VERSION "ZCU_CANFD1"

NS_ :

BS_ :

BU_ :  ASDM BBM ETC IHU ZCUD ZCUP

BO_ 544 AdcuZCUCANFD1Fr14 : 64 ASDM
 SG_ VehObjforADB1_UB : 58|1@0+ (1,0) [0|1] "" IHU,ZCUD
 SG_ VehObjforADB1AdbAbsDist : 7|10@0+ (1.0,0.0) [0.0|1000.0] "m" IHU,ZCUD
 SG_ VehObjforADB1AdbClassn : 13|3@0+ (1,0) [0|7] "" IHU,ZCUD
 SG_ VehObjforADB1AdbHozlAgLe : 10|11@0+ (0.05,-40.0) [-40.0|40.0] "Deg" IHU,ZCUD
 SG_ VehObjforADB1AdbHozlAgRi : 31|11@0+ (0.05,-40.0) [-40.0|40.0] "Deg" IHU,ZCUD
 SG_ VehObjforADB1AdbObjDir : 36|2@0+ (1,0) [0|3] "" IHU,ZCUD
 SG_ VehObjforADB1AdbObjHozlAgSpdLe : 34|9@0+ (0.2,-50.0) [-50.0|52.2] "DegPerSec" IHU,ZCUD
 SG_ VehObjforADB1AdbObjHozlAgSpdRi : 41|9@0+ (0.2,-50.0) [-50.0|52.2] "DegPerSec" IHU,ZCUD
 SG_ VehObjforADB1AdbTrkInfo : 48|1@0+ (1,0) [0|1] "" IHU,ZCUD
 SG_ VehObjforADB1AdbVertAg : 63|5@0+ (0.5,-3.0) [-3.0|12.5] "Deg" IHU,ZCUD
 SG_ VehObjforADB2_UB : 57|1@0+ (1,0) [0|1] "" IHU,ZCUD
 SG_ VehObjforADB2AdbAbsDist : 71|10@0+ (1.0,0.0) [0.0|1000.0] "m" IHU,ZCUD
 SG_ VehObjforADB2AdbClassn : 77|3@0+ (1,0) [0|7] "" IHU,ZCUD
 SG_ VehObjforADB2AdbHozlAgLe : 74|11@0+ (0.05,-40.0) [-40.0|40.0] "Deg" IHU,ZCUD
 SG_ VehObjforADB2AdbHozlAgRi : 95|11@0+ (0.05,-40.0) [-40.0|40.0] "Deg" IHU,ZCUD
 SG_ VehObjforADB2AdbObjDir : 100|2@0+ (1,0) [0|3] "" IHU,ZCUD
 SG_ VehObjforADB2AdbObjHozlAgSpdLe : 98|9@0+ (0.2,-50.0) [-50.0|52.2] "DegPerSec" IHU,ZCUD
 SG_ VehObjforADB2AdbObjHozlAgSpdRi : 105|9@0+ (0.2,-50.0) [-50.0|52.2] "DegPerSec" IHU,ZCUD
 SG_ VehObjforADB2AdbTrkInfo : 112|1@0+ (1,0) [0|1] "" IHU,ZCUD
 SG_ VehObjforADB2AdbVertAg : 127|5@0+ (0.5,-3.0) [-3.0|12.5] "Deg" IHU,ZCUD
 SG_ VehObjforADB3_UB : 56|1@0+ (1,0) [0|1] "" IHU,ZCUD
 SG_ VehObjforADB3AdbAbsDist : 135|10@0+ (1.0,0.0) [0.0|1000.0] "m" IHU,ZCUD
 SG_ VehObjforADB3AdbClassn : 141|3@0+ (1,0) [0|7] "" IHU,ZCUD
 SG_ VehObjforADB3AdbHozlAgLe : 138|11@0+ (0.05,-40.0) [-40.0|40.0] "Deg" IHU,ZCUD
 SG_ VehObjforADB3AdbHozlAgRi : 159|11@0+ (0.05,-40.0) [-40.0|40.0] "Deg" IHU,ZCUD
 SG_ VehObjforADB3AdbObjDir : 164|2@0+ (1,0) [0|3] "" IHU,ZCUD
 SG_ VehObjforADB3AdbObjHozlAgSpdLe : 162|9@0+ (0.2,-50.0) [-50.0|52.2] "DegPerSec" IHU,ZCUD
 SG_ VehObjforADB3AdbObjHozlAgSpdRi : 169|9@0+ (0.2,-50.0) [-50.0|52.2] "DegPerSec" IHU,ZCUD
 SG_ VehObjforADB3AdbTrkInfo : 176|1@0+ (1,0) [0|1] "" IHU,ZCUD
 SG_ VehObjforADB3AdbVertAg : 191|5@0+ (0.5,-3.0) [-3.0|12.5] "Deg" IHU,ZCUD
 SG_ VehObjforADB4_UB : 122|1@0+ (1,0) [0|1] "" IHU,ZCUD
 SG_ VehObjforADB4AdbAbsDist : 199|10@0+ (1.0,0.0) [0.0|1000.0] "m" IHU,ZCUD
 SG_ VehObjforADB4AdbClassn : 205|3@0+ (1,0) [0|7] "" IHU,ZCUD
 SG_ VehObjforADB4AdbHozlAgLe : 202|11@0+ (0.05,-40.0) [-40.0|40.0] "Deg" IHU,ZCUD
 SG_ VehObjforADB4AdbHozlAgRi : 223|11@0+ (0.05,-40.0) [-40.0|40.0] "Deg" IHU,ZCUD
 SG_ VehObjforADB4AdbObjDir : 228|2@0+ (1,0) [0|3] "" IHU,ZCUD
 SG_ VehObjforADB4AdbObjHozlAgSpdLe : 226|9@0+ (0.2,-50.0) [-50.0|52.2] "DegPerSec" IHU,ZCUD
 SG_ VehObjforADB4AdbObjHozlAgSpdRi : 233|9@0+ (0.2,-50.0) [-50.0|52.2] "DegPerSec" IHU,ZCUD
 SG_ VehObjforADB4AdbTrkInfo : 240|1@0+ (1,0) [0|1] "" IHU,ZCUD
 SG_ VehObjforADB4AdbVertAg : 255|5@0+ (0.5,-3.0) [-3.0|12.5] "Deg" IHU,ZCUD
 SG_ VehObjforADB5_UB : 121|1@0+ (1,0) [0|1] "" IHU,ZCUD
 SG_ VehObjforADB5AdbAbsDist : 263|10@0+ (1.0,0.0) [0.0|1000.0] "m" IHU,ZCUD
 SG_ VehObjforADB5AdbClassn : 269|3@0+ (1,0) [0|7] "" IHU,ZCUD
 SG_ VehObjforADB5AdbHozlAgLe : 266|11@0+ (0.05,-40.0) [-40.0|40.0] "Deg" IHU,ZCUD
 SG_ VehObjforADB5AdbHozlAgRi : 287|11@0+ (0.05,-40.0) [-40.0|40.0] "Deg" IHU,ZCUD
 SG_ VehObjforADB5AdbObjDir : 292|2@0+ (1,0) [0|3] "" IHU,ZCUD
 SG_ VehObjforADB5AdbObjHozlAgSpdLe : 290|9@0+ (0.2,-50.0) [-50.0|52.2] "DegPerSec" IHU,ZCUD
 SG_ VehObjforADB5AdbObjHozlAgSpdRi : 297|9@0+ (0.2,-50.0) [-50.0|52.2] "DegPerSec" IHU,ZCUD
 SG_ VehObjforADB5AdbTrkInfo : 304|1@0+ (1,0) [0|1] "" IHU,ZCUD
 SG_ VehObjforADB5AdbVertAg : 319|5@0+ (0.5,-3.0) [-3.0|12.5] "Deg" IHU,ZCUD
 SG_ VehObjforADB6_UB : 120|1@0+ (1,0) [0|1] "" IHU,ZCUD
 SG_ VehObjforADB6AdbAbsDist : 327|10@0+ (1.0,0.0) [0.0|1000.0] "m" IHU,ZCUD
 SG_ VehObjforADB6AdbClassn : 333|3@0+ (1,0) [0|7] "" IHU,ZCUD
 SG_ VehObjforADB6AdbHozlAgLe : 330|11@0+ (0.05,-40.0) [-40.0|40.0] "Deg" IHU,ZCUD
 SG_ VehObjforADB6AdbHozlAgRi : 351|11@0+ (0.05,-40.0) [-40.0|40.0] "Deg" IHU,ZCUD
 SG_ VehObjforADB6AdbObjDir : 356|2@0+ (1,0) [0|3] "" IHU,ZCUD
 SG_ VehObjforADB6AdbObjHozlAgSpdLe : 354|9@0+ (0.2,-50.0) [-50.0|52.2] "DegPerSec" IHU,ZCUD
 SG_ VehObjforADB6AdbObjHozlAgSpdRi : 361|9@0+ (0.2,-50.0) [-50.0|52.2] "DegPerSec" IHU,ZCUD
 SG_ VehObjforADB6AdbTrkInfo : 368|1@0+ (1,0) [0|1] "" IHU,ZCUD
 SG_ VehObjforADB6AdbVertAg : 383|5@0+ (0.5,-3.0) [-3.0|12.5] "Deg" IHU,ZCUD
 SG_ VehObjforADB7_UB : 186|1@0+ (1,0) [0|1] "" IHU,ZCUD
 SG_ VehObjforADB7AdbAbsDist : 391|10@0+ (1.0,0.0) [0.0|1000.0] "m" IHU,ZCUD
 SG_ VehObjforADB7AdbClassn : 397|3@0+ (1,0) [0|7] "" IHU,ZCUD
 SG_ VehObjforADB7AdbHozlAgLe : 394|11@0+ (0.05,-40.0) [-40.0|40.0] "Deg" IHU,ZCUD
 SG_ VehObjforADB7AdbHozlAgRi : 415|11@0+ (0.05,-40.0) [-40.0|40.0] "Deg" IHU,ZCUD
 SG_ VehObjforADB7AdbObjDir : 420|2@0+ (1,0) [0|3] "" IHU,ZCUD
 SG_ VehObjforADB7AdbObjHozlAgSpdLe : 418|9@0+ (0.2,-50.0) [-50.0|52.2] "DegPerSec" IHU,ZCUD
 SG_ VehObjforADB7AdbObjHozlAgSpdRi : 425|9@0+ (0.2,-50.0) [-50.0|52.2] "DegPerSec" IHU,ZCUD
 SG_ VehObjforADB7AdbTrkInfo : 432|1@0+ (1,0) [0|1] "" IHU,ZCUD
 SG_ VehObjforADB7AdbVertAg : 447|5@0+ (0.5,-3.0) [-3.0|12.5] "Deg" IHU,ZCUD
 SG_ VehObjforADB8_UB : 185|1@0+ (1,0) [0|1] "" IHU,ZCUD
 SG_ VehObjforADB8AdbAbsDist : 455|10@0+ (1.0,0.0) [0.0|1000.0] "m" IHU,ZCUD
 SG_ VehObjforADB8AdbClassn : 461|3@0+ (1,0) [0|7] "" IHU,ZCUD
 SG_ VehObjforADB8AdbHozlAgLe : 458|11@0+ (0.05,-40.0) [-40.0|40.0] "Deg" IHU,ZCUD
 SG_ VehObjforADB8AdbHozlAgRi : 479|11@0+ (0.05,-40.0) [-40.0|40.0] "Deg" IHU,ZCUD
 SG_ VehObjforADB8AdbObjDir : 484|2@0+ (1,0) [0|3] "" IHU,ZCUD
 SG_ VehObjforADB8AdbObjHozlAgSpdLe : 482|9@0+ (0.2,-50.0) [-50.0|52.2] "DegPerSec" IHU,ZCUD
 SG_ VehObjforADB8AdbObjHozlAgSpdRi : 489|9@0+ (0.2,-50.0) [-50.0|52.2] "DegPerSec" IHU,ZCUD
 SG_ VehObjforADB8AdbTrkInfo : 496|1@0+ (1,0) [0|1] "" IHU,ZCUD
 SG_ VehObjforADB8AdbVertAg : 511|5@0+ (0.5,-3.0) [-3.0|12.5] "Deg" IHU,ZCUD

BO_ 1129 AdcuZCUCANFD1Fr15 : 64 ASDM
 SG_ FrntRdrSts_UB : 267|1@0+ (1,0) [0|1] "" IHU
 SG_ FrntRdrStsRdrNrDetn : 231|8@0+ (1.0,0.0) [0.0|255.0] "Unitless" IHU
 SG_ FrntRdrStsRdrNrObj : 239|8@0+ (1.0,0.0) [0.0|255.0] "Unitless" IHU
 SG_ FrntRdrStsRdrStsBlkd0bin : 240|1@0+ (1,0) [0|1] "" IHU
 SG_ FrntRdrStsRdrStsBlkdConf : 247|7@0+ (1.0,0.0) [0.0|100.0] "%" IHU
 SG_ FrntRdrStsRdrStsChks : 159|8@0+ (1.0,0.0) [0.0|255.0] "Unitless" IHU
 SG_ FrntRdrStsRdrStsCntr : 167|4@0+ (1.0,0.0) [0.0|15.0] "Unitless" IHU
 SG_ FrntRdrStsRdrStsDstbc : 263|7@0+ (1.0,0.0) [0.0|100.0] "%" IHU
 SG_ FrntRdrStsRdrStsEna : 256|1@0+ (1,0) [0|1] "" IHU
 SG_ FrntRdrStsRdrStsFaulty : 271|1@0+ (1,0) [0|1] "" IHU
 SG_ FrntRdrStsRdrStsIfVersMajor : 163|4@0+ (1.0,0.0) [0.0|15.0] "Unitless" IHU
 SG_ FrntRdrStsRdrStsIfVersMinor : 175|4@0+ (1.0,0.0) [0.0|15.0] "Unitless" IHU
 SG_ FrntRdrStsRdrStsLatency : 215|16@0+ (1.0,0.0) [0.0|65535.0] "Unitless" IHU
 SG_ FrntRdrStsRdrStsMisAlign : 171|3@0+ (1,0) [0|7] "" IHU
 SG_ FrntRdrStsRdrStsMissCom : 168|1@0+ (1,0) [0|1] "" IHU
 SG_ FrntRdrStsRdrStsSftyFlt : 270|2@0+ (1,0) [0|3] "" IHU
 SG_ FrntRdrStsRdrStsTiStamp : 183|32@0+ (0.0001,0.0) [0.0|429496.7295] "s" IHU
 SG_ FrntRdrStsRdrStsTiStampStsGlbTiBas : 268|1@0+ (1,0) [0|1] "" IHU
 SG_ FrntRdrStsRdrStsTiStampStsSyncToGatewy : 248|1@0+ (1,0) [0|1] "" IHU
 SG_ FrntRdrStsRdrStsTiStampStsTiLeap : 249|1@0+ (1,0) [0|1] "" IHU
 SG_ FrntRdrStsRdrStsTiStampStsTiOut : 250|1@0+ (1,0) [0|1] "" IHU
 SG_ FrntRdrStsRdrStsWhlSpdCmpFac : 255|5@0+ (0.005,0.92) [0.92|1.075] "Unitless" IHU
 SG_ ReSideRdrLeSts_UB : 145|1@0+ (1,0) [0|1] "" IHU
 SG_ ReSideRdrLeStsRdrNrDetn : 351|8@0+ (1.0,0.0) [0.0|255.0] "Unitless" IHU
 SG_ ReSideRdrLeStsRdrNrObj : 359|8@0+ (1.0,0.0) [0.0|255.0] "Unitless" IHU
 SG_ ReSideRdrLeStsRdrStsBlkd0bin : 360|1@0+ (1,0) [0|1] "" IHU
 SG_ ReSideRdrLeStsRdrStsBlkdConf : 367|7@0+ (1.0,0.0) [0.0|100.0] "%" IHU
 SG_ ReSideRdrLeStsRdrStsChks : 279|8@0+ (1.0,0.0) [0.0|255.0] "Unitless" IHU
 SG_ ReSideRdrLeStsRdrStsCntr : 287|4@0+ (1.0,0.0) [0.0|15.0] "Unitless" IHU
 SG_ ReSideRdrLeStsRdrStsDstbc : 383|7@0+ (1.0,0.0) [0.0|100.0] "%" IHU
 SG_ ReSideRdrLeStsRdrStsEna : 376|1@0+ (1,0) [0|1] "" IHU
 SG_ ReSideRdrLeStsRdrStsFaulty : 391|1@0+ (1,0) [0|1] "" IHU
 SG_ ReSideRdrLeStsRdrStsIfVersMajor : 283|4@0+ (1.0,0.0) [0.0|15.0] "Unitless" IHU
 SG_ ReSideRdrLeStsRdrStsIfVersMinor : 295|4@0+ (1.0,0.0) [0.0|15.0] "Unitless" IHU
 SG_ ReSideRdrLeStsRdrStsLatency : 335|16@0+ (1.0,0.0) [0.0|65535.0] "Unitless" IHU
 SG_ ReSideRdrLeStsRdrStsMisAlign : 291|3@0+ (1,0) [0|7] "" IHU
 SG_ ReSideRdrLeStsRdrStsMissCom : 288|1@0+ (1,0) [0|1] "" IHU
 SG_ ReSideRdrLeStsRdrStsSftyFlt : 390|2@0+ (1,0) [0|3] "" IHU
 SG_ ReSideRdrLeStsRdrStsTiStamp : 303|32@0+ (0.0001,0.0) [0.0|429496.7295] "s" IHU
 SG_ ReSideRdrLeStsRdrStsTiStampStsGlbTiBas : 388|1@0+ (1,0) [0|1] "" IHU
 SG_ ReSideRdrLeStsRdrStsTiStampStsSyncToGatewy : 368|1@0+ (1,0) [0|1] "" IHU
 SG_ ReSideRdrLeStsRdrStsTiStampStsTiLeap : 369|1@0+ (1,0) [0|1] "" IHU
 SG_ ReSideRdrLeStsRdrStsTiStampStsTiOut : 370|1@0+ (1,0) [0|1] "" IHU
 SG_ ReSideRdrLeStsRdrStsWhlSpdCmpFac : 375|5@0+ (0.005,0.92) [0.92|1.075] "Unitless" IHU
 SG_ ReSideRdrRiSts_UB : 144|1@0+ (1,0) [0|1] "" IHU
 SG_ ReSideRdrRiStsRdrNrDetn : 471|8@0+ (1.0,0.0) [0.0|255.0] "Unitless" IHU
 SG_ ReSideRdrRiStsRdrNrObj : 479|8@0+ (1.0,0.0) [0.0|255.0] "Unitless" IHU
 SG_ ReSideRdrRiStsRdrStsBlkd0bin : 480|1@0+ (1,0) [0|1] "" IHU
 SG_ ReSideRdrRiStsRdrStsBlkdConf : 487|7@0+ (1.0,0.0) [0.0|100.0] "%" IHU
 SG_ ReSideRdrRiStsRdrStsChks : 399|8@0+ (1.0,0.0) [0.0|255.0] "Unitless" IHU
 SG_ ReSideRdrRiStsRdrStsCntr : 407|4@0+ (1.0,0.0) [0.0|15.0] "Unitless" IHU
 SG_ ReSideRdrRiStsRdrStsDstbc : 503|7@0+ (1.0,0.0) [0.0|100.0] "%" IHU
 SG_ ReSideRdrRiStsRdrStsEna : 496|1@0+ (1,0) [0|1] "" IHU
 SG_ ReSideRdrRiStsRdrStsFaulty : 511|1@0+ (1,0) [0|1] "" IHU
 SG_ ReSideRdrRiStsRdrStsIfVersMajor : 403|4@0+ (1.0,0.0) [0.0|15.0] "Unitless" IHU
 SG_ ReSideRdrRiStsRdrStsIfVersMinor : 415|4@0+ (1.0,0.0) [0.0|15.0] "Unitless" IHU
 SG_ ReSideRdrRiStsRdrStsLatency : 455|16@0+ (1.0,0.0) [0.0|65535.0] "Unitless" IHU
 SG_ ReSideRdrRiStsRdrStsMisAlign : 411|3@0+ (1,0) [0|7] "" IHU
 SG_ ReSideRdrRiStsRdrStsMissCom : 408|1@0+ (1,0) [0|1] "" IHU
 SG_ ReSideRdrRiStsRdrStsSftyFlt : 510|2@0+ (1,0) [0|3] "" IHU
 SG_ ReSideRdrRiStsRdrStsTiStamp : 423|32@0+ (0.0001,0.0) [0.0|429496.7295] "s" IHU
 SG_ ReSideRdrRiStsRdrStsTiStampStsGlbTiBas : 508|1@0+ (1,0) [0|1] "" IHU
 SG_ ReSideRdrRiStsRdrStsTiStampStsSyncToGatewy : 488|1@0+ (1,0) [0|1] "" IHU
 SG_ ReSideRdrRiStsRdrStsTiStampStsTiLeap : 489|1@0+ (1,0) [0|1] "" IHU
 SG_ ReSideRdrRiStsRdrStsTiStampStsTiOut : 490|1@0+ (1,0) [0|1] "" IHU
 SG_ ReSideRdrRiStsRdrStsWhlSpdCmpFac : 495|5@0+ (0.005,0.92) [0.92|1.075] "Unitless" IHU

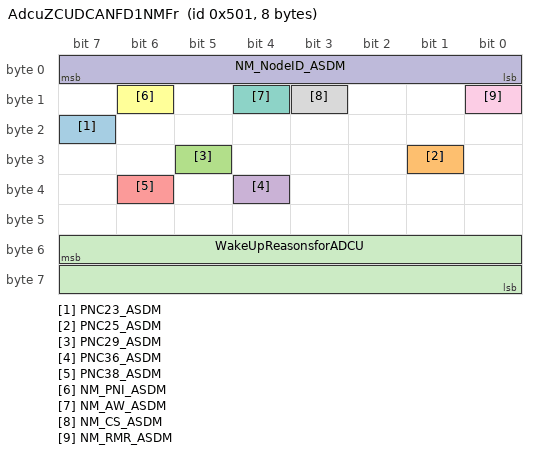
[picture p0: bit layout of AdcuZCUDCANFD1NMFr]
BO_ 1281 AdcuZCUDCANFD1NMFr : 8 ASDM
 SG_ PNC23_ASDM : 23|1@0+ (1,0) [0|0] "" Vector__XXX
 SG_ PNC25_ASDM : 25|1@0+ (1,0) [0|0] "" Vector__XXX
 SG_ PNC29_ASDM : 29|1@0+ (1,0) [0|0] "" Vector__XXX
 SG_ PNC36_ASDM : 36|1@0+ (1,0) [0|0] "" Vector__XXX
 SG_ PNC38_ASDM : 38|1@0+ (1,0) [0|0] "" Vector__XXX
 SG_ NM_PNI_ASDM : 14|1@0+ (1,0) [0|0] "" Vector__XXX
 SG_ NM_AW_ASDM : 12|1@0+ (1,0) [0|0] "" Vector__XXX
 SG_ NM_CS_ASDM : 11|1@0+ (1,0) [0|0] "" Vector__XXX
 SG_ NM_RMR_ASDM : 8|1@0+ (1,0) [0|0] "" Vector__XXX
 SG_ NM_NodeID_ASDM : 7|8@0+ (1,0) [0|0] "" Vector__XXX

 SG_ WakeUpReasonsforADCU : 55|16@0+ (1,0) [0|65535] "" Vector__XXX

BO_ 341 AdcuZCUDCANFD1SycnReqFr : 1 ASDM
 SG_ TripResetSyncReqMsgASDM : 7|8@0+ (1.0,0.0) [0.0|255.0] "Unitless" IHU

BO_ 1604 AsdmFlrToDhuZCUCANFD1DiagResFr : 64 ASDM

BO_ 1585 AsdmFsrlToDhuZCUCANFD1DiagResFr : 64 ASDM

BO_ 1584 AsdmFsrrToDhuZCUCANFD1DiagResFr : 64 ASDM

BO_ 1616 AsdmSodlToDhuZCUCANFD1DiagResFr : 64 ASDM

BO_ 1617 AsdmSodrToDhuZCUCANFD1DiagResFr : 64 ASDM

BO_ 1537 AsdmToDhuZCUCANFD1DiagResFr : 64 ASDM

BO_ 1345 AsdmZCUCANFD1VFCVectFr : 8 ASDM
 SG_ VFCVectorASDMBlockID : 1|2@0+ (1.0,0.0) [0.0|3.0] "Unitless" IHU
 SG_ VFCVectorASDMVFCid0 : 2|1@0+ (1,0) [0|1] "" IHU
 SG_ VFCVectorASDMVFCid1 : 3|1@0+ (1,0) [0|1] "" IHU
 SG_ VFCVectorASDMVFCid10 : 12|1@0+ (1,0) [0|1] "" IHU
 SG_ VFCVectorASDMVFCid11 : 13|1@0+ (1,0) [0|1] "" IHU
 SG_ VFCVectorASDMVFCid12 : 14|1@0+ (1,0) [0|1] "" IHU
 SG_ VFCVectorASDMVFCid13 : 15|1@0+ (1,0) [0|1] "" IHU
 SG_ VFCVectorASDMVFCid14 : 16|1@0+ (1,0) [0|1] "" IHU
 SG_ VFCVectorASDMVFCid15 : 17|1@0+ (1,0) [0|1] "" IHU
 SG_ VFCVectorASDMVFCid16 : 18|1@0+ (1,0) [0|1] "" IHU
 SG_ VFCVectorASDMVFCid17 : 19|1@0+ (1,0) [0|1] "" IHU
 SG_ VFCVectorASDMVFCid18 : 20|1@0+ (1,0) [0|1] "" IHU
 SG_ VFCVectorASDMVFCid19 : 21|1@0+ (1,0) [0|1] "" IHU
 SG_ VFCVectorASDMVFCid2 : 4|1@0+ (1,0) [0|1] "" IHU
 SG_ VFCVectorASDMVFCid20 : 22|1@0+ (1,0) [0|1] "" IHU
 SG_ VFCVectorASDMVFCid21 : 23|1@0+ (1,0) [0|1] "" IHU
 SG_ VFCVectorASDMVFCid22 : 24|1@0+ (1,0) [0|1] "" IHU
 SG_ VFCVectorASDMVFCid23 : 25|1@0+ (1,0) [0|1] "" IHU
 SG_ VFCVectorASDMVFCid24 : 26|1@0+ (1,0) [0|1] "" IHU
 SG_ VFCVectorASDMVFCid25 : 27|1@0+ (1,0) [0|1] "" IHU
 SG_ VFCVectorASDMVFCid26 : 28|1@0+ (1,0) [0|1] "" IHU
 SG_ VFCVectorASDMVFCid27 : 29|1@0+ (1,0) [0|1] "" IHU
 SG_ VFCVectorASDMVFCid28 : 30|1@0+ (1,0) [0|1] "" IHU
 SG_ VFCVectorASDMVFCid29 : 31|1@0+ (1,0) [0|1] "" IHU
 SG_ VFCVectorASDMVFCid3 : 5|1@0+ (1,0) [0|1] "" IHU
 SG_ VFCVectorASDMVFCid30 : 32|1@0+ (1,0) [0|1] "" IHU
 SG_ VFCVectorASDMVFCid31 : 33|1@0+ (1,0) [0|1] "" IHU
 SG_ VFCVectorASDMVFCid32 : 34|1@0+ (1,0) [0|1] "" IHU
 SG_ VFCVectorASDMVFCid33 : 35|1@0+ (1,0) [0|1] "" IHU
 SG_ VFCVectorASDMVFCid34 : 36|1@0+ (1,0) [0|1] "" IHU
 SG_ VFCVectorASDMVFCid35 : 37|1@0+ (1,0) [0|1] "" IHU
 SG_ VFCVectorASDMVFCid36 : 38|1@0+ (1,0) [0|1] "" IHU
 SG_ VFCVectorASDMVFCid37 : 39|1@0+ (1,0) [0|1] "" IHU
 SG_ VFCVectorASDMVFCid38 : 40|1@0+ (1,0) [0|1] "" IHU
 SG_ VFCVectorASDMVFCid39 : 41|1@0+ (1,0) [0|1] "" IHU
 SG_ VFCVectorASDMVFCid4 : 6|1@0+ (1,0) [0|1] "" IHU
 SG_ VFCVectorASDMVFCid40 : 42|1@0+ (1,0) [0|1] "" IHU
 SG_ VFCVectorASDMVFCid41 : 43|1@0+ (1,0) [0|1] "" IHU
 SG_ VFCVectorASDMVFCid42 : 44|1@0+ (1,0) [0|1] "" IHU
 SG_ VFCVectorASDMVFCid43 : 45|1@0+ (1,0) [0|1] "" IHU
 SG_ VFCVectorASDMVFCid44 : 46|1@0+ (1,0) [0|1] "" IHU
 SG_ VFCVectorASDMVFCid45 : 47|1@0+ (1,0) [0|1] "" IHU
 SG_ VFCVectorASDMVFCid46 : 48|1@0+ (1,0) [0|1] "" IHU
 SG_ VFCVectorASDMVFCid47 : 49|1@0+ (1,0) [0|1] "" IHU
 SG_ VFCVectorASDMVFCid48 : 50|1@0+ (1,0) [0|1] "" IHU
 SG_ VFCVectorASDMVFCid49 : 51|1@0+ (1,0) [0|1] "" IHU
 SG_ VFCVectorASDMVFCid5 : 7|1@0+ (1,0) [0|1] "" IHU
 SG_ VFCVectorASDMVFCid50 : 52|1@0+ (1,0) [0|1] "" IHU
 SG_ VFCVectorASDMVFCid51 : 53|1@0+ (1,0) [0|1] "" IHU
 SG_ VFCVectorASDMVFCid52 : 54|1@0+ (1,0) [0|1] "" IHU
 SG_ VFCVectorASDMVFCid53 : 55|1@0+ (1,0) [0|1] "" IHU
 SG_ VFCVectorASDMVFCid54 : 56|1@0+ (1,0) [0|1] "" IHU
 SG_ VFCVectorASDMVFCid55 : 57|1@0+ (1,0) [0|1] "" IHU
 SG_ VFCVectorASDMVFCid56 : 58|1@0+ (1,0) [0|1] "" IHU
 SG_ VFCVectorASDMVFCid57 : 59|1@0+ (1,0) [0|1] "" IHU
 SG_ VFCVectorASDMVFCid58 : 60|1@0+ (1,0) [0|1] "" IHU
 SG_ VFCVectorASDMVFCid59 : 61|1@0+ (1,0) [0|1] "" IHU
 SG_ VFCVectorASDMVFCid6 : 8|1@0+ (1,0) [0|1] "" IHU
 SG_ VFCVectorASDMVFCid60 : 62|1@0+ (1,0) [0|1] "" IHU
 SG_ VFCVectorASDMVFCid61 : 63|1@0+ (1,0) [0|1] "" IHU
 SG_ VFCVectorASDMVFCid7 : 9|1@0+ (1,0) [0|1] "" IHU
 SG_ VFCVectorASDMVFCid8 : 10|1@0+ (1,0) [0|1] "" IHU
 SG_ VFCVectorASDMVFCid9 : 11|1@0+ (1,0) [0|1] "" IHU

BO_ 2031 BcmToDhuJ1979OBDZCUCanFD1DiagResFr : 8 BBM

BO_ 1665 BcmToDhuZCUCANFD1DiagResFr : 64 BBM

BO_ 257 BcmZCUCANFD1Fr01 : 64 BBM
 SG_ AbsCtrlActv_UB : 10|1@0+ (1,0) [0|1] "" ASDM,IHU,ZCUD
 SG_ AbsCtrlActvChks : 7|8@0+ (1.0,0.0) [0.0|255.0] "Unitless" ASDM,IHU,ZCUD
 SG_ AbsCtrlActvCntr : 15|4@0+ (1.0,0.0) [0.0|15.0] "Unitless" ASDM,IHU,ZCUD
 SG_ AbsCtrlActvCtrlSts1 : 11|1@0+ (1,0) [0|1] "" ASDM,IHU,ZCUD
 SG_ AsyALgtCtrlModCfmd_UB : 9|1@0+ (1,0) [0|1] "" ASDM,IHU
 SG_ AsyALgtCtrlModCfmdAsyALgtCtrlMod1 : 23|4@0+ (1,0) [0|15] "" ASDM,IHU
 SG_ AsyALgtCtrlModCfmdChks : 31|8@0+ (1.0,0.0) [0.0|255.0] "Unitless" ASDM,IHU
 SG_ AsyALgtCtrlModCfmdCntr : 19|4@0+ (1.0,0.0) [0.0|15.0] "Unitless" ASDM,IHU
 SG_ AutHldAvlSt : 39|1@0+ (1,0) [0|1] "" IHU
 SG_ AutHldAvlSt_UB : 38|1@0+ (1,0) [0|1] "" IHU
 SG_ AxleSlipRelAct : 37|14@0- (0.003906369,0.0) [-29.997007551|30.00091392] "m/s" IHU
 SG_ AxleSlipRelAct_UB : 8|1@0+ (1,0) [0|1] "" IHU
 SG_ BrkFricTqAtWhlAct_UB : 106|1@0+ (1,0) [0|1] "" IHU
 SG_ BrkFricTqAtWhlActBrkFricTqAtWhlFrntLeAct : 55|13@0+ (1.0,0.0) [0.0|8191.0] "Nm" IHU
 SG_ BrkFricTqAtWhlActBrkFricTqAtWhlFrntRiAct : 71|13@0+ (1.0,0.0) [0.0|8191.0] "Nm" IHU
 SG_ BrkFricTqAtWhlActBrkFricTqAtWhlReLeAct : 87|13@0+ (1.0,0.0) [0.0|8191.0] "Nm" IHU
 SG_ BrkFricTqAtWhlActBrkFricTqAtWhlReRiAct : 103|13@0+ (1.0,0.0) [0.0|8191.0] "Nm" IHU
 SG_ BrkTq_UB : 105|1@0+ (1,0) [0|1] "" IHU
 SG_ BrkTqAtWhlsReq : 167|12@0+ (4.0,0.0) [0.0|16380.0] "Nm" IHU
 SG_ BrkTqAtWhlsReq_UB : 152|1@0+ (1,0) [0|1] "" IHU
 SG_ BrkTqChks : 119|8@0+ (1.0,0.0) [0.0|255.0] "Unitless" IHU
 SG_ BrkTqCntr : 127|4@0+ (1.0,0.0) [0.0|15.0] "Unitless" IHU
 SG_ BrkTqQf : 123|2@0+ (1,0) [0|3] "" IHU
 SG_ BrkTqRgnAtAxleReReq : 135|15@0- (1.0,0.0) [-16384.0|16380.0] "NewtonMeter" IHU
 SG_ BrkTqSts : 121|1@0+ (1,0) [0|1] "" IHU
 SG_ BrkTqTotReqForPt : 151|15@0- (1.0,0.0) [-16384.0|16380.0] "NewtonMeter" IHU
 SG_ DrvrBrkTqAtWhlsReqd_UB : 205|1@0+ (1,0) [0|1] "" IHU
 SG_ DrvrBrkTqAtWhlsReqdChks : 183|8@0+ (1.0,0.0) [0.0|255.0] "Unitless" IHU
 SG_ DrvrBrkTqAtWhlsReqdCntr : 171|4@0+ (1.0,0.0) [0.0|15.0] "Unitless" IHU
 SG_ DrvrBrkTqAtWhlsReqdDrvrBrkTqAtWhlsReqd : 191|16@0- (1.0,0.0) [-20000.0|20000.0] "NewtonMeter" IHU
 SG_ DrvrBrkTqAtWhlsReqdQf : 207|2@0+ (1,0) [0|3] "" IHU
 SG_ EscVariantToDmc_UB : 204|1@0+ (1,0) [0|1] "" IHU,ZCUD
 SG_ EscVariantToDmcChks : 215|8@0+ (1.0,0.0) [0.0|255.0] "Unitless" IHU,ZCUD
 SG_ EscVariantToDmcCntr : 203|4@0+ (1.0,0.0) [0.0|15.0] "Unitless" IHU,ZCUD
 SG_ EscVariantToDmcEscVariantToDmc : 223|8@0+ (1.0,0.0) [0.0|255.0] "Unitless" IHU,ZCUD
 SG_ FricEstimnFromVehDyn_UB : 236|1@0+ (1,0) [0|1] "" ASDM,IHU
 SG_ FricEstimnFromVehDynFricEstimnFromVehDyn : 231|8@0+ (0.01,0.0) [0.0|2.0] "Unitless" ASDM,IHU
 SG_ FricEstimnFromVehDynQly : 239|3@0+ (1,0) [0|7] "" ASDM,IHU
 SG_ LatCtrlReqSafe_UB : 235|1@0+ (1,0) [0|1] "" IHU
 SG_ LatCtrlReqSafeChks : 247|8@0+ (1.0,0.0) [0.0|255.0] "Unitless" IHU
 SG_ LatCtrlReqSafeCntr : 255|4@0+ (1.0,0.0) [0.0|15.0] "Unitless" IHU
 SG_ LatCtrlReqSafeLatCtrlModReq : 251|4@0+ (1,0) [0|15] "" IHU
 SG_ LatCtrlReqSafeSteerTqReq : 263|14@0- (0.00390625,0.0) [-30.0|30.0] "NewtonMeter" IHU
 SG_ LatCtrlReqSafeSteerWhlHptcWarnReq : 265|1@0+ (1,0) [0|1] "" IHU
 SG_ LgtCtrlModReqSafe_UB : 264|1@0+ (1,0) [0|1] "" IHU
 SG_ LgtCtrlModReqSafeChks : 279|8@0+ (1.0,0.0) [0.0|255.0] "Unitless" IHU
 SG_ LgtCtrlModReqSafeCntr : 287|4@0+ (1.0,0.0) [0.0|15.0] "Unitless" IHU
 SG_ LgtCtrlModReqSafeLgtCtrlModReqSafe : 283|4@0+ (1,0) [0|15] "" IHU
 SG_ LgtCtrlModReqSafeLgtFctFailr : 295|3@0+ (1,0) [0|7] "" IHU
 SG_ PrpsnTqForBrkRels : 303|15@0+ (1.0,0.0) [0.0|20000.0] "NewtonMeter" IHU
 SG_ PrpsnTqForBrkRels_UB : 292|1@0+ (1,0) [0|1] "" IHU
 SG_ PtTqAtAxleMinReq_UB : 355|1@0+ (1,0) [0|1] "" IHU
 SG_ PtTqAtAxleMinReqChks : 367|8@0+ (1.0,0.0) [0.0|255.0] "Unitless" IHU
 SG_ PtTqAtAxleMinReqCntr : 407|4@0+ (1.0,0.0) [0.0|15.0] "Unitless" IHU
 SG_ PtTqAtAxleMinReqPtTqAtAxleFrntReq : 375|16@0- (1.0,0.0) [-20000.0|20000.0] "NewtonMeter" IHU
 SG_ PtTqAtAxleMinReqPtTqAtAxleReReq : 391|16@0- (1.0,0.0) [-20000.0|20000.0] "NewtonMeter" IHU
 SG_ PtTqAtAxleReMinSlowReq : 415|16@0- (1.0,0.0) [-20000.0|20000.0] "NewtonMeter" IHU
 SG_ PtTqAtAxleReMinSlowReq_UB : 354|1@0+ (1,0) [0|1] "" IHU
 SG_ PtTqSoftMaxGenn2_UB : 403|1@0+ (1,0) [0|1] "" IHU
 SG_ PtTqSoftMaxGenn2Allwd : 439|13@0- (4.0,0.0) [-16384.0|16380.0] "NewtonMeter" IHU
 SG_ PtTqSoftMaxGenn2AllwdChks : 431|8@0+ (1.0,0.0) [0.0|255.0] "Unitless" IHU
 SG_ PtTqSoftMaxGenn2AllwdCntr : 455|4@0+ (1.0,0.0) [0.0|15.0] "Unitless" IHU
 SG_ StcStsToDmc_UB : 402|1@0+ (1,0) [0|1] "" IHU,ZCUD
 SG_ StcStsToDmcChks : 511|8@0+ (1.0,0.0) [0.0|255.0] "Unitless" IHU,ZCUD
 SG_ StcStsToDmcCntr : 451|4@0+ (1.0,0.0) [0.0|15.0] "Unitless" IHU,ZCUD
 SG_ StcStsToDmcEngRotTarSpdDMCFrnt : 463|16@0- (1.0,0.0) [-32768.0|32767.0] "Unitless" IHU,ZCUD
 SG_ StcStsToDmcEngRotTarSpdDMCRear : 479|16@0- (1.0,0.0) [-32768.0|32767.0] "Unitless" IHU,ZCUD
 SG_ StcStsToDmcFrnt : 495|8@0+ (1,0) [0|255] "" IHU,ZCUD
 SG_ StcStsToDmcRear : 503|8@0+ (1,0) [0|255] "" IHU,ZCUD
 SG_ SteerAssiCtrlSts : 353|2@0+ (1,0) [0|3] "" IHU
 SG_ SteerAssiCtrlSts_UB : 401|1@0+ (1,0) [0|1] "" IHU
 SG_ TqRednDurgCllsnMtgtnByBrkg : 234|2@0+ (1,0) [0|3] "" IHU
 SG_ TqRednDurgCllsnMtgtnByBrkg_UB : 232|1@0+ (1,0) [0|1] "" IHU

BO_ 1025 BcmZCUCANFD1Fr02 : 64 BBM
 SG_ AbsCtrlActvForWhl_UB : 2|1@0+ (1,0) [0|1] "" IHU
 SG_ AbsCtrlActvForWhlFrntLe : 6|1@0+ (1,0) [0|1] "" IHU
 SG_ AbsCtrlActvForWhlFrntRi : 5|1@0+ (1,0) [0|1] "" IHU
 SG_ AbsCtrlActvForWhlReLe : 4|1@0+ (1,0) [0|1] "" IHU
 SG_ AbsCtrlActvForWhlReRi : 3|1@0+ (1,0) [0|1] "" IHU
 SG_ ALgtStdFromWhlSpd_UB : 185|1@0+ (1,0) [0|1] "" IHU
 SG_ ALgtStdFromWhlSpdALgtStdFromWhlSpd : 167|16@0- (0.0009765625,0.0) [-18.0|18.0] "m/s^2" IHU
 SG_ ALgtStdFromWhlSpdChks : 183|8@0+ (1.0,0.0) [0.0|255.0] "Unitless" IHU
 SG_ ALgtStdFromWhlSpdCntr : 191|4@0+ (1.0,0.0) [0.0|15.0] "Unitless" IHU
 SG_ ALgtStdFromWhlSpdQf : 187|2@0+ (1,0) [0|3] "" IHU
 SG_ BrkPAtWhl_UB : 63|1@0+ (1,0) [0|1] "" IHU
 SG_ BrkPAtWhlFL : 31|8@0+ (1.0,0.0) [0.0|180.0] "bar" IHU
 SG_ BrkPAtWhlFR : 39|8@0+ (1.0,0.0) [0.0|180.0] "bar" IHU
 SG_ BrkPAtWhlRL : 47|8@0+ (1.0,0.0) [0.0|180.0] "bar" IHU
 SG_ BrkPAtWhlRR : 55|8@0+ (1.0,0.0) [0.0|180.0] "bar" IHU
 SG_ PitchAgGlb_UB : 81|1@0+ (1,0) [0|1] "" IHU
 SG_ PitchAgGlbQf : 111|2@0+ (1,0) [0|3] "" IHU
 SG_ PitchAgGlbVal : 95|16@0- (0.000030518,0.0) [-0.9999833060000001|0.9999833060000001] "rad" IHU
 SG_ RoadLoadNom_UB : 109|1@0+ (1,0) [0|1] "" IHU
 SG_ RoadLoadNomCoeff0 : 106|11@0+ (1.0,0.0) [0.0|2047.0] "N" IHU
 SG_ RoadLoadNomCoeff1 : 127|10@0- (0.05859,0.0) [-29.8809|29.939490000000003] "Ns/m" IHU
 SG_ RoadLoadNomCoeff2 : 132|10@0+ (0.002929,0.0) [0.0|2.902639] "Ns^2/m^2" IHU
 SG_ RoadLoadNomCoeffSts : 133|1@0+ (1,0) [0|1] "" IHU
 SG_ StandStillMgrStsForHldByBrk_UB : 80|1@0+ (1,0) [0|1] "" IHU
 SG_ StandStillMgrStsForHldByBrkChks : 151|8@0+ (1.0,0.0) [0.0|255.0] "Unitless" IHU
 SG_ StandStillMgrStsForHldByBrkCntr : 159|4@0+ (1.0,0.0) [0.0|15.0] "Unitless" IHU
 SG_ StandStillMgrStsForHldByBrkStandStillMgrStsForHld1 : 155|3@0+ (1,0) [0|7] "" IHU
 SG_ StandStillMgrStsForPark : 108|2@0+ (1,0) [0|3] "" IHU
 SG_ StandStillMgrStsForPark_UB : 152|1@0+ (1,0) [0|1] "" IHU
 SG_ TrlrModBCSts : 137|2@0+ (1,0) [0|3] "" IHU
 SG_ TrlrModBCSts_UB : 138|1@0+ (1,0) [0|1] "" IHU
 SG_ YawStabyCtrlActv : 60|1@0+ (1,0) [0|1] "" IHU
 SG_ YawStabyCtrlActv_UB : 59|1@0+ (1,0) [0|1] "" IHU

BO_ 483 BcmZCUCANFD1Fr03 : 64 BBM
 SG_ AbsSts : 5|1@0+ (1,0) [0|1] "" ASDM,IHU,ZCUD
 SG_ AbsSts_UB : 4|1@0+ (1,0) [0|1] "" ASDM,IHU,ZCUD
 SG_ AsyActrActvForLgtCtrl : 7|2@0+ (1,0) [0|3] "" ASDM,IHU
 SG_ AsyActrActvForLgtCtrl_UB : 3|1@0+ (1,0) [0|1] "" ASDM,IHU
 SG_ AsySftyDecelEnadByVehDyn : 1|1@0+ (1,0) [0|1] "" ASDM,IHU
 SG_ AsySftyDecelEnadByVehDyn_UB : 0|1@0+ (1,0) [0|1] "" ASDM,IHU
 SG_ AsySftyEnaDecelAckd : 31|1@0+ (1,0) [0|1] "" ASDM,IHU
 SG_ AsySftyEnaDecelAckd_UB : 30|1@0+ (1,0) [0|1] "" ASDM,IHU
 SG_ BrkPedlrRat_UB : 40|1@0+ (1,0) [0|1] "" ASDM,IHU,ZCUD
 SG_ BrkPedlrRatPerc : 39|15@0+ (0.00390625,0.0) [0.0|100.0] "%" ASDM,IHU,ZCUD
 SG_ BrkPedlrRatQf : 25|2@0+ (1,0) [0|3] "" ASDM,IHU,ZCUD
 SG_ EscActvCtrlIndcdToDrvr : 29|1@0+ (1,0) [0|1] "" IHU
 SG_ EscActvCtrlIndcdToDrvr_UB : 28|1@0+ (1,0) [0|1] "" IHU
 SG_ HsaSt : 27|1@0+ (1,0) [0|1] "" IHU
 SG_ HsaSt_UB : 26|1@0+ (1,0) [0|1] "" IHU
 SG_ InhbOfAsySftyDecelByVehDyn : 55|1@0+ (1,0) [0|1] "" ASDM,IHU
 SG_ InhbOfAsySftyDecelByVehDyn_UB : 54|1@0+ (1,0) [0|1] "" ASDM,IHU
 SG_ LimForDecel_UB : 49|1@0+ (1,0) [0|1] "" IHU
 SG_ LimForDecelChks : 63|8@0+ (1.0,0.0) [0.0|255.0] "Unitless" IHU
 SG_ LimForDecelCntr : 71|4@0+ (1.0,0.0) [0.0|15.0] "Unitless" IHU
 SG_ LimForDecelNotExcd : 67|1@0+ (1,0) [0|1] "" IHU
 SG_ MsgReqByHillDwnCtrl : 53|3@0+ (1,0) [0|7] "" ASDM,IHU
 SG_ MsgReqByHillDwnCtrl_UB : 50|1@0+ (1,0) [0|1] "" ASDM,IHU
 SG_ RctaBrkActvd : 119|1@0+ (1,0) [0|1] "" ASDM,IHU
 SG_ RctaBrkActvd_UB : 118|1@0+ (1,0) [0|1] "" ASDM,IHU
 SG_ RcwmBrkActvd : 117|1@0+ (1,0) [0|1] "" ASDM,IHU
 SG_ RcwmBrkActvd_UB : 116|1@0+ (1,0) [0|1] "" ASDM,IHU
 SG_ SuspPosnVertAg_UB : 102|1@0+ (1,0) [0|1] "" IHU,ZCUD
 SG_ SuspPosnVertAgGenQf : 101|2@0+ (1,0) [0|3] "" IHU,ZCUD
 SG_ SuspPosnVertAgSuspPosnVertAg : 99|12@0- (0.000127894181,0.0) [-0.26167149432599995|0.26179938850699996] "rad" IHU,ZCUD
 SG_ SuspPosnVertLvl_UB : 103|1@0+ (1,0) [0|1] "" IHU,ZCUD
 SG_ SuspPosnVertLvlFrnt : 126|15@0- (0.000062,0.0) [-0.999998|1.00006] "m" IHU,ZCUD
 SG_ SuspPosnVertLvlFrntQf : 113|2@0+ (1,0) [0|3] "" IHU,ZCUD
 SG_ SuspPosnVertLvlRe : 142|15@0- (0.000062,0.0) [-0.999998|1.00006] "m" IHU,ZCUD
 SG_ SuspPosnVertLvlReQf : 115|2@0+ (1,0) [0|3] "" IHU,ZCUD
 SG_ WhlBrkOvrheatd : 66|1@0+ (1,0) [0|1] "" IHU
 SG_ WhlBrkOvrheatd_UB : 65|1@0+ (1,0) [0|1] "" IHU
 SG_ WhlSpdCalcALgt_UB : 64|1@0+ (1,0) [0|1] "" IHU
 SG_ WhlSpdCalcALgtALgt : 79|12@0- (0.0059,0.0) [-11.9947|12.0006] "m/s^2" IHU
 SG_ WhlSpdCalcALgtChks : 95|8@0+ (1.0,0.0) [0.0|255.0] "Unitless" IHU
 SG_ WhlSpdCalcALgtCntr : 83|4@0+ (1.0,0.0) [0.0|15.0] "Unitless" IHU

BO_ 816 BcmZCUCANFD1Fr04 : 64 BBM
 SG_ AbsClrRdyReq : 7|1@0+ (1,0) [0|1] "" IHU
 SG_ AbsClrRdyReq_UB : 6|1@0+ (1,0) [0|1] "" IHU
 SG_ BrkTracCtrlActvForWhl_UB : 1|1@0+ (1,0) [0|1] "" IHU
 SG_ BrkTracCtrlActvForWhlFrntLe : 5|1@0+ (1,0) [0|1] "" IHU
 SG_ BrkTracCtrlActvForWhlFrntRi : 4|1@0+ (1,0) [0|1] "" IHU
 SG_ BrkTracCtrlActvForWhlReLe : 3|1@0+ (1,0) [0|1] "" IHU
 SG_ BrkTracCtrlActvForWhlReRi : 2|1@0+ (1,0) [0|1] "" IHU
 SG_ EpbLampReq_UB : 0|1@0+ (1,0) [0|1] "" IHU,ZCUD
 SG_ EpbLampReqChks : 15|8@0+ (1.0,0.0) [0.0|255.0] "Unitless" IHU,ZCUD
 SG_ EpbLampReqCntr : 23|4@0+ (1.0,0.0) [0.0|15.0] "Unitless" IHU,ZCUD
 SG_ EpbLampReqEpbLampReq : 19|2@0+ (1,0) [0|3] "" IHU,ZCUD
 SG_ RollAgGlb_UB : 16|1@0+ (1,0) [0|1] "" IHU,ZCUD
 SG_ RollAgGlbQf : 63|2@0+ (1,0) [0|3] "" IHU,ZCUD
 SG_ RollAgGlbVal : 47|16@0- (0.000030518,0.0) [-0.9999833060000001|0.9999833060000001] "rad" IHU,ZCUD

BO_ 800 BcmZCUCANFD1Fr05 : 64 BBM
 SG_ AbsErrIndcnReq : 7|1@0+ (1,0) [0|1] "" IHU
 SG_ AbsErrIndcnReq_UB : 6|1@0+ (1,0) [0|1] "" IHU
 SG_ PostImpctBrkgRdy : 5|2@0+ (1,0) [0|3] "" IHU,ZCUD
 SG_ PostImpctBrkgRdy_UB : 3|1@0+ (1,0) [0|1] "" IHU,ZCUD
 SG_ WhlBrkWrm : 2|1@0+ (1,0) [0|1] "" IHU
 SG_ WhlBrkWrm_UB : 1|1@0+ (1,0) [0|1] "" IHU

BO_ 384 BcmZCUCANFD1Fr06 : 64 BBM
 SG_ AsyALgtActvAftLim : 7|10@0- (0.01,0.0) [-5.12|5.11] "m/s^2" ASDM,IHU
 SG_ AsyALgtActvAftLim_UB : 13|1@0+ (1,0) [0|1] "" ASDM,IHU
 SG_ BrkFricTqTotAtWhlsAct_UB : 12|1@0+ (1,0) [0|1] "" IHU
 SG_ BrkFricTqTotAtWhlsActBrkFricTqTotAtWhlsAct : 23|15@0+ (1.0,0.0) [0.0|20000.0] "NewtonMeter" IHU
 SG_ BrkFricTqTotAtWhlsActChks : 39|8@0+ (1.0,0.0) [0.0|255.0] "Unitless" IHU
 SG_ BrkFricTqTotAtWhlsActCntr : 47|4@0+ (1.0,0.0) [0.0|15.0] "Unitless" IHU
 SG_ BrkPedlPsd_UB : 11|1@0+ (1,0) [0|1] "" ASDM,IHU,ZCUD
 SG_ BrkPedlPsdBrkPedlNotPsdSafe : 43|1@0+ (1,0) [0|1] "" ASDM,IHU,ZCUD
 SG_ BrkPedlPsdBrkPedlPsd : 42|1@0+ (1,0) [0|1] "" ASDM,IHU,ZCUD
 SG_ BrkPedlPsdChks : 55|8@0+ (1.0,0.0) [0.0|255.0] "Unitless" ASDM,IHU,ZCUD
 SG_ BrkPedlPsdCntr : 63|4@0+ (1.0,0.0) [0.0|15.0] "Unitless" ASDM,IHU,ZCUD
 SG_ BrkPedlPsdQf : 41|2@0+ (1,0) [0|3] "" ASDM,IHU,ZCUD
 SG_ BrkPedlTrvl_UB : 10|1@0+ (1,0) [0|1] "" IHU
 SG_ BrkPedlTrvlAct : 71|13@0+ (0.01,-5.0) [-5.0|47.0] "mm" IHU
 SG_ BrkPedlTrvlChks : 87|8@0+ (1.0,0.0) [0.0|255.0] "Unitless" IHU
 SG_ BrkPedlTrvlCntr : 95|4@0+ (1.0,0.0) [0.0|15.0] "Unitless" IHU
 SG_ BrkPedlTrvlQf : 74|2@0+ (1,0) [0|3] "" IHU
 SG_ BrkPedlTrvlSt : 72|1@0+ (1,0) [0|1] "" IHU
 SG_ BrkPedlTrvlStQf : 91|2@0+ (1,0) [0|3] "" IHU
 SG_ BrkPedlTrvlTar : 103|13@0+ (0.01,-5.0) [-5.0|47.0] "mm" IHU
 SG_ BrkSysCylPMst_UB : 106|1@0+ (1,0) [0|1] "" ASDM,IHU,ZCUD
 SG_ BrkSysCylPMstAct : 105|10@0+ (0.3,-30.0) [-30.0|276.59999999999997] "bar" ASDM,IHU,ZCUD
 SG_ BrkSysCylPMstActQf : 127|2@0+ (1,0) [0|3] "" ASDM,IHU,ZCUD
 SG_ BrkSysCylPMstChks : 135|8@0+ (1.0,0.0) [0.0|255.0] "Unitless" ASDM,IHU,ZCUD
 SG_ BrkSysCylPMstCntr : 125|4@0+ (1.0,0.0) [0.0|15.0] "Unitless" ASDM,IHU,ZCUD
 SG_ BrkSysCylPMstTar : 143|10@0+ (0.25,0.0) [0.0|250.0] "bar" ASDM,IHU,ZCUD
 SG_ BrkSysCylPMstVirt : 149|10@0+ (0.25,0.0) [0.0|250.0] "bar" ASDM,IHU,ZCUD
 SG_ BrkSysCylPMstVirtQf : 121|2@0+ (1,0) [0|3] "" ASDM,IHU,ZCUD
 SG_ DrvrDecelReq_UB : 155|1@0+ (1,0) [0|1] "" ASDM,IHU
 SG_ DrvrDecelReqChks : 167|8@0+ (1.0,0.0) [0.0|255.0] "Unitless" ASDM,IHU
 SG_ DrvrDecelReqCntr : 183|4@0+ (1.0,0.0) [0.0|15.0] "Unitless" ASDM,IHU
 SG_ DrvrDecelReqFloat8 : 175|8@0- (0.1,0.0) [-12.8|12.700000000000001] "m/s^2" ASDM,IHU
 SG_ EngRunngReqByBrk : 153|2@0+ (1,0) [0|3] "" IHU
 SG_ EngRunngReqByBrk_UB : 154|1@0+ (1,0) [0|1] "" IHU
 SG_ EpbActrStPrim : 179|3@0+ (1,0) [0|7] "" IHU
 SG_ EpbActrStPrim_UB : 176|1@0+ (1,0) [0|1] "" IHU
 SG_ EpbSts_UB : 9|1@0+ (1,0) [0|1] "" ASDM,IHU,ZCUD
 SG_ EpbStsChks : 191|8@0+ (1.0,0.0) [0.0|255.0] "Unitless" ASDM,IHU,ZCUD
 SG_ EpbStsCntr : 199|4@0+ (1.0,0.0) [0.0|15.0] "Unitless" ASDM,IHU,ZCUD
 SG_ EpbStsEpbSts : 195|4@0+ (1,0) [0|15] "" ASDM,IHU,ZCUD
 SG_ EscCtrlIndcn : 207|2@0+ (1,0) [0|3] "" ASDM,IHU,ZCUD
 SG_ EscCtrlIndcn_UB : 8|1@0+ (1,0) [0|1] "" ASDM,IHU,ZCUD
 SG_ EscGearShiftInhbReq : 205|2@0+ (1,0) [0|3] "" IHU
 SG_ EscGearShiftInhbReq_UB : 203|1@0+ (1,0) [0|1] "" IHU
 SG_ EscSt_UB : 216|1@0+ (1,0) [0|1] "" ASDM,IHU,ZCUD
 SG_ EscStChks : 215|8@0+ (1.0,0.0) [0.0|255.0] "Unitless" ASDM,IHU,ZCUD
 SG_ EscStCntr : 223|4@0+ (1.0,0.0) [0.0|15.0] "Unitless" ASDM,IHU,ZCUD
 SG_ EscStEscSt : 219|3@0+ (1,0) [0|7] "" ASDM,IHU,ZCUD
 SG_ LimForJerkPosNotExcd_UB : 202|1@0+ (1,0) [0|1] "" IHU
 SG_ LimForJerkPosNotExcdChks : 231|8@0+ (1.0,0.0) [0.0|255.0] "Unitless" IHU
 SG_ LimForJerkPosNotExcdCntr : 239|4@0+ (1.0,0.0) [0.0|15.0] "Unitless" IHU
 SG_ LimForJerkPosNotExcdLimForJerkPosNotExcd : 235|1@0+ (1,0) [0|1] "" IHU
 SG_ PtTq_UB : 234|1@0+ (1,0) [0|1] "" IHU
 SG_ PtTqAtAxleAddReq_UB : 233|1@0+ (1,0) [0|1] "" IHU
 SG_ PtTqAtAxleAddReqChks : 295|8@0+ (1.0,0.0) [0.0|255.0] "Unitless" IHU
 SG_ PtTqAtAxleAddReqCntr : 283|4@0+ (1.0,0.0) [0.0|15.0] "Unitless" IHU
 SG_ PtTqAtAxleAddReqPtTqAtAxleAddFrntReq : 303|10@0+ (1.0,0.0) [0.0|1000.0] "NewtonMeter" IHU
 SG_ PtTqAtAxleAddReqPtTqAtAxleAddReReq : 309|10@0+ (1.0,0.0) [0.0|1000.0] "NewtonMeter" IHU
 SG_ PtTqChks : 247|8@0+ (1.0,0.0) [0.0|255.0] "Unitless" IHU
 SG_ PtTqCntr : 287|4@0+ (1.0,0.0) [0.0|15.0] "Unitless" IHU
 SG_ PtTqHardMax_UB : 232|1@0+ (1,0) [0|1] "" IHU
 SG_ PtTqHardMaxChks : 327|8@0+ (1.0,0.0) [0.0|255.0] "Unitless" IHU
 SG_ PtTqHardMaxCntr : 315|4@0+ (1.0,0.0) [0.0|15.0] "Unitless" IHU
 SG_ PtTqHardMaxGrdtNeg : 335|13@0+ (4.0,0.0) [0.0|32764.0] "Nm/s" IHU
 SG_ PtTqHardMaxGrdtPos : 351|13@0+ (4.0,0.0) [0.0|32764.0] "Nm/s" IHU
 SG_ PtTqHardMaxReq : 367|13@0- (4.0,0.0) [-16384.0|16380.0] "NewtonMeter" IHU
 SG_ PtTqMinReq : 255|13@0- (4.0,0.0) [-16384.0|16380.0] "NewtonMeter" IHU
 SG_ PtTqSetSafe_UB : 201|1@0+ (1,0) [0|1] "" IHU
 SG_ PtTqSetSafeChks : 383|8@0+ (1.0,0.0) [0.0|255.0] "Unitless" IHU
 SG_ PtTqSetSafeCntr : 439|4@0+ (1.0,0.0) [0.0|15.0] "Unitless" IHU
 SG_ PtTqSetSafeGrdtNeg : 391|13@0+ (4.0,0.0) [0.0|32764.0] "Nm/s" IHU
 SG_ PtTqSetSafeGrdtPos : 407|13@0+ (4.0,0.0) [0.0|32764.0] "Nm/s" IHU
 SG_ PtTqSetSafeReq : 423|13@0- (4.0,0.0) [-16384.0|16380.0] "NewtonMeter" IHU
 SG_ PtTqSoftMaxReq : 271|13@0- (4.0,0.0) [-16384.0|16380.0] "NewtonMeter" IHU
 SG_ RoadIncln_UB : 200|1@0+ (1,0) [0|1] "" ASDM,IHU,ZCUD,ZCUP
 SG_ RoadInclnQly : 433|2@0+ (1,0) [0|3] "" ASDM,IHU,ZCUD,ZCUP
 SG_ RoadInclnRoadIncln : 447|16@0- (0.000030518,0.0) [-0.9999833060000001|0.9999833060000001] "rad" ASDM,IHU,ZCUD,ZCUP
 SG_ SpdRotlForWhlsAtAxleFrnt_UB : 435|1@0+ (1,0) [0|1] "" IHU
 SG_ SpdRotlForWhlsAtAxleFrntChks : 463|8@0+ (1.0,0.0) [0.0|255.0] "Unitless" IHU
 SG_ SpdRotlForWhlsAtAxleFrntCntr : 487|4@0+ (1.0,0.0) [0.0|15.0] "Unitless" IHU
 SG_ SpdRotlForWhlsAtAxleFrntSpdRotlForWhlsAtAxleFrnt : 471|15@0+ (0.5,0.0) [0.0|16383.5] "rpm" IHU
 SG_ SpdRotlForWhlsAtAxleRe : 495|15@0+ (0.5,0.0) [0.0|16383.5] "rpm" IHU,ZCUD
 SG_ SpdRotlForWhlsAtAxleRe_UB : 434|1@0+ (1,0) [0|1] "" IHU,ZCUD

BO_ 608 BcmZCUCANFD1Fr07 : 64 BBM
 SG_ AutoShowModBCEna : 7|1@0+ (1,0) [0|1] "" IHU
 SG_ AutoShowModBCEna_UB : 6|1@0+ (1,0) [0|1] "" IHU
 SG_ EpbDrvrDisp : 5|4@0+ (1,0) [0|15] "" IHU
 SG_ EpbDrvrDisp_UB : 1|1@0+ (1,0) [0|1] "" IHU
 SG_ ImobBrkNrSerl_UB : 71|1@0+ (1,0) [0|1] "" IHU
 SG_ ImobBrkNrSerl0 : 23|8@0+ (1.0,0.0) [0.0|255.0] "Unitless" IHU
 SG_ ImobBrkNrSerl1 : 31|8@0+ (1.0,0.0) [0.0|255.0] "Unitless" IHU
 SG_ ImobBrkNrSerl2 : 39|8@0+ (1.0,0.0) [0.0|255.0] "Unitless" IHU
 SG_ ImobBrkNrSerl3 : 47|8@0+ (1.0,0.0) [0.0|255.0] "Unitless" IHU
 SG_ ImobBrkNrSerl4 : 55|8@0+ (1.0,0.0) [0.0|255.0] "Unitless" IHU
 SG_ ImobBrkNrSerl5 : 63|8@0+ (1.0,0.0) [0.0|255.0] "Unitless" IHU
 SG_ WhlRotCntrFrnt : 15|8@0+ (1.0,0.0) [0.0|255.0] "Unitless" IHU
 SG_ WhlRotCntrFrnt_UB : 0|1@0+ (1,0) [0|1] "" IHU

BO_ 997 BcmZCUCANFD1Fr08 : 64 BBM
 SG_ BkpOfDstTrvldFromBrk : 7|21@0+ (1.0,0.0) [0.0|2000000.0] "km" IHU
 SG_ BkpOfDstTrvldFromBrk_UB : 18|1@0+ (1,0) [0|1] "" IHU
 SG_ DstTrvldVldFromBrkBkp : 35|1@0+ (1,0) [0|1] "" IHU
 SG_ DstTrvldVldFromBrkBkp_UB : 34|1@0+ (1,0) [0|1] "" IHU
 SG_ EmgyBrkLiReq_UB : 33|1@0+ (1,0) [0|1] "" IHU,ZCUD
 SG_ EmgyBrkLiReqChks : 47|8@0+ (1.0,0.0) [0.0|255.0] "Unitless" IHU,ZCUD
 SG_ EmgyBrkLiReqCntr : 55|4@0+ (1.0,0.0) [0.0|15.0] "Unitless" IHU,ZCUD
 SG_ EmgyBrkLiReqEmgyBrk : 51|2@0+ (1,0) [0|3] "" IHU,ZCUD
 SG_ EPBLockChk_UB : 32|1@0+ (1,0) [0|1] "" ZCUD
 SG_ EPBLockChkChk : 56|1@0+ (1,0) [0|1] "" ZCUD
 SG_ EPBLockChkData0 : 71|8@0+ (1.0,0.0) [0.0|255.0] "Unitless" ZCUD
 SG_ EPBLockChkData1 : 79|8@0+ (1.0,0.0) [0.0|255.0] "Unitless" ZCUD
 SG_ EPBLockChkData2 : 87|8@0+ (1.0,0.0) [0.0|255.0] "Unitless" ZCUD
 SG_ EPBLockChkData3 : 95|8@0+ (1.0,0.0) [0.0|255.0] "Unitless" ZCUD
 SG_ EPBLockChkData4 : 103|8@0+ (1.0,0.0) [0.0|255.0] "Unitless" ZCUD
 SG_ EPBLockChkData5 : 111|8@0+ (1.0,0.0) [0.0|255.0] "Unitless" ZCUD
 SG_ EPBLockChkData6 : 119|8@0+ (1.0,0.0) [0.0|255.0] "Unitless" ZCUD
 SG_ EPBLockSts : 39|2@0+ (1,0) [0|3] "" ZCUD
 SG_ EPBLockSts_UB : 37|1@0+ (1,0) [0|1] "" ZCUD
 SG_ IndcnToDrvrPostImpctCtrl : 49|1@0+ (1,0) [0|1] "" IHU,ZCUD
 SG_ IndcnToDrvrPostImpctCtrl_UB : 48|1@0+ (1,0) [0|1] "" IHU,ZCUD
 SG_ SteerAssiAvlSts : 63|2@0+ (1,0) [0|3] "" IHU
 SG_ SteerAssiAvlSts_UB : 61|1@0+ (1,0) [0|1] "" IHU
 SG_ SteerAssiWarnMsg : 60|3@0+ (1,0) [0|7] "" IHU
 SG_ SteerAssiWarnMsg_UB : 57|1@0+ (1,0) [0|1] "" IHU
 SG_ VBFAvlSts : 127|1@0+ (1,0) [0|1] "" IHU
 SG_ VBFAvlSts_UB : 36|1@0+ (1,0) [0|1] "" IHU
 SG_ VehSpdLgtTar : 16|9@0+ (1.0,0.0) [0.0|450.0] "Km/h" IHU
 SG_ VehSpdLgtTar_UB : 17|1@0+ (1,0) [0|1] "" IHU

BO_ 1040 BcmZCUCANFD1Fr09 : 64 BBM
 SG_ BrkBoostClrRdyReq : 8|1@0+ (1,0) [0|1] "" IHU
 SG_ BrkBoostClrRdyReq_UB : 23|1@0+ (1,0) [0|1] "" IHU

BO_ 576 BcmZCUCANFD1Fr11 : 64 BBM
 SG_ BrkSysSts_UB : 16|1@0+ (1,0) [0|1] "" IHU
 SG_ BrkSysStsADL3BrkFallBck : 23|1@0+ (1,0) [0|1] "" IHU
 SG_ BrkSysStsBrkDegradation : 7|4@0+ (1,0) [0|15] "" IHU
 SG_ BrkSysStsBrkSysCapability : 22|2@0+ (1,0) [0|3] "" IHU
 SG_ BrkSysStsBrkSysModCfmd : 3|4@0+ (1,0) [0|15] "" IHU
 SG_ BrkSysStsChks : 15|8@0+ (1.0,0.0) [0.0|255.0] "Unitless" IHU
 SG_ BrkSysStsCntr : 20|4@0+ (1.0,0.0) [0.0|15.0] "Unitless" IHU
 SG_ EscWarnIndcnReq_UB : 41|1@0+ (1,0) [0|1] "" ASDM,IHU
 SG_ EscWarnIndcnReqChks : 55|8@0+ (1.0,0.0) [0.0|255.0] "Unitless" ASDM,IHU
 SG_ EscWarnIndcnReqCntr : 63|4@0+ (1.0,0.0) [0.0|15.0] "Unitless" ASDM,IHU
 SG_ EscWarnIndcnReqEscWarnIndcnReq : 59|2@0+ (1,0) [0|3] "" ASDM,IHU
 SG_ LampReqByVehHld : 57|2@0+ (1,0) [0|3] "" ASDM,IHU
 SG_ LampReqByVehHld_UB : 40|1@0+ (1,0) [0|1] "" ASDM,IHU

BO_ 949 BcmZCUCANFD1Fr12 : 64 BBM
 SG_ AutHldSoftSwtEnaSts : 1|1@0+ (1,0) [0|1] "" IHU
 SG_ AutHldSoftSwtEnaSts_UB : 0|1@0+ (1,0) [0|1] "" IHU
 SG_ BrkAndAbsWarnIndcnReq_UB : 15|1@0+ (1,0) [0|1] "" IHU,ZCUD
 SG_ BrkAndAbsWarnIndcnReqAbsWarnIndcnReq : 13|2@0+ (1,0) [0|3] "" IHU,ZCUD
 SG_ BrkAndAbsWarnIndcnReqBrkWarnIndcnReq : 14|1@0+ (1,0) [0|1] "" IHU,ZCUD
 SG_ BrkAndAbsWarnIndcnReqChks : 23|8@0+ (1.0,0.0) [0.0|255.0] "Unitless" IHU,ZCUD
 SG_ BrkAndAbsWarnIndcnReqCntr : 11|4@0+ (1.0,0.0) [0.0|15.0] "Unitless" IHU,ZCUD
 SG_ BrkBoostErrIndcnReq : 31|1@0+ (1,0) [0|1] "" IHU
 SG_ BrkBoostErrIndcnReq_UB : 30|1@0+ (1,0) [0|1] "" IHU
 SG_ BrkByWireWarnIndcn : 29|1@0+ (1,0) [0|1] "" IHU
 SG_ BrkByWireWarnIndcn_UB : 28|1@0+ (1,0) [0|1] "" IHU
 SG_ BrkFldLvl : 39|1@0+ (1,0) [0|1] "" IHU
 SG_ BrkFldLvl_UB : 38|1@0+ (1,0) [0|1] "" IHU
 SG_ BrkMsgForHybWarnReq : 27|3@0+ (1,0) [0|7] "" IHU
 SG_ BrkMsgForHybWarnReq_UB : 24|1@0+ (1,0) [0|1] "" IHU
 SG_ BrkMsgForLoVacReqd : 37|1@0+ (1,0) [0|1] "" IHU
 SG_ BrkMsgForLoVacReqd_UB : 36|1@0+ (1,0) [0|1] "" IHU
 SG_ BrkMsgWarnReq : 35|3@0+ (1,0) [0|7] "" IHU
 SG_ BrkMsgWarnReq_UB : 32|1@0+ (1,0) [0|1] "" IHU
 SG_ BrkMsgWarnReqForHmi : 47|4@0+ (1,0) [0|15] "" IHU
 SG_ BrkMsgWarnReqForHmi_UB : 43|1@0+ (1,0) [0|1] "" IHU
 SG_ BrkRelsWarnReq : 55|1@0+ (1,0) [0|1] "" IHU
 SG_ BrkRelsWarnReq_UB : 54|1@0+ (1,0) [0|1] "" IHU
 SG_ BrkSysWarnIndcnReq : 7|1@0+ (1,0) [0|1] "" IHU
 SG_ BrkSysWarnIndcnReq_UB : 6|1@0+ (1,0) [0|1] "" IHU
 SG_ CstCtrlActv_UB : 40|1@0+ (1,0) [0|1] "" IHU
 SG_ CstCtrlActvCstCtrlEab : 42|1@0+ (1,0) [0|1] "" IHU
 SG_ CstCtrlActvCtrlSts1 : 41|1@0+ (1,0) [0|1] "" IHU
 SG_ DispMsgByVehHld : 5|3@0+ (1,0) [0|7] "" IHU
 SG_ DispMsgByVehHld_UB : 2|1@0+ (1,0) [0|1] "" IHU
 SG_ DrvModEscOff_UB : 53|1@0+ (1,0) [0|1] "" IHU
 SG_ DrvModEscOffChks : 63|8@0+ (1.0,0.0) [0.0|255.0] "Unitless" IHU
 SG_ DrvModEscOffCntr : 51|4@0+ (1.0,0.0) [0.0|15.0] "Unitless" IHU
 SG_ DrvModEscOffDrvModEscOff : 52|1@0+ (1,0) [0|1] "" IHU
 SG_ EpbApplyEna : 71|1@0+ (1,0) [0|1] "" IHU
 SG_ EpbApplyEna_UB : 70|1@0+ (1,0) [0|1] "" IHU
 SG_ EpbRelsEna : 69|1@0+ (1,0) [0|1] "" IHU
 SG_ EpbRelsEna_UB : 68|1@0+ (1,0) [0|1] "" IHU

BO_ 805 BcmZCUCANFD1Fr13 : 64 BBM
 SG_ SwtStsforHillDwnCtrl : 7|1@0+ (1,0) [0|1] "" IHU
 SG_ SwtStsforHillDwnCtrl_UB : 6|1@0+ (1,0) [0|1] "" IHU

BO_ 704 BcmZCUCANFD1Fr14 : 64 BBM
 SG_ TireRdEstimd : 7|10@0+ (0.00048828,0.25) [0.25|0.50048764] "m" IHU
 SG_ TireRdEstimd_UB : 13|1@0+ (1,0) [0|1] "" IHU

BO_ 402 BcmZCUCANFD1Fr15 : 64 BBM
 SG_ AsyLatCtrlModReqGroupCfmd_UB : 312|1@0+ (1,0) [0|1] "" IHU
 SG_ AsyLatCtrlModReqGroupCfmdChks : 343|8@0+ (1.0,0.0) [0.0|255.0] "Unitless" IHU
 SG_ AsyLatCtrlModReqGroupCfmdCntr : 351|4@0+ (1.0,0.0) [0.0|15.0] "Unitless" IHU
 SG_ AsyLatCtrlModReqGroupCfmdLatCtrlMod : 347|4@0+ (1,0) [0|15] "" IHU
 SG_ BrkLiOnReq_UB : 330|1@0+ (1,0) [0|1] "" IHU,ZCUD
 SG_ BrkLiOnReqChks : 327|8@0+ (1.0,0.0) [0.0|255.0] "Unitless" IHU,ZCUD
 SG_ BrkLiOnReqCntr : 335|4@0+ (1.0,0.0) [0.0|15.0] "Unitless" IHU,ZCUD
 SG_ BrkLiOnReqSts : 331|1@0+ (1,0) [0|1] "" IHU,ZCUD
 SG_ PrkLatLgtFailr_UB : 36|1@0+ (1,0) [0|1] "" IHU
 SG_ PrkLatLgtFailrChks : 47|8@0+ (1.0,0.0) [0.0|255.0] "Unitless" IHU
 SG_ PrkLatLgtFailrCntr : 55|4@0+ (1.0,0.0) [0.0|15.0] "Unitless" IHU
 SG_ PrkLatLgtFailrPrkLatLgtFailr : 51|3@0+ (1,0) [0|7] "" IHU
 SG_ StandStillMgrStsForHld_UB : 8|1@0+ (1,0) [0|1] "" ASDM,IHU,ZCUD
 SG_ StandStillMgrStsForHld1 : 15|3@0+ (1,0) [0|7] "" ASDM,IHU,ZCUD
 SG_ StandStillMgrStsForHldChks : 7|8@0+ (1.0,0.0) [0.0|255.0] "Unitless" ASDM,IHU,ZCUD
 SG_ StandStillMgrStsForHldCntr : 12|4@0+ (1.0,0.0) [0.0|15.0] "Unitless" ASDM,IHU,ZCUD
 SG_ VehMNom_UB : 37|1@0+ (1,0) [0|1] "" ASDM,IHU
 SG_ VehMNomTrlrM : 25|2@0+ (1,0) [0|3] "" ASDM,IHU
 SG_ VehMNomVehM : 23|14@0+ (1.0,0.0) [0.0|10000.0] "kg" ASDM,IHU
 SG_ VehMNomVehMQly : 39|2@0+ (1,0) [0|3] "" ASDM,IHU
 SG_ VehV_UB : 35|1@0+ (1,0) [0|1] "" ASDM,IHU
 SG_ VehVLat : 79|14@0- (0.003906369,0.0) [-29.997007551|30.00091392] "m/s" ASDM,IHU
 SG_ VehVLatQf : 81|2@0+ (1,0) [0|3] "" ASDM,IHU
 SG_ VehVLgt : 95|16@0- (0.00391,0.0) [-127.99776000000001|128.00167000000002] "m/s" ASDM,IHU
 SG_ VehVLgtQf : 111|2@0+ (1,0) [0|3] "" ASDM,IHU
 SG_ WhlDirRotlFrnt_UB : 34|1@0+ (1,0) [0|1] "" IHU
 SG_ WhlDirRotlFrntChks : 119|8@0+ (1.0,0.0) [0.0|255.0] "Unitless" IHU
 SG_ WhlDirRotlFrntCntr : 127|4@0+ (1.0,0.0) [0.0|15.0] "Unitless" IHU
 SG_ WhlDirRotlFrntLe : 123|2@0+ (1,0) [0|3] "" IHU
 SG_ WhlDirRotlFrntRi : 121|2@0+ (1,0) [0|3] "" IHU
 SG_ WhlDirRotlRe_UB : 33|1@0+ (1,0) [0|1] "" IHU
 SG_ WhlDirRotlReChks : 135|8@0+ (1.0,0.0) [0.0|255.0] "Unitless" IHU
 SG_ WhlDirRotlReCntr : 143|4@0+ (1.0,0.0) [0.0|15.0] "Unitless" IHU
 SG_ WhlDirRotlReLe : 139|2@0+ (1,0) [0|3] "" IHU
 SG_ WhlDirRotlReRi : 137|2@0+ (1,0) [0|3] "" IHU
 SG_ WhlFastSpdSafe_UB : 32|1@0+ (1,0) [0|1] "" IHU
 SG_ WhlFastSpdSafeA : 151|15@0+ (0.00391,0.0) [0.0|125.0027] "m/s" IHU
 SG_ WhlFastSpdSafeChks : 167|8@0+ (1.0,0.0) [0.0|255.0] "Unitless" IHU
 SG_ WhlFastSpdSafeCntr : 175|4@0+ (1.0,0.0) [0.0|15.0] "Unitless" IHU
 SG_ WhlFastSpdSafeQF : 171|2@0+ (1,0) [0|3] "" IHU
 SG_ WhlRotToothCntr_UB : 109|1@0+ (1,0) [0|1] "" IHU,ZCUD
 SG_ WhlRotToothCntrChks : 183|8@0+ (1.0,0.0) [0.0|255.0] "Unitless" IHU,ZCUD
 SG_ WhlRotToothCntrCntr : 223|4@0+ (1.0,0.0) [0.0|15.0] "Unitless" IHU,ZCUD
 SG_ WhlRotToothCntrFrntLe : 191|8@0+ (1.0,0.0) [0.0|255.0] "Unitless" IHU,ZCUD
 SG_ WhlRotToothCntrFrntRi : 199|8@0+ (1.0,0.0) [0.0|255.0] "Unitless" IHU,ZCUD
 SG_ WhlRotToothCntrReLe : 207|8@0+ (1.0,0.0) [0.0|255.0] "Unitless" IHU,ZCUD
 SG_ WhlRotToothCntrReRi : 215|8@0+ (1.0,0.0) [0.0|255.0] "Unitless" IHU,ZCUD
 SG_ WhlSpdCircumlFrnt_UB : 108|1@0+ (1,0) [0|1] "" IHU
 SG_ WhlSpdCircumlFrntChks : 231|8@0+ (1.0,0.0) [0.0|255.0] "Unitless" IHU
 SG_ WhlSpdCircumlFrntCntr : 239|4@0+ (1.0,0.0) [0.0|15.0] "Unitless" IHU
 SG_ WhlSpdCircumlFrntLe : 247|15@0+ (0.00391,0.0) [0.0|125.0027] "m/s" IHU
 SG_ WhlSpdCircumlFrntLeQf : 235|2@0+ (1,0) [0|3] "" IHU
 SG_ WhlSpdCircumlFrntRiQf : 233|2@0+ (1,0) [0|3] "" IHU
 SG_ WhlSpdCircumlFrntWhlSpdCircumlFrntRi : 263|15@0+ (0.00391,0.0) [0.0|125.0027] "m/s" IHU
 SG_ WhlSpdCircumlRe_UB : 107|1@0+ (1,0) [0|1] "" IHU
 SG_ WhlSpdCircumlReChks : 279|8@0+ (1.0,0.0) [0.0|255.0] "Unitless" IHU
 SG_ WhlSpdCircumlReCntr : 287|4@0+ (1.0,0.0) [0.0|15.0] "Unitless" IHU
 SG_ WhlSpdCircumlReLe : 295|15@0+ (0.00391,0.0) [0.0|125.0027] "m/s" IHU
 SG_ WhlSpdCircumlReLeQf : 283|2@0+ (1,0) [0|3] "" IHU
 SG_ WhlSpdCircumlReRi : 311|15@0+ (0.00391,0.0) [0.0|125.0027] "m/s" IHU
 SG_ WhlSpdCircumlReRiQf : 281|2@0+ (1,0) [0|3] "" IHU
 SG_ YawRateReqdByDrvr : 63|16@0- (0.000244140625,0.0) [-5.0|5.0] "rad/s" IHU,ZCUD
 SG_ YawRateReqdByDrvr_UB : 48|1@0+ (1,0) [0|1] "" IHU,ZCUD

BO_ 98 BcmZCUCANFD1Fr16 : 64 BBM
 SG_ VehDynCtrlStsForALgtCmft_UB : 19|1@0+ (1,0) [0|1] "" ASDM,IHU
 SG_ VehDynCtrlStsForALgtCmftVehDynCtrlStsChks : 7|8@0+ (1.0,0.0) [0.0|255.0] "Unitless" ASDM,IHU
 SG_ VehDynCtrlStsForALgtCmftVehDynCtrlStsCntr : 15|4@0+ (1.0,0.0) [0.0|15.0] "Unitless" ASDM,IHU
 SG_ VehDynCtrlStsForALgtCmftVehDynCtrlStsDend : 11|1@0+ (1,0) [0|1] "" ASDM,IHU
 SG_ VehDynCtrlStsForALgtCmftVehDynCtrlStsForBrkActv : 10|1@0+ (1,0) [0|1] "" ASDM,IHU
 SG_ VehDynCtrlStsForALgtCmftVehDynCtrlStsForBrkPrecActv : 9|1@0+ (1,0) [0|1] "" ASDM,IHU
 SG_ VehDynCtrlStsForALgtCmftVehDynCtrlStsForStandStillMgrForPark : 23|3@0+ (1,0) [0|7] "" ASDM,IHU
 SG_ VehDynCtrlStsForALgtCmftVehDynCtrlStsForWhlBrkWrm : 8|1@0+ (1,0) [0|1] "" ASDM,IHU
 SG_ VehDynCtrlStsForALgtCmftVehDynCtrlStsNotEna : 20|1@0+ (1,0) [0|1] "" ASDM,IHU
 SG_ VehMtnSt_UB : 72|1@0+ (1,0) [0|1] "" ASDM,IHU,ZCUD,ZCUP
 SG_ VehMtnStChks : 71|8@0+ (1.0,0.0) [0.0|255.0] "Unitless" ASDM,IHU,ZCUD,ZCUP
 SG_ VehMtnStCntr : 79|4@0+ (1.0,0.0) [0.0|15.0] "Unitless" ASDM,IHU,ZCUD,ZCUP
 SG_ VehMtnStVehMtnSt : 75|3@0+ (1,0) [0|7] "" ASDM,IHU,ZCUD,ZCUP
 SG_ VehSpdLgt_UB : 18|1@0+ (1,0) [0|1] "" ASDM,IHU,ZCUD,ZCUP
 SG_ VehSpdLgtA : 31|15@0+ (0.00391,0.0) [0.0|125.0027] "m/s" ASDM,IHU,ZCUD,ZCUP
 SG_ VehSpdLgtChks : 47|8@0+ (1.0,0.0) [0.0|255.0] "Unitless" ASDM,IHU,ZCUD,ZCUP
 SG_ VehSpdLgtCntr : 55|4@0+ (1.0,0.0) [0.0|15.0] "Unitless" ASDM,IHU,ZCUD,ZCUP
 SG_ VehSpdLgtQf : 51|2@0+ (1,0) [0|3] "" ASDM,IHU,ZCUD,ZCUP
 SG_ WhlAFrntMax : 63|8@0+ (2.48,0.0) [0.0|632.4] "rad/s^2" IHU
 SG_ WhlAFrntMax_UB : 49|1@0+ (1,0) [0|1] "" IHU
 SG_ WhlVAgrFrnt_UB : 17|1@0+ (1,0) [0|1] "" Vector__XXX
 SG_ WhlVAgrFrntLe : 87|16@0- (0.0078125,0.0) [-255.0|255.0] "rad/s" Vector__XXX
 SG_ WhlVAgrFrntLeQf : 119|2@0+ (1,0) [0|3] "" Vector__XXX
 SG_ WhlVAgrFrntRi : 103|16@0- (0.0078125,0.0) [-255.0|255.0] "rad/s" Vector__XXX
 SG_ WhlVAgrFrntRiQf : 117|2@0+ (1,0) [0|3] "" Vector__XXX
 SG_ WhlVAgrRe_UB : 16|1@0+ (1,0) [0|1] "" Vector__XXX
 SG_ WhlVAgrReLe : 127|16@0- (0.0078125,0.0) [-255.0|255.0] "rad/s" Vector__XXX
 SG_ WhlVAgrReLeQf : 115|2@0+ (1,0) [0|3] "" Vector__XXX
 SG_ WhlVAgrReRi : 143|16@0- (0.0078125,0.0) [-255.0|255.0] "rad/s" Vector__XXX
 SG_ WhlVAgrReRiQf : 113|2@0+ (1,0) [0|3] "" Vector__XXX

CM_ SG_ 544 VehObjforADB1AdbAbsDist "Absolute distance between ego vehicle/camera and object";
CM_ SG_ 544 VehObjforADB1AdbClassn "Object Type";
CM_ SG_ 544 VehObjforADB1AdbHozlAgLe "horizontal angle between left of object front or tail lamp and the ego vehicle camera";
CM_ SG_ 544 VehObjforADB1AdbHozlAgRi "horizontal angle between right of object front or tail lamp and the ego vehicle camera";
CM_ SG_ 544 VehObjforADB1AdbObjDir "Object moving direction";
CM_ SG_ 544 VehObjforADB1AdbObjHozlAgSpdLe "Object left angle moving speed";
CM_ SG_ 544 VehObjforADB1AdbObjHozlAgSpdRi "Object right angle moving speed";
CM_ SG_ 544 VehObjforADB1AdbTrkInfo "Is the object a tracked one or a spontaneously occuring one";
CM_ SG_ 544 VehObjforADB1AdbVertAg "angle between ego vehicle camera and the bottom of object ";
CM_ SG_ 544 VehObjforADB2AdbAbsDist "Absolute distance between ego vehicle/camera and object";
CM_ SG_ 544 VehObjforADB2AdbClassn "Object Type";
CM_ SG_ 544 VehObjforADB2AdbHozlAgLe "horizontal angle between left of object front or tail lamp and the ego vehicle camera";
CM_ SG_ 544 VehObjforADB2AdbHozlAgRi "horizontal angle between right of object front or tail lamp and the ego vehicle camera";
CM_ SG_ 544 VehObjforADB2AdbObjDir "Object moving direction";
CM_ SG_ 544 VehObjforADB2AdbObjHozlAgSpdLe "Object left angle moving speed";
CM_ SG_ 544 VehObjforADB2AdbObjHozlAgSpdRi "Object right angle moving speed";
CM_ SG_ 544 VehObjforADB2AdbTrkInfo "Is the object a tracked one or a spontaneously occuring one";
CM_ SG_ 544 VehObjforADB2AdbVertAg "angle between ego vehicle camera and the bottom of object ";
CM_ SG_ 544 VehObjforADB3AdbAbsDist "Absolute distance between ego vehicle/camera and object";
CM_ SG_ 544 VehObjforADB3AdbClassn "Object Type";
CM_ SG_ 544 VehObjforADB3AdbHozlAgLe "horizontal angle between left of object front or tail lamp and the ego vehicle camera";
CM_ SG_ 544 VehObjforADB3AdbHozlAgRi "horizontal angle between right of object front or tail lamp and the ego vehicle camera";
CM_ SG_ 544 VehObjforADB3AdbObjDir "Object moving direction";
CM_ SG_ 544 VehObjforADB3AdbObjHozlAgSpdLe "Object left angle moving speed";
CM_ SG_ 544 VehObjforADB3AdbObjHozlAgSpdRi "Object right angle moving speed";
CM_ SG_ 544 VehObjforADB3AdbTrkInfo "Is the object a tracked one or a spontaneously occuring one";
CM_ SG_ 544 VehObjforADB3AdbVertAg "angle between ego vehicle camera and the bottom of object ";
CM_ SG_ 544 VehObjforADB4AdbAbsDist "Absolute distance between ego vehicle/camera and object";
CM_ SG_ 544 VehObjforADB4AdbClassn "Object Type";
CM_ SG_ 544 VehObjforADB4AdbHozlAgLe "horizontal angle between left of object front or tail lamp and the ego vehicle camera";
CM_ SG_ 544 VehObjforADB4AdbHozlAgRi "horizontal angle between right of object front or tail lamp and the ego vehicle camera";
CM_ SG_ 544 VehObjforADB4AdbObjDir "Object moving direction";
CM_ SG_ 544 VehObjforADB4AdbObjHozlAgSpdLe "Object left angle moving speed";
CM_ SG_ 544 VehObjforADB4AdbObjHozlAgSpdRi "Object right angle moving speed";
CM_ SG_ 544 VehObjforADB4AdbTrkInfo "Is the object a tracked one or a spontaneously occuring one";
CM_ SG_ 544 VehObjforADB4AdbVertAg "angle between ego vehicle camera and the bottom of object ";
CM_ SG_ 544 VehObjforADB5AdbAbsDist "Absolute distance between ego vehicle/camera and object";
CM_ SG_ 544 VehObjforADB5AdbClassn "Object Type";
CM_ SG_ 544 VehObjforADB5AdbHozlAgLe "horizontal angle between left of object front or tail lamp and the ego vehicle camera";
CM_ SG_ 544 VehObjforADB5AdbHozlAgRi "horizontal angle between right of object front or tail lamp and the ego vehicle camera";
CM_ SG_ 544 VehObjforADB5AdbObjDir "Object moving direction";
CM_ SG_ 544 VehObjforADB5AdbObjHozlAgSpdLe "Object left angle moving speed";
CM_ SG_ 544 VehObjforADB5AdbObjHozlAgSpdRi "Object right angle moving speed";
CM_ SG_ 544 VehObjforADB5AdbTrkInfo "Is the object a tracked one or a spontaneously occuring one";
CM_ SG_ 544 VehObjforADB5AdbVertAg "angle between ego vehicle camera and the bottom of object ";
CM_ SG_ 544 VehObjforADB6AdbAbsDist "Absolute distance between ego vehicle/camera and object";
CM_ SG_ 544 VehObjforADB6AdbClassn "Object Type";
CM_ SG_ 544 VehObjforADB6AdbHozlAgLe "horizontal angle between left of object front or tail lamp and the ego vehicle camera";
CM_ SG_ 544 VehObjforADB6AdbHozlAgRi "horizontal angle between right of object front or tail lamp and the ego vehicle camera";
CM_ SG_ 544 VehObjforADB6AdbObjDir "Object moving direction";
CM_ SG_ 544 VehObjforADB6AdbObjHozlAgSpdLe "Object left angle moving speed";
CM_ SG_ 544 VehObjforADB6AdbObjHozlAgSpdRi "Object right angle moving speed";
CM_ SG_ 544 VehObjforADB6AdbTrkInfo "Is the object a tracked one or a spontaneously occuring one";
CM_ SG_ 544 VehObjforADB6AdbVertAg "angle between ego vehicle camera and the bottom of object ";
CM_ SG_ 544 VehObjforADB7AdbAbsDist "Absolute distance between ego vehicle/camera and object";
CM_ SG_ 544 VehObjforADB7AdbClassn "Object Type";
CM_ SG_ 544 VehObjforADB7AdbHozlAgLe "horizontal angle between left of object front or tail lamp and the ego vehicle camera";
CM_ SG_ 544 VehObjforADB7AdbHozlAgRi "horizontal angle between right of object front or tail lamp and the ego vehicle camera";
CM_ SG_ 544 VehObjforADB7AdbObjDir "Object moving direction";
CM_ SG_ 544 VehObjforADB7AdbObjHozlAgSpdLe "Object left angle moving speed";
CM_ SG_ 544 VehObjforADB7AdbObjHozlAgSpdRi "Object right angle moving speed";
CM_ SG_ 544 VehObjforADB7AdbTrkInfo "Is the object a tracked one or a spontaneously occuring one";
CM_ SG_ 544 VehObjforADB7AdbVertAg "angle between ego vehicle camera and the bottom of object ";
CM_ SG_ 544 VehObjforADB8AdbAbsDist "Absolute distance between ego vehicle/camera and object";
CM_ SG_ 544 VehObjforADB8AdbClassn "Object Type";
CM_ SG_ 544 VehObjforADB8AdbHozlAgLe "horizontal angle between left of object front or tail lamp and the ego vehicle camera";
CM_ SG_ 544 VehObjforADB8AdbHozlAgRi "horizontal angle between right of object front or tail lamp and the ego vehicle camera";
CM_ SG_ 544 VehObjforADB8AdbObjDir "Object moving direction";
CM_ SG_ 544 VehObjforADB8AdbObjHozlAgSpdLe "Object left angle moving speed";
CM_ SG_ 544 VehObjforADB8AdbObjHozlAgSpdRi "Object right angle moving speed";
CM_ SG_ 544 VehObjforADB8AdbTrkInfo "Is the object a tracked one or a spontaneously occuring one";
CM_ SG_ 544 VehObjforADB8AdbVertAg "angle between ego vehicle camera and the bottom of object ";
CM_ SG_ 1129 FrntRdrStsRdrNrDetn "Number of detections";
CM_ SG_ 1129 FrntRdrStsRdrNrObj "Number of objects";
CM_ SG_ 1129 FrntRdrStsRdrStsBlkd0bin "Blockage flag for 0bin";
CM_ SG_ 1129 FrntRdrStsRdrStsBlkdConf "Confidence of radar blockage";
CM_ SG_ 1129 FrntRdrStsRdrStsChks "Checksum";
CM_ SG_ 1129 FrntRdrStsRdrStsCntr "Counter";
CM_ SG_ 1129 FrntRdrStsRdrStsDstbc "Indication of radar interference, 0 means no interference, 100 means the radar fully saturated from interference";
CM_ SG_ 1129 FrntRdrStsRdrStsEna "Indication whether radar functionality is enabled";
CM_ SG_ 1129 FrntRdrStsRdrStsFaulty "Indication whether radar is faulty";
CM_ SG_ 1129 FrntRdrStsRdrStsIfVersMajor "Reserve";
CM_ SG_ 1129 FrntRdrStsRdrStsIfVersMinor "Reserve";
CM_ SG_ 1129 FrntRdrStsRdrStsLatency "The time instance starting from the end of the last measurement acquisition per cycle to the CAN-FD frames being outputted on the CAN-FD bus";
CM_ SG_ 1129 FrntRdrStsRdrStsMisAlign "Indication whether 0, calibration not start. 1, successfully calibrated in factory or after-sales. 2, successfully auto-calibrated. 3, misalignment degree is larger than threshold, static calibration fail. 4, can not be calibrated statically cause other reason. 5, auto-calibrate fail (cause misalignment degree is larger than threshold or other reason). 6, misalignment degree is larger than threshold, dynamic calibration fail in factory or after-sales. 7, can not be calibrated dynamically cause other reason.";
CM_ SG_ 1129 FrntRdrStsRdrStsMissCom "Signal used to detect missing communication from radar";
CM_ SG_ 1129 FrntRdrStsRdrStsSftyFlt "Safety faulty status";
CM_ SG_ 1129 FrntRdrStsRdrStsTiStamp "Timestamp";
CM_ SG_ 1129 FrntRdrStsRdrStsTiStampStsGlbTiBas "Timestamp";
CM_ SG_ 1129 FrntRdrStsRdrStsTiStampStsSyncToGatewy "Time synchronization status - synchronized to gateway";
CM_ SG_ 1129 FrntRdrStsRdrStsTiStampStsTiLeap "Time synchronization status - time leap";
CM_ SG_ 1129 FrntRdrStsRdrStsTiStampStsTiOut "Time synchronization status - time out";
CM_ SG_ 1129 FrntRdrStsRdrStsWhlSpdCmpFac "Estimated compensation factor for host speed.";
CM_ SG_ 1129 ReSideRdrLeStsRdrNrDetn "Number of detections";
CM_ SG_ 1129 ReSideRdrLeStsRdrNrObj "Number of objects";
CM_ SG_ 1129 ReSideRdrLeStsRdrStsBlkd0bin "Blockage flag for 0bin";
CM_ SG_ 1129 ReSideRdrLeStsRdrStsBlkdConf "Confidence of radar blockage";
CM_ SG_ 1129 ReSideRdrLeStsRdrStsChks "Checksum";
CM_ SG_ 1129 ReSideRdrLeStsRdrStsCntr "Counter";
CM_ SG_ 1129 ReSideRdrLeStsRdrStsDstbc "Indication of radar interference, 0 means no interference, 100 means the radar fully saturated from interference";
CM_ SG_ 1129 ReSideRdrLeStsRdrStsEna "Indication whether radar functionality is enabled";
CM_ SG_ 1129 ReSideRdrLeStsRdrStsFaulty "Indication whether radar is faulty";
CM_ SG_ 1129 ReSideRdrLeStsRdrStsIfVersMajor "Interface version major";
CM_ SG_ 1129 ReSideRdrLeStsRdrStsIfVersMinor "Interface version major";
CM_ SG_ 1129 ReSideRdrLeStsRdrStsLatency "The latency definition is the time instance starting from the end of the last measurement acquisition per cycle to the CAN-FD frames being outputted on the CAN-FD bus. The unit of latency is ms.";
CM_ SG_ 1129 ReSideRdrLeStsRdrStsMisAlign "0, calibration not start. 1, successfully calibrated in factory or after-sales. 2, successfully auto-calibrated. 3, misalignment degree is larger than threshold, static calibration fail. 4, can not be calibrated statically cause other reason. 5, auto-calibrate fail (cause the misalignment degree is larger than threshold or other reason). 6, misalignment degree is larger than threshold, dynamic calibration fail in factory or after-sales. 7, can not be calibrated dynamically cause other reason.";
CM_ SG_ 1129 ReSideRdrLeStsRdrStsMissCom "Signal used to detect missing communication from radar. Reserved/";
CM_ SG_ 1129 ReSideRdrLeStsRdrStsSftyFlt "Safety faulty status";
CM_ SG_ 1129 ReSideRdrLeStsRdrStsTiStamp "Timestamp";
CM_ SG_ 1129 ReSideRdrLeStsRdrStsTiStampStsGlbTiBas "Time synchronization status - synchronized to global time base";
CM_ SG_ 1129 ReSideRdrLeStsRdrStsTiStampStsSyncToGatewy "Time synchronization status - synchronized to gateway";
CM_ SG_ 1129 ReSideRdrLeStsRdrStsTiStampStsTiLeap "Time synchronization status - time leap";
CM_ SG_ 1129 ReSideRdrLeStsRdrStsTiStampStsTiOut "Time synchronization status - time out";
CM_ SG_ 1129 ReSideRdrLeStsRdrStsWhlSpdCmpFac "reserved, not use.";
CM_ SG_ 1129 ReSideRdrRiStsRdrNrDetn "Number of detections";
CM_ SG_ 1129 ReSideRdrRiStsRdrNrObj "Number of objects";
CM_ SG_ 1129 ReSideRdrRiStsRdrStsBlkd0bin "Blockage flag for 0bin";
CM_ SG_ 1129 ReSideRdrRiStsRdrStsBlkdConf "Confidence of radar blockage";
CM_ SG_ 1129 ReSideRdrRiStsRdrStsChks "Checksum";
CM_ SG_ 1129 ReSideRdrRiStsRdrStsCntr "Counter";
CM_ SG_ 1129 ReSideRdrRiStsRdrStsDstbc "Indication of radar interference, 0 means no interference, 100 means the radar fully saturated from interference";
CM_ SG_ 1129 ReSideRdrRiStsRdrStsEna "Indication whether radar functionality is enabled";
CM_ SG_ 1129 ReSideRdrRiStsRdrStsFaulty "Indication whether radar is faulty";
CM_ SG_ 1129 ReSideRdrRiStsRdrStsIfVersMajor "Interface version major";
CM_ SG_ 1129 ReSideRdrRiStsRdrStsIfVersMinor "Interface version major";
CM_ SG_ 1129 ReSideRdrRiStsRdrStsLatency "The latency definition is the time instance starting from the end of the last measurement acquisition per cycle to the CAN-FD frames being outputted on the CAN-FD bus. The unit of latency is ms.";
CM_ SG_ 1129 ReSideRdrRiStsRdrStsMisAlign "0, calibration not start. 1, successfully calibrated in factory or after-sales. 2, successfully auto-calibrated. 3, misalignment degree is larger than threshold, static calibration fail. 4, can not be calibrated statically cause other reason. 5, auto-calibrate fail (cause the misalignment degree is larger than threshold or other reason). 6, misalignment degree is larger than threshold, dynamic calibration fail in factory or after-sales. 7, can not be calibrated dynamically cause other reason.";
CM_ SG_ 1129 ReSideRdrRiStsRdrStsMissCom "Signal used to detect missing communication from radar.Reserved/";
CM_ SG_ 1129 ReSideRdrRiStsRdrStsSftyFlt "Safety faulty status";
CM_ SG_ 1129 ReSideRdrRiStsRdrStsTiStamp "Timestamp";
CM_ SG_ 1129 ReSideRdrRiStsRdrStsTiStampStsGlbTiBas "Time synchronization status - synchronized to global time base";
CM_ SG_ 1129 ReSideRdrRiStsRdrStsTiStampStsSyncToGatewy "Time synchronization status - synchronized to gateway";
CM_ SG_ 1129 ReSideRdrRiStsRdrStsTiStampStsTiLeap "Time synchronization status - time leap";
CM_ SG_ 1129 ReSideRdrRiStsRdrStsTiStampStsTiOut "Time synchronization status - time out";
CM_ SG_ 1129 ReSideRdrRiStsRdrStsWhlSpdCmpFac "reserved, not use";
CM_ SG_ 1281 WakeUpReasonsforADCU "WakeUpReasons";
CM_ SG_ 341 TripResetSyncReqMsgASDM "SecOC signal use";
CM_ SG_ 1345 VFCVectorASDMBlockID "Block Identifier";
CM_ SG_ 1345 VFCVectorASDMVFCid0 "SettingsComfort";
CM_ SG_ 1345 VFCVectorASDMVFCid1 "ParkingDrivingClimatization";
CM_ SG_ 1345 VFCVectorASDMVFCid10 "ExteriorLighting";
CM_ SG_ 1345 VFCVectorASDMVFCid11 "VFC11";
CM_ SG_ 1345 VFCVectorASDMVFCid12 "Alarm";
CM_ SG_ 1345 VFCVectorASDMVFCid13 "VFC13";
CM_ SG_ 1345 VFCVectorASDMVFCid14 "InteriorLighting";
CM_ SG_ 1345 VFCVectorASDMVFCid15 "VFC15";
CM_ SG_ 1345 VFCVectorASDMVFCid16 "Locking";
CM_ SG_ 1345 VFCVectorASDMVFCid17 "RemoteKeyFunctionality";
CM_ SG_ 1345 VFCVectorASDMVFCid18 "PropulsionStart";
CM_ SG_ 1345 VFCVectorASDMVFCid19 "VFC19";
CM_ SG_ 1345 VFCVectorASDMVFCid2 "PostClimatisation";
CM_ SG_ 1345 VFCVectorASDMVFCid20 "VFC20";
CM_ SG_ 1345 VFCVectorASDMVFCid21 "PowerClosures";
CM_ SG_ 1345 VFCVectorASDMVFCid22 "VehicleDriving";
CM_ SG_ 1345 VFCVectorASDMVFCid23 "VFC23";
CM_ SG_ 1345 VFCVectorASDMVFCid24 "SettingsProfile";
CM_ SG_ 1345 VFCVectorASDMVFCid25 "SeatComfortFunctions";
CM_ SG_ 1345 VFCVectorASDMVFCid26 "Brake";
CM_ SG_ 1345 VFCVectorASDMVFCid27 "InfotainmentPoll";
CM_ SG_ 1345 VFCVectorASDMVFCid28 "HVEnergyStorage";
CM_ SG_ 1345 VFCVectorASDMVFCid29 "VFC29";
CM_ SG_ 1345 VFCVectorASDMVFCid3 "PowertrainParkingClimatization";
CM_ SG_ 1345 VFCVectorASDMVFCid30 "TelematicsConnectivity";
CM_ SG_ 1345 VFCVectorASDMVFCid31 "VFC31";
CM_ SG_ 1345 VFCVectorASDMVFCid32 "VFC32";
CM_ SG_ 1345 VFCVectorASDMVFCid33 "Diagnostics";
CM_ SG_ 1345 VFCVectorASDMVFCid34 "VehicleModeManagement";
CM_ SG_ 1345 VFCVectorASDMVFCid35 "TrailerCaravanFunctions";
CM_ SG_ 1345 VFCVectorASDMVFCid36 "Immobilizer";
CM_ SG_ 1345 VFCVectorASDMVFCid37 "Windows";
CM_ SG_ 1345 VFCVectorASDMVFCid38 "Visibility";
CM_ SG_ 1345 VFCVectorASDMVFCid39 "VFC39";
CM_ SG_ 1345 VFCVectorASDMVFCid4 "VFC4";
CM_ SG_ 1345 VFCVectorASDMVFCid40 "VFC40";
CM_ SG_ 1345 VFCVectorASDMVFCid41 "InfotainmentPush";
CM_ SG_ 1345 VFCVectorASDMVFCid42 "ChargingHV";
CM_ SG_ 1345 VFCVectorASDMVFCid43 "BodyPreClimatisation";
CM_ SG_ 1345 VFCVectorASDMVFCid44 "Crash";
CM_ SG_ 1345 VFCVectorASDMVFCid45 "GlobalShortDuration";
CM_ SG_ 1345 VFCVectorASDMVFCid46 "ExteriorLightsHazard";
CM_ SG_ 1345 VFCVectorASDMVFCid47 "VFC47";
CM_ SG_ 1345 VFCVectorASDMVFCid48 "DoorOpenWarning";
CM_ SG_ 1345 VFCVectorASDMVFCid49 "ChargingLVInit";
CM_ SG_ 1345 VFCVectorASDMVFCid5 "VFC5";
CM_ SG_ 1345 VFCVectorASDMVFCid50 "VFC50";
CM_ SG_ 1345 VFCVectorASDMVFCid51 "VFC51";
CM_ SG_ 1345 VFCVectorASDMVFCid52 "HVBatteryThermalEventWarning";
CM_ SG_ 1345 VFCVectorASDMVFCid53 "VisualAssist";
CM_ SG_ 1345 VFCVectorASDMVFCid54 "PassiveSafety";
CM_ SG_ 1345 VFCVectorASDMVFCid55 "LifeDetection";
CM_ SG_ 1345 VFCVectorASDMVFCid56 "BackboneFlexray";
CM_ SG_ 1345 VFCVectorASDMVFCid57 "Functionmarket";
CM_ SG_ 1345 VFCVectorASDMVFCid58 "VFC58";
CM_ SG_ 1345 VFCVectorASDMVFCid59 "VFC59";
CM_ SG_ 1345 VFCVectorASDMVFCid6 "SettingsVehicle";
CM_ SG_ 1345 VFCVectorASDMVFCid60 "VFC60";
CM_ SG_ 1345 VFCVectorASDMVFCid61 "VFC61";
CM_ SG_ 1345 VFCVectorASDMVFCid7 "VFC7";
CM_ SG_ 1345 VFCVectorASDMVFCid8 "VFC8";
CM_ SG_ 1345 VFCVectorASDMVFCid9 "IPWakeup";
CM_ SG_ 257 AbsCtrlActvChks "checksum";
CM_ SG_ 257 AbsCtrlActvCntr "counter";
CM_ SG_ 257 AbsCtrlActvCtrlSts1 "Anti Blocking Systems (ABS) control is active (at least one wheel)
0 = No wheel is in Anti Blocking Systems (ABS) control
1 = At least one wheel is in Anti Blocking Systems (ABS) control";
CM_ SG_ 257 AsyALgtCtrlModCfmdAsyALgtCtrlMod1 "to feedback the confirmation of AsyALgtCtrlMod";
CM_ SG_ 257 AsyALgtCtrlModCfmdChks "checksum";
CM_ SG_ 257 AsyALgtCtrlModCfmdCntr "rollingcounter";
CM_ SG_ 257 AutHldAvlSt "AVH function available status";
CM_ SG_ 257 AxleSlipRelAct "Wheel slip difference between front and rear axle. Slip difference = front slip - rear slip (independent of vehicle direction which needs to be considered by subscriber). Compensated for variation of tire radius
";
CM_ SG_ 257 BrkFricTqAtWhlActBrkFricTqAtWhlFrntLeAct "Actual service brake torque for each wheel. Brake torque acting on the front left wheel. Based on nominal brake parameters (e.g. constant pads friction) and (estimated) brake pressures (clamp forces). Not included: parking brake torque or regenerative brake torque.";
CM_ SG_ 257 BrkFricTqAtWhlActBrkFricTqAtWhlFrntRiAct "Actual service brake torque for each wheel. Brake torque acting on the front right wheel. Based on nominal brake parameters (e.g. constant pads friction) and (estimated) brake pressures (clamp forces). Not included: parking brake torque or regenerative brake torque.";
CM_ SG_ 257 BrkFricTqAtWhlActBrkFricTqAtWhlReLeAct "Actual service brake torque for each wheel. Brake torque acting on the rear left wheel. Based on nominal brake parameters (e.g. constant pads friction) and (estimated) brake pressures (clamp forces). Not included: parking brake torque or regenerative brake torque.";
CM_ SG_ 257 BrkFricTqAtWhlActBrkFricTqAtWhlReRiAct "Actual service brake torque for each wheel. Brake torque acting on the rear right wheel. Based on nominal brake parameters (e.g. constant pads friction) and (estimated) brake pressures (clamp forces). Not included: parking brake torque or regenerative brake torque.";
CM_ SG_ 257 BrkTqAtWhlsReq "Contains driver requested brake torque and driver support system requested brake torque. The signal is always positive and acts in opposite vehicle motion direction.";
CM_ SG_ 257 BrkTqChks "Checksum";
CM_ SG_ 257 BrkTqCntr "counter";
CM_ SG_ 257 BrkTqQf "quality factor";
CM_ SG_ 257 BrkTqRgnAtAxleReReq " Requested rear brake torque from brake control to be actuated by powertrain.";
CM_ SG_ 257 BrkTqSts "brake status";
CM_ SG_ 257 BrkTqTotReqForPt " Requested brake torque from brake control to be actuated by powertrain.";
CM_ SG_ 257 DrvrBrkTqAtWhlsReqdChks "Checksum for E2E";
CM_ SG_ 257 DrvrBrkTqAtWhlsReqdCntr "Counter for E2E";
CM_ SG_ 257 DrvrBrkTqAtWhlsReqdDrvrBrkTqAtWhlsReqd "Driver requested brake torque at wheels.";
CM_ SG_ 257 DrvrBrkTqAtWhlsReqdQf "Quality factor of driver requested brake torque at wheels ";
CM_ SG_ 257 EscVariantToDmcChks "Chks";
CM_ SG_ 257 EscVariantToDmcCntr "Cntr";
CM_ SG_ 257 EscVariantToDmcEscVariantToDmc "Esc Variant";
CM_ SG_ 257 FricEstimnFromVehDynFricEstimnFromVehDyn "momentary friction estimate";
CM_ SG_ 257 FricEstimnFromVehDynQly "quality of momentary friction estimate";
CM_ SG_ 257 LatCtrlReqSafeChks "Requests for lateral control by steering actuator. Checksum";
CM_ SG_ 257 LatCtrlReqSafeCntr "Requests for lateral control by steering actuator. Counter";
CM_ SG_ 257 LatCtrlReqSafeLatCtrlModReq "Request";
CM_ SG_ 257 LatCtrlReqSafeSteerTqReq "Requests for lateral control by steering actuator. Steering wheel torque request.";
CM_ SG_ 257 LatCtrlReqSafeSteerWhlHptcWarnReq "Enable steering wheel haptic warning";
CM_ SG_ 257 LgtCtrlModReqSafeChks "checksum";
CM_ SG_ 257 LgtCtrlModReqSafeCntr "counter";
CM_ SG_ 257 LgtCtrlModReqSafeLgtCtrlModReqSafe "Ctrl mode";
CM_ SG_ 257 LgtCtrlModReqSafeLgtFctFailr "Failure mode";
CM_ SG_ 257 PrpsnTqForBrkRels "Propulsion torque limitation for comfort.";
CM_ SG_ 257 PtTqAtAxleMinReqChks "checksum";
CM_ SG_ 257 PtTqAtAxleMinReqCntr "counter";
CM_ SG_ 257 PtTqAtAxleMinReqPtTqAtAxleFrntReq "Minmum allowed powertrain applied torque on the front axle.";
CM_ SG_ 257 PtTqAtAxleMinReqPtTqAtAxleReReq "Minmum allowed powertrain applied torque on the rear axle.";
CM_ SG_ 257 PtTqAtAxleReMinSlowReq "Predicted rear axle minimum torque requested by RSC to powertrain";
CM_ SG_ 257 PtTqSoftMaxGenn2Allwd "maximal allowed vehicle propulsion torque for autonomous driving";
CM_ SG_ 257 PtTqSoftMaxGenn2AllwdChks "checksum";
CM_ SG_ 257 PtTqSoftMaxGenn2AllwdCntr "counter";
CM_ SG_ 257 StcStsToDmcChks "Chks";
CM_ SG_ 257 StcStsToDmcCntr "Cntr";
CM_ SG_ 257 StcStsToDmcEngRotTarSpdDMCFrnt "Target Moto speed";
CM_ SG_ 257 StcStsToDmcEngRotTarSpdDMCRear "Target Moto speed
";
CM_ SG_ 257 StcStsToDmcFrnt "StcSts to Dmc frint";
CM_ SG_ 257 StcStsToDmcRear "StcSts to DMC Rear";
CM_ SG_ 257 SteerAssiCtrlSts "steering assist control status";
CM_ SG_ 257 TqRednDurgCllsnMtgtnByBrkg "Propulsion torque reduction during safety braking.";
CM_ SG_ 1025 AbsCtrlActvForWhlFrntLe "Anti Blocking Systems (ABS) control is active or not (for front left wheel)";
CM_ SG_ 1025 AbsCtrlActvForWhlFrntRi "Anti Blocking Systems (ABS) control is active or not (for front right wheel)";
CM_ SG_ 1025 AbsCtrlActvForWhlReLe "Anti Blocking Systems (ABS) control is active or not (for rear left wheel)";
CM_ SG_ 1025 AbsCtrlActvForWhlReRi "Anti Blocking Systems (ABS) control is active or not (for rear right wheel)";
CM_ SG_ 1025 ALgtStdFromWhlSpdALgtStdFromWhlSpd "Longitudinal acceleration over ground.
end2endprotection=profile1A dataid= 12345 Longitudinal acceleration over ground";
CM_ SG_ 1025 ALgtStdFromWhlSpdChks "Longitudinal acceleration over ground.
end2endprotection=profile1A dataid=12345 Checksum for longitudinal acceleration over ground";
CM_ SG_ 1025 ALgtStdFromWhlSpdCntr "Longitudinal acceleration over ground.
end2endprotection=profile1A dataid=12345 Counter for longitudinal acceleration over ground";
CM_ SG_ 1025 ALgtStdFromWhlSpdQf "Longitudinal acceleration over ground.
end2endprotection=profile1A dataid=12345 Qf for longitudinal acceleration over ground";
CM_ SG_ 1025 BrkPAtWhlFL "Brake pressure at wheel Front Left";
CM_ SG_ 1025 BrkPAtWhlFR "Brake pressure at wheel Front Right";
CM_ SG_ 1025 BrkPAtWhlRL "Brake pressure at wheel Rear Left";
CM_ SG_ 1025 BrkPAtWhlRR "Brake pressure at wheel Rear Right";
CM_ SG_ 1025 PitchAgGlbQf " Qualifier flag";
CM_ SG_ 1025 PitchAgGlbVal " Pitch angle of vehicle in radians";
CM_ SG_ 1025 RoadLoadNomCoeff0 "Polynom coefficients for road load estimation f0Nom";
CM_ SG_ 1025 RoadLoadNomCoeff1 "Polynom coefficients for road load estimation f1Nom";
CM_ SG_ 1025 RoadLoadNomCoeff2 "Polynom coefficients for road load estimation f2Nom";
CM_ SG_ 1025 RoadLoadNomCoeffSts "Polynom coefficients for road load estimation Calculated road load avaliable";
CM_ SG_ 1025 StandStillMgrStsForHldByBrkChks "chks";
CM_ SG_ 1025 StandStillMgrStsForHldByBrkCntr "cntr";
CM_ SG_ 1025 StandStillMgrStsForHldByBrkStandStillMgrStsForHld1 "Brake system hold status";
CM_ SG_ 1025 StandStillMgrStsForPark "Stand still manager status for park.";
CM_ SG_ 1025 TrlrModBCSts "TrlrModBCSts";
CM_ SG_ 1025 YawStabyCtrlActv "Indicates InCtrl if AYC or ARP is requesting wheel torque for control of vehicle yaw movement.";
CM_ SG_ 483 AbsSts "Indicates if the ABS function is temporarily or permantly disabled due to a failure.";
CM_ SG_ 483 AsyActrActvForLgtCtrl "Signals which longitudinal actuator that is actively controlling the vehicle for autonomous driving.";
CM_ SG_ 483 AsySftyDecelEnadByVehDyn "Signal indicating that autonomous braking in safety critical situation is allowed by vehicle dynamics.";
CM_ SG_ 483 AsySftyEnaDecelAckd "Acknowledged signal from receiver for Brake gain enable signal. Acknowledged signal from receiver for enable signal for deceleration in safety critical situation.";
CM_ SG_ 483 BrkPedlrRatPerc "Brake pedal Ratio in percentage value";
CM_ SG_ 483 BrkPedlrRatQf "quality factor";
CM_ SG_ 483 EscActvCtrlIndcdToDrvr "information about Esc significant intervention indication to the driver is requested by the Esc function. Indication to driver is only done for certain sub-functions of the Esc system.";
CM_ SG_ 483 HsaSt "HSA function status";
CM_ SG_ 483 InhbOfAsySftyDecelByVehDyn "service brake deceleration request response flag";
CM_ SG_ 483 LimForDecelChks "Vehicle deceleration limit monitor information Checksum";
CM_ SG_ 483 LimForDecelCntr "Vehicle deceleration limit monitor information Counter";
CM_ SG_ 483 LimForDecelNotExcd "Vehicle deceleration limit monitor information Information will be set to YES as long as the vehicle deceleration limit is not exceeded";
CM_ SG_ 483 MsgReqByHillDwnCtrl "Text message request from HDC function for driver information about current HDC state.";
CM_ SG_ 483 RctaBrkActvd "RCTA brake response flag";
CM_ SG_ 483 RcwmBrkActvd "RCWM brake actuation is activated.";
CM_ SG_ 483 SuspPosnVertAgGenQf "External CAN signal for inform the rear angle that are calculated from front and rear body height. This signal are used for head lamp control.";
CM_ SG_ 483 SuspPosnVertAgSuspPosnVertAg "External CAN signal for inform the rear angle that are calculated from front and rear body height. This signal are used for head lamp control.";
CM_ SG_ 483 SuspPosnVertLvlFrnt "Front suspension level";
CM_ SG_ 483 SuspPosnVertLvlFrntQf "Front Qf";
CM_ SG_ 483 SuspPosnVertLvlRe "Rear suspension level";
CM_ SG_ 483 SuspPosnVertLvlReQf "Rear Qf";
CM_ SG_ 483 WhlBrkOvrheatd "wheel brake overheating Indication that at least one wheel brake (caliper, disc, pad) temperature is high.";
CM_ SG_ 483 WhlSpdCalcALgtALgt " Longitudinal acceleration based on wheel speed sensors";
CM_ SG_ 483 WhlSpdCalcALgtChks " Checksum for longitudinal acceleration based on wheel speed sensors";
CM_ SG_ 483 WhlSpdCalcALgtCntr " Counter for longitudinal acceleration based on wheel speed sensors";
CM_ SG_ 816 AbsClrRdyReq "Readiness Clear Signal";
CM_ SG_ 816 BrkTracCtrlActvForWhlFrntLe "Brake traction control active intervention information for front left";
CM_ SG_ 816 BrkTracCtrlActvForWhlFrntRi "Brake traction control active intervention information for front right";
CM_ SG_ 816 BrkTracCtrlActvForWhlReLe "Brake traction control active intervention information for rear left";
CM_ SG_ 816 BrkTracCtrlActvForWhlReRi "Brake traction control active intervention information for rear right";
CM_ SG_ 816 EpbLampReqChks "check sum";
CM_ SG_ 816 EpbLampReqCntr "counter";
CM_ SG_ 816 EpbLampReqEpbLampReq "E2E secured Epb request to display Red EPB tell tale.
Record has checksum and counter Epb lamp request
";
CM_ SG_ 816 RollAgGlbQf "Lateral inclination of vehicle against horizon Qualifier flag";
CM_ SG_ 816 RollAgGlbVal "Lateral inclination of vehicle against horizon Roll angle in radians";
CM_ SG_ 800 AbsErrIndcnReq "MIL indication activation request";
CM_ SG_ 800 PostImpctBrkgRdy "Information regarding if Post Impact Braking support is available from VDDM.";
CM_ SG_ 800 WhlBrkWrm " Indication of warm wheel brakes";
CM_ SG_ 384 AsyALgtActvAftLim "Latest active acceleration request downstream comfort rate limiter located in actuator node.";
CM_ SG_ 384 BrkFricTqTotAtWhlsActBrkFricTqTotAtWhlsAct "Total actual friction brake toque at all four wheels.";
CM_ SG_ 384 BrkFricTqTotAtWhlsActChks "Total actual friction brake toque at all four wheels. Checksum";
CM_ SG_ 384 BrkFricTqTotAtWhlsActCntr "Total actual friction brake toque at all four wheels. Counter";
CM_ SG_ 384 BrkPedlPsdBrkPedlNotPsdSafe "Set to 1 if brake pedal is not pressed, otherwise 0";
CM_ SG_ 384 BrkPedlPsdBrkPedlPsd "Set to 1 if brake pedal is pressed, otherwise 0";
CM_ SG_ 384 BrkPedlPsdChks "Checksum";
CM_ SG_ 384 BrkPedlPsdCntr "Counter";
CM_ SG_ 384 BrkPedlPsdQf "Quality factor";
CM_ SG_ 384 BrkPedlTrvlAct "Information about driver brake request derived from the travel sensor in the brake booster. Actual value for the output rod";
CM_ SG_ 384 BrkPedlTrvlChks "Information about driver brake request derived from the travel sensor in the brake booster. Checksum";
CM_ SG_ 384 BrkPedlTrvlCntr "Information about driver brake request derived from the travel sensor in the brake booster. Counter";
CM_ SG_ 384 BrkPedlTrvlQf "Information about driver brake request derived from the travel sensor in the brake booster. Travel sensor quality factor";
CM_ SG_ 384 BrkPedlTrvlSt "Information about driver brake request derived from the travel sensor in the brake booster. Brake pedal applied information";
CM_ SG_ 384 BrkPedlTrvlStQf "Information about driver brake request derived from the travel sensor in the brake booster. Brake pedal applied information quality factor";
CM_ SG_ 384 BrkPedlTrvlTar "Information about driver brake request derived from the travel sensor in the brake booster. Target value for the output rod";
CM_ SG_ 384 BrkSysCylPMstAct "Brake system master cylinder pressure information Actual pressure, raw value";
CM_ SG_ 384 BrkSysCylPMstActQf "Brake system master cylinder pressure information Actual pressure quality factor";
CM_ SG_ 384 BrkSysCylPMstChks "Brake system master cylinder pressure information Checksum";
CM_ SG_ 384 BrkSysCylPMstCntr "Brake system master cylinder pressure information Counter";
CM_ SG_ 384 BrkSysCylPMstTar "Brake system master cylinder pressure information Target pressure";
CM_ SG_ 384 BrkSysCylPMstVirt "Brake system master cylinder pressure information Virtual pressure";
CM_ SG_ 384 BrkSysCylPMstVirtQf "Brake system master cylinder pressure information Virtual pressure quality factor";
CM_ SG_ 384 DrvrDecelReqChks "Checksum";
CM_ SG_ 384 DrvrDecelReqCntr "Counter";
CM_ SG_ 384 DrvrDecelReqFloat8 "Driver deacceleration request";
CM_ SG_ 384 EngRunngReqByBrk "Engine running request from vehicle dynamics and brake functions.";
CM_ SG_ 384 EpbActrStPrim "EPB actuator state for Primary EPB ECU. Only valid for Dual EPB";
CM_ SG_ 384 EpbStsChks "Electrical Park Brake system status information Status for the rear wheel park actuator";
CM_ SG_ 384 EpbStsCntr "Electrical Park Brake system status information Counter for EPB status";
CM_ SG_ 384 EpbStsEpbSts "Electrical Park Brake system status information Status for the rear wheel park actuator";
CM_ SG_ 384 EscCtrlIndcn "Indicates that an Electronic stability control (ESC) controller is active";
CM_ SG_ 384 EscGearShiftInhbReq "Gear shift recommendation fron ESC function.";
CM_ SG_ 384 EscStChks "Information on activation/ deactivation of Electronic Stability Control (ESC) Checksum for Esc state";
CM_ SG_ 384 EscStCntr "Information on activation/ deactivation of Electronic Stability Control (ESC) Counter for Esc state";
CM_ SG_ 384 EscStEscSt "Information on activation/ deactivation of Electronic Stability Control (ESC) Esc state information for Esc ON, Esc OFF or Esc Sport";
CM_ SG_ 384 LimForJerkPosNotExcdChks "Indicates if the positive jerk or deceleration limitation is not exceeded.
Yes = Limit not exceeded
No = Limit is exceeded Checksum";
CM_ SG_ 384 LimForJerkPosNotExcdCntr "Indicates if the positive jerk or deceleration limitation is not exceeded.
Yes = Limit not exceeded
No = Limit is exceeded Counter";
CM_ SG_ 384 LimForJerkPosNotExcdLimForJerkPosNotExcd "Indicates if the positive jerk or deceleration limitation is not exceeded.
Yes = Limit not exceeded
No = Limit is exceeded Information will be set to Yes as long as the positive jerk limit is not exceeded";
CM_ SG_ 384 PtTqAtAxleAddReqChks "Additive propulsion torque request from dynamic torque vectoring function. Checksum";
CM_ SG_ 384 PtTqAtAxleAddReqCntr "Additive propulsion torque request from dynamic torque vectoring function. Counter";
CM_ SG_ 384 PtTqAtAxleAddReqPtTqAtAxleAddFrntReq "Additive propulsion torque request from dynamic torque vectoring function. Additive torque request for front axle";
CM_ SG_ 384 PtTqAtAxleAddReqPtTqAtAxleAddReReq "Additive propulsion torque request from dynamic torque vectoring function. Additive torque request for rear axle";
CM_ SG_ 384 PtTqChks " Checksum";
CM_ SG_ 384 PtTqCntr " Counter";
CM_ SG_ 384 PtTqHardMaxChks " Checksum";
CM_ SG_ 384 PtTqHardMaxCntr " Counter";
CM_ SG_ 384 PtTqHardMaxGrdtNeg " Allowed negative propulsion torque gradient";
CM_ SG_ 384 PtTqHardMaxGrdtPos " Allowed positiv propulsion torque gradient";
CM_ SG_ 384 PtTqHardMaxReq " Maximum vehicle propulsion torque request";
CM_ SG_ 384 PtTqMinReq " Vehicle propulsion torque min request.";
CM_ SG_ 384 PtTqSetSafeChks "checksum";
CM_ SG_ 384 PtTqSetSafeCntr "counter";
CM_ SG_ 384 PtTqSetSafeGrdtNeg "Negative Gradient limit";
CM_ SG_ 384 PtTqSetSafeGrdtPos "Positive gradient limit";
CM_ SG_ 384 PtTqSetSafeReq "Request";
CM_ SG_ 384 PtTqSoftMaxReq " Maximum vehicle propulsion torque request. This request is possible to overide in propulsion system.";
CM_ SG_ 384 RoadInclnQly "Road inclination information. The road inclination is negative when the vehicle is facing uphill and positive when the vehicle is facing downhill. Quality information for road inclination";
CM_ SG_ 384 RoadInclnRoadIncln "Road inclination information. The road inclination is negative when the vehicle is facing uphill and positive when the vehicle is facing downhill.";
CM_ SG_ 384 SpdRotlForWhlsAtAxleFrntChks "Average angular velocity of front wheels. Checksum";
CM_ SG_ 384 SpdRotlForWhlsAtAxleFrntCntr "Average angular velocity of front wheels. Counter";
CM_ SG_ 384 SpdRotlForWhlsAtAxleFrntSpdRotlForWhlsAtAxleFrnt "Average angular velocity of front wheels.";
CM_ SG_ 384 SpdRotlForWhlsAtAxleRe "Average angular velocity of rear wheels.";
CM_ SG_ 608 AutoShowModBCEna "AutoShowMode eable status";
CM_ SG_ 608 EpbDrvrDisp "Request to HMI to display predefined messages and symbols for EPB function.";
CM_ SG_ 608 ImobBrkNrSerl0 "Containing BCM serial nr. Used for immo authentication. Byte 0";
CM_ SG_ 608 ImobBrkNrSerl1 "Containing BCM serial nr. Used for immo authentication. Byte 1";
CM_ SG_ 608 ImobBrkNrSerl2 "Containing BCM serial nr. Used for immo authentication. Byte 2";
CM_ SG_ 608 ImobBrkNrSerl3 "Containing BCM serial nr. Used for immo authentication. Byte 3";
CM_ SG_ 608 ImobBrkNrSerl4 "Containing BCM serial nr. Used for immo authentication. Byte 4";
CM_ SG_ 608 ImobBrkNrSerl5 "Containing BCM serial nr. Used for immo authentication. Byte 5";
CM_ SG_ 608 WhlRotCntrFrnt "Average front wheel-revolutions to be used for distance measurement. One counter increase means one completed average front wheel revolution. ";
CM_ SG_ 997 BkpOfDstTrvldFromBrk "Saved backupvalue";
CM_ SG_ 997 DstTrvldVldFromBrkBkp "Indication if the transmitted backupvalue is valid or not";
CM_ SG_ 997 EmgyBrkLiReqChks "check sum";
CM_ SG_ 997 EmgyBrkLiReqCntr "counter";
CM_ SG_ 997 EmgyBrkLiReqEmgyBrk "Emergency brake light (EBL) request";
CM_ SG_ 997 EPBLockChkChk "Challenge available flag";
CM_ SG_ 997 EPBLockChkData0 "Challenge data";
CM_ SG_ 997 EPBLockChkData1 "Challenge data";
CM_ SG_ 997 EPBLockChkData2 "Challenge data";
CM_ SG_ 997 EPBLockChkData3 "Challenge data";
CM_ SG_ 997 EPBLockChkData4 "Challenge data";
CM_ SG_ 997 EPBLockChkData5 "Challenge data";
CM_ SG_ 997 EPBLockChkData6 "Challenge data";
CM_ SG_ 997 EPBLockSts "BCM - CEM message immo status. Can be undefined, immobilised, motive mobilised or non motive mobilised.";
CM_ SG_ 997 IndcnToDrvrPostImpctCtrl " Request for driver information for post impact control related functionality.";
CM_ SG_ 997 SteerAssiAvlSts "steer assist available status
";
CM_ SG_ 997 SteerAssiWarnMsg "steering assist warning message
";
CM_ SG_ 997 VBFAvlSts "VBF funtion status";
CM_ SG_ 997 VehSpdLgtTar "Target speed";
CM_ SG_ 1040 BrkBoostClrRdyReq "Status";
CM_ SG_ 576 BrkSysStsADL3BrkFallBck "ADL3";
CM_ SG_ 576 BrkSysStsBrkDegradation "Degradation mode";
CM_ SG_ 576 BrkSysStsBrkSysCapability "Brake capability";
CM_ SG_ 576 BrkSysStsBrkSysModCfmd "Mode confirmation";
CM_ SG_ 576 BrkSysStsChks "checksum";
CM_ SG_ 576 BrkSysStsCntr "counter";
CM_ SG_ 576 EscWarnIndcnReqChks "Esc warning indication request or indication to driver that the Esc function is in active intervention. In case of disabled Esc the warning telltale shall be permanently lit. In case of active intervention indication the telltale will flash. Checksum for Esc warning indication request";
CM_ SG_ 576 EscWarnIndcnReqCntr "Esc warning indication request or indication to driver that the Esc function is in active intervention. In case of disabled Esc the warning telltale shall be permanently lit. In case of active intervention indication the telltale will flash. Counter for Esc warning indication request";
CM_ SG_ 576 EscWarnIndcnReqEscWarnIndcnReq "Esc warning indication request or indication to driver that the Esc function is in active intervention. In case of disabled Esc the warning telltale shall be permanently lit. In case of active intervention indication the telltale will flash. Esc warning indication request
";
CM_ SG_ 576 LampReqByVehHld "Request to display Autohold function symbol in DIM. 0=OFF, 1=ON.";
CM_ SG_ 949 AutHldSoftSwtEnaSts "Auto Hold Soft Switch Enable Status";
CM_ SG_ 949 BrkAndAbsWarnIndcnReqAbsWarnIndcnReq "Request for warning indication to driver in case of brake failure (red warning) or ABS failure (yellow warning) ABS warning indication request";
CM_ SG_ 949 BrkAndAbsWarnIndcnReqBrkWarnIndcnReq "Request for warning indication to driver in case of brake failure (red warning) or ABS failure (yellow warning) Brake warning indication request";
CM_ SG_ 949 BrkAndAbsWarnIndcnReqChks "Request for warning indication to driver in case of brake failure (red warning) or ABS failure (yellow warning) Checksum for Brake and ABS warning indication request";
CM_ SG_ 949 BrkAndAbsWarnIndcnReqCntr "Request for warning indication to driver in case of brake failure (red warning) or ABS failure (yellow warning) Counter for Brake and ABS warning indication request";
CM_ SG_ 949 BrkBoostErrIndcnReq "BBM";
CM_ SG_ 949 BrkByWireWarnIndcn "Warning indication for vehicles with hybrid brake system.";
CM_ SG_ 949 BrkFldLvl "brake fule level";
CM_ SG_ 949 BrkMsgForHybWarnReq "NoReq = No text message requested 
Msg1 = Brake pedal characteristics changed
Msg2 = Reserved for future functionality
Msg3 = Reserved for future functionality
Msg4 = Reserved for future functionality
Msg5 = Reserved for future functionality
Msg6 = Reserved for future functionality
Msg7 = Reserved for future functionality";
CM_ SG_ 949 BrkMsgForLoVacReqd "Warning message for low brake vacuum.";
CM_ SG_ 949 BrkMsgWarnReq "NoReq = No text message requested 
Msg1 = Brake failure stop safely
Msg2 = ABS/ESC service required
Msg3 = ABS/ESC temporarily off
Msg4 = ESC service required
Msg5 = ESC temporarily off
Msg6 = Traction control temporarily off
Msg7 = Reserved for future functionality";
CM_ SG_ 949 BrkMsgWarnReqForHmi "Brake system warning message";
CM_ SG_ 949 BrkRelsWarnReq "Driver warning during vehicle standstill for releasing the brakes without possibility to park the vehicle.";
CM_ SG_ 949 BrkSysWarnIndcnReq " Yellow Brake Warning Tell tale request";
CM_ SG_ 949 CstCtrlActvCstCtrlEab "this element is for function is enable or disable.";
CM_ SG_ 949 CstCtrlActvCtrlSts1 "this element is for function active or disactive";
CM_ SG_ 949 DispMsgByVehHld "Signal values indicate which of the predefined messages that HMI shall display";
CM_ SG_ 949 DrvModEscOffChks "checksum";
CM_ SG_ 949 DrvModEscOffCntr "counter";
CM_ SG_ 949 DrvModEscOffDrvModEscOff "Driver mode Esc off";
CM_ SG_ 949 EpbApplyEna "EPB software apply button enable";
CM_ SG_ 949 EpbRelsEna "EPB software release button enable";
CM_ SG_ 805 SwtStsforHillDwnCtrl "HDC function software switch status";
CM_ SG_ 704 TireRdEstimd "tire radius estimated";
CM_ SG_ 402 AsyLatCtrlModReqGroupCfmdChks "checlksum";
CM_ SG_ 402 AsyLatCtrlModReqGroupCfmdCntr "Counter";
CM_ SG_ 402 AsyLatCtrlModReqGroupCfmdLatCtrlMod "Lateral control mode confirmation";
CM_ SG_ 402 BrkLiOnReqChks "0: No request for brake light.
1: Brake light illumination shall be requested due to an autonomous brake intervention. Information about driver braking, by brake pedal, is NOT contained in this signal. Checksum for the record";
CM_ SG_ 402 BrkLiOnReqCntr "0: No request for brake light.
1: Brake light illumination shall be requested due to an autonomous brake intervention. Information about driver braking, by brake pedal, is NOT contained in this signal. Counter for the record";
CM_ SG_ 402 BrkLiOnReqSts "0: No request for brake light.
1: Brake light illumination shall be requested due to an autonomous brake intervention. Information about driver braking, by brake pedal, is NOT contained in this signal. Whether brake lights are requested or not. Default is not requested.";
CM_ SG_ 402 PrkLatLgtFailrChks "Checksum";
CM_ SG_ 402 PrkLatLgtFailrCntr "Counter";
CM_ SG_ 402 PrkLatLgtFailrPrkLatLgtFailr "Failure mode";
CM_ SG_ 402 StandStillMgrStsForHld1 "Brake systen hold status";
CM_ SG_ 402 StandStillMgrStsForHldChks "chks";
CM_ SG_ 402 StandStillMgrStsForHldCntr "cntr";
CM_ SG_ 402 VehMNomTrlrM "Estimated vehicle mass including trailer. Estimated trailer mass";
CM_ SG_ 402 VehMNomVehM "Estimated vehicle mass including trailer. Vehicle mass including trailer mass (if connected).";
CM_ SG_ 402 VehMNomVehMQly "Estimated vehicle mass including trailer. Quality for vehicle mass information";
CM_ SG_ 402 VehVLat "Vehicle lateral and longitudinal velocity. Vehicle lateral velocity";
CM_ SG_ 402 VehVLatQf "Vehicle lateral and longitudinal velocity. Vehicle lateral velocity QF";
CM_ SG_ 402 VehVLgt "Vehicle lateral and longitudinal velocity. Vehicle longitudinal velocity";
CM_ SG_ 402 VehVLgtQf "Vehicle lateral and longitudinal velocity. Vehicle longitudinal velocity QF";
CM_ SG_ 402 WhlDirRotlFrntChks "check sum";
CM_ SG_ 402 WhlDirRotlFrntCntr "counter";
CM_ SG_ 402 WhlDirRotlFrntLe "Rotational direction for the front individual wheels. Wheel rotation direction of front left wheel.";
CM_ SG_ 402 WhlDirRotlFrntRi "Rotational direction for the front individual wheels. Wheel rotation direction of front right wheel.";
CM_ SG_ 402 WhlDirRotlReChks "checksum";
CM_ SG_ 402 WhlDirRotlReCntr "counter";
CM_ SG_ 402 WhlDirRotlReLe "Rotational direction for the rear individual wheels. Wheel rotation direction of rear left wheel.";
CM_ SG_ 402 WhlDirRotlReRi "Rotational direction for the rear individual wheels. Wheel rotation direction of rear right wheel.";
CM_ SG_ 402 WhlFastSpdSafeA "Vehicle speed longitudinal based on wheel speed sensors and longitudinal acceleration.";
CM_ SG_ 402 WhlFastSpdSafeChks "checksum";
CM_ SG_ 402 WhlFastSpdSafeCntr "counter";
CM_ SG_ 402 WhlFastSpdSafeQF "Quality factor for vehicle speed as measured by wheel speed sensors and longitudinal acceleration.";
CM_ SG_ 402 WhlRotToothCntrChks "check sum";
CM_ SG_ 402 WhlRotToothCntrCntr "counter";
CM_ SG_ 402 WhlRotToothCntrFrntLe "Wheel rotation ticks for each individual wheel. Wheel rotation impuls counter front left. For one complete wheel revolution the counter will increase by 96 (with 48 magnetic pole-pairs).";
CM_ SG_ 402 WhlRotToothCntrFrntRi "Wheel rotation ticks for each individual wheel. Wheel rotation impuls counter front right. For one complete wheel revolution the counter will increase by 96 (with 48 magnetic pole-pairs).";
CM_ SG_ 402 WhlRotToothCntrReLe "Wheel rotation ticks for each individual wheel. Wheel rotation impuls counter rear left. For one complete wheel revolution the counter will increase by 96 (with 48 magnetic pole-pairs).";
CM_ SG_ 402 WhlRotToothCntrReRi "Wheel rotation ticks for each individual wheel. Wheel rotation impuls counter rear right. For one complete wheel revolution the counter will increase by 96 (with 48 magnetic pole-pairs).";
CM_ SG_ 402 WhlSpdCircumlFrntChks "Individual wheel speed from front wheel speed sensors. Checksum";
CM_ SG_ 402 WhlSpdCircumlFrntCntr "Individual wheel speed from front wheel speed sensors. Counter";
CM_ SG_ 402 WhlSpdCircumlFrntLe "Individual wheel speed from front wheel speed sensors. Wheel speed from front left wheel speed sensor using nominal value of wheel radius.";
CM_ SG_ 402 WhlSpdCircumlFrntLeQf "Individual wheel speed from front wheel speed sensors. Qf for wheel speed sensor";
CM_ SG_ 402 WhlSpdCircumlFrntRiQf "Individual wheel speed from front wheel speed sensors. Qf for wheel speed sensor";
CM_ SG_ 402 WhlSpdCircumlFrntWhlSpdCircumlFrntRi "Individual wheel speed from front wheel speed sensors. Wheel speed from front right wheel speed sensor using nominal value of wheel radius";
CM_ SG_ 402 WhlSpdCircumlReChks "Individual wheel speed from rear wheel speed sensors. Checksum";
CM_ SG_ 402 WhlSpdCircumlReCntr "Individual wheel speed from rear wheel speed sensors. Counter";
CM_ SG_ 402 WhlSpdCircumlReLe "Individual wheel speed from rear wheel speed sensors. Wheel speed from rear left wheel speed sensor using nominal value of wheel radius.";
CM_ SG_ 402 WhlSpdCircumlReLeQf "Individual wheel speed from rear wheel speed sensors. Qf for wheel speed sensor";
CM_ SG_ 402 WhlSpdCircumlReRi "Individual wheel speed from rear wheel speed sensors. Wheel speed from rear right wheel speed sensor using nominal value of wheel radius.";
CM_ SG_ 402 WhlSpdCircumlReRiQf "Individual wheel speed from rear wheel speed sensors. Qf for wheel speed sensor";
CM_ SG_ 402 YawRateReqdByDrvr "When the vehicle is making a left turn this signal is supposed to show positive numbers. Unfiltered and offset compensated plausibility check";
CM_ SG_ 98 VehDynCtrlStsForALgtCmftVehDynCtrlStsChks "Arbitrator and actuator status for the vehicle longitudianal acceleration comfort control. Checksum";
CM_ SG_ 98 VehDynCtrlStsForALgtCmftVehDynCtrlStsCntr "Arbitrator and actuator status for the vehicle longitudianal acceleration comfort control. Counter";
CM_ SG_ 98 VehDynCtrlStsForALgtCmftVehDynCtrlStsDend "Arbitrator and actuator status for the vehicle longitudianal acceleration comfort control. Longitudinal acceleration control for comfort denied";
CM_ SG_ 98 VehDynCtrlStsForALgtCmftVehDynCtrlStsForBrkActv "Arbitrator and actuator status for the vehicle longitudianal acceleration comfort control. Brake actuator active for comfort braking";
CM_ SG_ 98 VehDynCtrlStsForALgtCmftVehDynCtrlStsForBrkPrecActv "Arbitrator and actuator status for the vehicle longitudianal acceleration comfort control. Brake actuator prefill active";
CM_ SG_ 98 VehDynCtrlStsForALgtCmftVehDynCtrlStsForStandStillMgrForPark "Arbitrator and actuator status for the vehicle longitudianal acceleration comfort control. Stand still staus for park";
CM_ SG_ 98 VehDynCtrlStsForALgtCmftVehDynCtrlStsForWhlBrkWrm "Arbitrator and actuator status for the vehicle longitudianal acceleration comfort control. Indication of warm wheel brakes";
CM_ SG_ 98 VehDynCtrlStsForALgtCmftVehDynCtrlStsNotEna "Arbitrator and actuator status for the vehicle longitudianal acceleration comfort control. Longitudinal acceleration control for comfort not enabled";
CM_ SG_ 98 VehMtnStChks "Vehicle motion state information based on wheel speed sensors. Provides information about vehicle stand still and vehicle rolling direction. Checksum for vehicle motion state";
CM_ SG_ 98 VehMtnStCntr "Vehicle motion state information based on wheel speed sensors. Provides information about vehicle stand still and vehicle rolling direction. Counter for vehicle motion state";
CM_ SG_ 98 VehMtnStVehMtnSt "Vehicle motion state information based on wheel speed sensors. Provides information about vehicle stand still and vehicle rolling direction. Vehicle motion state";
CM_ SG_ 98 VehSpdLgtA "Vehicle speed longitudinal based on wheel speed sensors and longitudinal acceleration.";
CM_ SG_ 98 VehSpdLgtChks "Checksum";
CM_ SG_ 98 VehSpdLgtCntr "Counter";
CM_ SG_ 98 VehSpdLgtQf "Quality factor for vehicle speed as measured by wheel speed sensors and longitudinal acceleration.";
CM_ SG_ 98 WhlAFrntMax "Acceleration of the fastest wheel on the front axle.";
CM_ SG_ 98 WhlVAgrFrntLe "Unfiltered angular velocity of individual front left wheel.";
CM_ SG_ 98 WhlVAgrFrntLeQf "quality factor";
CM_ SG_ 98 WhlVAgrFrntRi "Unfiltered angular velocity of individual front right wheel.";
CM_ SG_ 98 WhlVAgrFrntRiQf "quality factor";
CM_ SG_ 98 WhlVAgrReLe "Unfiltered angular velocity of individual rear left wheel.";
CM_ SG_ 98 WhlVAgrReLeQf "quality factor";
CM_ SG_ 98 WhlVAgrReRi "Unfiltered angular velocity of individual rear right wheel.";
CM_ SG_ 98 WhlVAgrReRiQf "quality factor";
BA_DEF_ BO_ "CANFD_BRS" ENUM "0","1";
BA_DEF_ BO_ "GenMsgCycleTime" INT 0 65536;
BA_DEF_ BO_ "GenMsgDelayTime" INT 0 65536;
BA_DEF_ BO_ "GenMsgSendType" ENUM "cyclic", "spontaneous", "not-used", "not-used", "not-used", "cyclicAndSpontaneous", "not-used", "cyclicIfActive", "NoMsgSendType";
BA_DEF_ BO_ "GenMsgStartDelayTime" INT 0 65536;
BA_DEF_ BO_ "VFrameFormat" ENUM "StandardCAN","ExtendedCAN","reserved","J1939PG","reserved","reserved","reserved","reserved","reserved","reserved","reserved","reserved","reserved","reserved","StandardCAN_FD","ExtendedCAN_FD";
BA_DEF_ SG_ "GenSigSendType" ENUM "Cyclic","OnWrite","OnWriteWithRepetition","OnChange","OnChangeWithRepetition","IfActive","IfActiveWithRepetition","NoSigSendType";
BA_DEF_ SG_ "GenSigStartValue" HEX 0 80000000;
BA_DEF_ BO_ "GenMsgILSupport" ENUM "No","Yes";
BA_DEF_ BO_ "NmAsrMessage" ENUM "No","Yes";
BA_DEF_ SG_ "GenSigFuncType" ENUM "NoFunction","n/a","n/a","n/a","n/a","n/a","n/a","n/a","n/a","n/a","n/a","n/a","n/a","n/a","n/a","CHK","CNTR","n/a","n/a","n/a","CNTR_AR_01","CRC_AR_01_BOTH","CRC_AR_01_ALT","CRC_AR_01_LOW","CRC_AR_01_NIBBLE","CNTR_AR_04","CRC_AR_04A","CNTR_AR_05","CRC_AR_05";
BA_DEF_ SG_ "GenSigDataID" STRING;
BA_DEF_ SG_ "SigGroup" STRING;
BA_DEF_DEF_ "CANFD_BRS" "1";
BA_DEF_DEF_ "GenSigStartValue" 0;
BA_DEF_DEF_ "VFrameFormat" "J1939PG";
BA_DEF_DEF_ "GenSigSendType" "NoSigSendType";
BA_DEF_DEF_ "GenMsgCycleTime" 0;
BA_DEF_DEF_ "GenMsgDelayTime" 0;
BA_DEF_DEF_ "GenMsgStartDelayTime" 0;
BA_DEF_DEF_ "GenMsgSendType" "NoMsgSendType";
BA_DEF_DEF_ "GenMsgILSupport" "Yes";
BA_DEF_DEF_ "NmAsrMessage" "No";
BA_DEF_DEF_ "GenSigFuncType" "NoFunction";
BA_DEF_DEF_ "GenSigDataID" "";
BA_DEF_DEF_ "SigGroup" "";

BA_ "GenMsgCycleTime" BO_ 544 50.000;
BA_ "GenMsgSendType" BO_ 544 0;
BA_ "VFrameFormat" BO_ 544 14;

BA_ "GenMsgCycleTime" BO_ 1129 900.000;
BA_ "GenMsgSendType" BO_ 1129 0;
BA_ "VFrameFormat" BO_ 1129 14;

BA_ "GenMsgDelayTime" BO_ 1281 20.000;
BA_ "GenMsgSendType" BO_ 1281 1;
BA_ "VFrameFormat" BO_ 1281 0;

BA_ "GenMsgDelayTime" BO_ 341 50.000;
BA_ "GenMsgSendType" BO_ 341 1;
BA_ "VFrameFormat" BO_ 341 14;

BA_ "GenMsgDelayTime" BO_ 1604 5.000;
BA_ "GenMsgSendType" BO_ 1604 1;
BA_ "VFrameFormat" BO_ 1604 14;

BA_ "GenMsgDelayTime" BO_ 1585 5.000;
BA_ "GenMsgSendType" BO_ 1585 1;
BA_ "VFrameFormat" BO_ 1585 14;

BA_ "GenMsgDelayTime" BO_ 1584 5.000;
BA_ "GenMsgSendType" BO_ 1584 1;
BA_ "VFrameFormat" BO_ 1584 14;

BA_ "GenMsgDelayTime" BO_ 1616 5.000;
BA_ "GenMsgSendType" BO_ 1616 1;
BA_ "VFrameFormat" BO_ 1616 14;

BA_ "GenMsgDelayTime" BO_ 1617 5.000;
BA_ "GenMsgSendType" BO_ 1617 1;
BA_ "VFrameFormat" BO_ 1617 14;

BA_ "GenMsgDelayTime" BO_ 1537 5.000;
BA_ "GenMsgSendType" BO_ 1537 1;
BA_ "VFrameFormat" BO_ 1537 14;

BA_ "GenMsgCycleTime" BO_ 1345 500.000;
BA_ "GenMsgSendType" BO_ 1345 0;
BA_ "VFrameFormat" BO_ 1345 0;

BA_ "GenMsgDelayTime" BO_ 2031 5.000;
BA_ "GenMsgSendType" BO_ 2031 1;
BA_ "VFrameFormat" BO_ 2031 0;

BA_ "GenMsgDelayTime" BO_ 1665 5.000;
BA_ "GenMsgSendType" BO_ 1665 1;
BA_ "VFrameFormat" BO_ 1665 14;

BA_ "GenMsgCycleTime" BO_ 257 20.000;
BA_ "GenMsgSendType" BO_ 257 0;
BA_ "VFrameFormat" BO_ 257 14;

BA_ "GenMsgCycleTime" BO_ 1025 1000.000;
BA_ "GenMsgSendType" BO_ 1025 0;
BA_ "VFrameFormat" BO_ 1025 14;

BA_ "GenMsgCycleTime" BO_ 483 50.000;
BA_ "GenMsgSendType" BO_ 483 0;
BA_ "VFrameFormat" BO_ 483 14;

BA_ "GenMsgCycleTime" BO_ 816 120.000;
BA_ "GenMsgSendType" BO_ 816 0;
BA_ "VFrameFormat" BO_ 816 14;

BA_ "GenMsgCycleTime" BO_ 800 250.000;
BA_ "GenMsgSendType" BO_ 800 0;
BA_ "VFrameFormat" BO_ 800 14;

BA_ "GenMsgCycleTime" BO_ 384 30.000;
BA_ "GenMsgSendType" BO_ 384 0;
BA_ "VFrameFormat" BO_ 384 14;

BA_ "GenMsgCycleTime" BO_ 608 80.000;
BA_ "GenMsgSendType" BO_ 608 0;
BA_ "VFrameFormat" BO_ 608 14;

BA_ "GenMsgCycleTime" BO_ 997 160.000;
BA_ "GenMsgSendType" BO_ 997 0;
BA_ "VFrameFormat" BO_ 997 14;

BA_ "GenMsgCycleTime" BO_ 1040 500.000;
BA_ "GenMsgSendType" BO_ 1040 0;
BA_ "VFrameFormat" BO_ 1040 14;

BA_ "GenMsgCycleTime" BO_ 576 70.000;
BA_ "GenMsgSendType" BO_ 576 0;
BA_ "VFrameFormat" BO_ 576 14;

BA_ "GenMsgCycleTime" BO_ 949 320.000;
BA_ "GenMsgSendType" BO_ 949 0;
BA_ "VFrameFormat" BO_ 949 14;

BA_ "GenMsgCycleTime" BO_ 805 200.000;
BA_ "GenMsgSendType" BO_ 805 0;
BA_ "VFrameFormat" BO_ 805 14;

BA_ "GenMsgCycleTime" BO_ 704 100.000;
BA_ "GenMsgSendType" BO_ 704 0;
BA_ "VFrameFormat" BO_ 704 14;

BA_ "GenMsgCycleTime" BO_ 402 30.000;
BA_ "GenMsgSendType" BO_ 402 0;
BA_ "VFrameFormat" BO_ 402 14;

BA_ "GenMsgCycleTime" BO_ 98 10.000;
BA_ "GenMsgSendType" BO_ 98 0;
BA_ "VFrameFormat" BO_ 98 14;
BA_ "GenMsgILSupport" BO_ 1281 0;
BA_ "NmAsrMessage" BO_ 1281 1;
BA_ "GenSigSendType" SG_ 1025 ALgtStdFromWhlSpdALgtStdFromWhlSpd 0;
BA_ "GenSigDataID" SG_ 1025 ALgtStdFromWhlSpdChks "0x34";
BA_ "GenSigFuncType" SG_ 1025 ALgtStdFromWhlSpdChks 15;
BA_ "GenSigSendType" SG_ 1025 ALgtStdFromWhlSpdChks 0;
BA_ "GenSigFuncType" SG_ 1025 ALgtStdFromWhlSpdCntr 16;
BA_ "GenSigSendType" SG_ 1025 ALgtStdFromWhlSpdCntr 0;
BA_ "GenSigSendType" SG_ 1025 ALgtStdFromWhlSpdQf 0;
BA_ "GenSigStartValue" SG_ 1025 ALgtStdFromWhlSpdQf 1;
BA_ "GenSigSendType" SG_ 816 AbsClrRdyReq 0;
BA_ "GenSigDataID" SG_ 257 AbsCtrlActvChks "0xD06";
BA_ "GenSigFuncType" SG_ 257 AbsCtrlActvChks 15;
BA_ "GenSigSendType" SG_ 257 AbsCtrlActvChks 0;
BA_ "GenSigFuncType" SG_ 257 AbsCtrlActvCntr 16;
BA_ "GenSigSendType" SG_ 257 AbsCtrlActvCntr 0;
BA_ "GenSigSendType" SG_ 257 AbsCtrlActvCtrlSts1 0;
BA_ "GenSigSendType" SG_ 1025 AbsCtrlActvForWhlFrntLe 0;
BA_ "GenSigSendType" SG_ 1025 AbsCtrlActvForWhlFrntRi 0;
BA_ "GenSigSendType" SG_ 1025 AbsCtrlActvForWhlReLe 0;
BA_ "GenSigSendType" SG_ 1025 AbsCtrlActvForWhlReRi 0;
BA_ "GenSigSendType" SG_ 800 AbsErrIndcnReq 0;
BA_ "GenSigSendType" SG_ 483 AbsSts 0;
BA_ "GenSigSendType" SG_ 384 AsyALgtActvAftLim 0;
BA_ "GenSigSendType" SG_ 257 AsyALgtCtrlModCfmdAsyALgtCtrlMod1 0;
BA_ "GenSigDataID" SG_ 257 AsyALgtCtrlModCfmdChks "0x416";
BA_ "GenSigFuncType" SG_ 257 AsyALgtCtrlModCfmdChks 15;
BA_ "GenSigSendType" SG_ 257 AsyALgtCtrlModCfmdChks 0;
BA_ "GenSigFuncType" SG_ 257 AsyALgtCtrlModCfmdCntr 16;
BA_ "GenSigSendType" SG_ 257 AsyALgtCtrlModCfmdCntr 0;
BA_ "GenSigSendType" SG_ 483 AsyActrActvForLgtCtrl 0;
BA_ "GenSigDataID" SG_ 402 AsyLatCtrlModReqGroupCfmdChks "0x424";
BA_ "GenSigFuncType" SG_ 402 AsyLatCtrlModReqGroupCfmdChks 15;
BA_ "GenSigSendType" SG_ 402 AsyLatCtrlModReqGroupCfmdChks 0;
BA_ "GenSigFuncType" SG_ 402 AsyLatCtrlModReqGroupCfmdCntr 16;
BA_ "GenSigSendType" SG_ 402 AsyLatCtrlModReqGroupCfmdCntr 0;
BA_ "GenSigSendType" SG_ 402 AsyLatCtrlModReqGroupCfmdLatCtrlMod 0;
BA_ "GenSigSendType" SG_ 483 AsySftyDecelEnadByVehDyn 0;
BA_ "GenSigSendType" SG_ 483 AsySftyEnaDecelAckd 0;
BA_ "GenSigSendType" SG_ 257 AutHldAvlSt 0;
BA_ "GenSigSendType" SG_ 949 AutHldSoftSwtEnaSts 0;
BA_ "GenSigSendType" SG_ 608 AutoShowModBCEna 0;
BA_ "GenSigSendType" SG_ 257 AxleSlipRelAct 0;
BA_ "GenSigSendType" SG_ 997 BkpOfDstTrvldFromBrk 0;
BA_ "GenSigSendType" SG_ 949 BrkAndAbsWarnIndcnReqAbsWarnIndcnReq 0;
BA_ "GenSigStartValue" SG_ 949 BrkAndAbsWarnIndcnReqAbsWarnIndcnReq 3;
BA_ "GenSigSendType" SG_ 949 BrkAndAbsWarnIndcnReqBrkWarnIndcnReq 0;
BA_ "GenSigStartValue" SG_ 949 BrkAndAbsWarnIndcnReqBrkWarnIndcnReq 1;
BA_ "GenSigDataID" SG_ 949 BrkAndAbsWarnIndcnReqChks "0x65";
BA_ "GenSigFuncType" SG_ 949 BrkAndAbsWarnIndcnReqChks 15;
BA_ "GenSigSendType" SG_ 949 BrkAndAbsWarnIndcnReqChks 0;
BA_ "GenSigFuncType" SG_ 949 BrkAndAbsWarnIndcnReqCntr 16;
BA_ "GenSigSendType" SG_ 949 BrkAndAbsWarnIndcnReqCntr 0;
BA_ "GenSigSendType" SG_ 1040 BrkBoostClrRdyReq 0;
BA_ "GenSigSendType" SG_ 949 BrkBoostErrIndcnReq 0;
BA_ "GenSigSendType" SG_ 949 BrkByWireWarnIndcn 0;
BA_ "GenSigStartValue" SG_ 949 BrkByWireWarnIndcn 1;
BA_ "GenSigSendType" SG_ 949 BrkFldLvl 0;
BA_ "GenSigSendType" SG_ 257 BrkFricTqAtWhlActBrkFricTqAtWhlFrntLeAct 0;
BA_ "GenSigSendType" SG_ 257 BrkFricTqAtWhlActBrkFricTqAtWhlFrntRiAct 0;
BA_ "GenSigSendType" SG_ 257 BrkFricTqAtWhlActBrkFricTqAtWhlReLeAct 0;
BA_ "GenSigSendType" SG_ 257 BrkFricTqAtWhlActBrkFricTqAtWhlReRiAct 0;
BA_ "GenSigSendType" SG_ 384 BrkFricTqTotAtWhlsActBrkFricTqTotAtWhlsAct 0;
BA_ "GenSigDataID" SG_ 384 BrkFricTqTotAtWhlsActChks "0x7B";
BA_ "GenSigFuncType" SG_ 384 BrkFricTqTotAtWhlsActChks 15;
BA_ "GenSigSendType" SG_ 384 BrkFricTqTotAtWhlsActChks 0;
BA_ "GenSigFuncType" SG_ 384 BrkFricTqTotAtWhlsActCntr 16;
BA_ "GenSigSendType" SG_ 384 BrkFricTqTotAtWhlsActCntr 0;
BA_ "GenSigDataID" SG_ 402 BrkLiOnReqChks "0x49";
BA_ "GenSigFuncType" SG_ 402 BrkLiOnReqChks 15;
BA_ "GenSigSendType" SG_ 402 BrkLiOnReqChks 0;
BA_ "GenSigFuncType" SG_ 402 BrkLiOnReqCntr 16;
BA_ "GenSigSendType" SG_ 402 BrkLiOnReqCntr 0;
BA_ "GenSigSendType" SG_ 402 BrkLiOnReqSts 0;
BA_ "GenSigSendType" SG_ 949 BrkMsgForHybWarnReq 0;
BA_ "GenSigSendType" SG_ 949 BrkMsgForLoVacReqd 0;
BA_ "GenSigSendType" SG_ 949 BrkMsgWarnReq 0;
BA_ "GenSigSendType" SG_ 949 BrkMsgWarnReqForHmi 0;
BA_ "GenSigSendType" SG_ 1025 BrkPAtWhlFL 0;
BA_ "GenSigSendType" SG_ 1025 BrkPAtWhlFR 0;
BA_ "GenSigSendType" SG_ 1025 BrkPAtWhlRL 0;
BA_ "GenSigSendType" SG_ 1025 BrkPAtWhlRR 0;
BA_ "GenSigSendType" SG_ 384 BrkPedlPsdBrkPedlNotPsdSafe 0;
BA_ "GenSigSendType" SG_ 384 BrkPedlPsdBrkPedlPsd 0;
BA_ "GenSigDataID" SG_ 384 BrkPedlPsdChks "0x38";
BA_ "GenSigFuncType" SG_ 384 BrkPedlPsdChks 15;
BA_ "GenSigSendType" SG_ 384 BrkPedlPsdChks 0;
BA_ "GenSigFuncType" SG_ 384 BrkPedlPsdCntr 16;
BA_ "GenSigSendType" SG_ 384 BrkPedlPsdCntr 0;
BA_ "GenSigSendType" SG_ 384 BrkPedlPsdQf 0;
BA_ "GenSigSendType" SG_ 384 BrkPedlTrvlAct 0;
BA_ "GenSigStartValue" SG_ 384 BrkPedlTrvlAct 500;
BA_ "GenSigDataID" SG_ 384 BrkPedlTrvlChks "0xB3";
BA_ "GenSigFuncType" SG_ 384 BrkPedlTrvlChks 15;
BA_ "GenSigSendType" SG_ 384 BrkPedlTrvlChks 0;
BA_ "GenSigStartValue" SG_ 384 BrkPedlTrvlChks 255;
BA_ "GenSigFuncType" SG_ 384 BrkPedlTrvlCntr 16;
BA_ "GenSigSendType" SG_ 384 BrkPedlTrvlCntr 0;
BA_ "GenSigSendType" SG_ 384 BrkPedlTrvlQf 0;
BA_ "GenSigStartValue" SG_ 384 BrkPedlTrvlQf 1;
BA_ "GenSigSendType" SG_ 384 BrkPedlTrvlSt 0;
BA_ "GenSigSendType" SG_ 384 BrkPedlTrvlStQf 0;
BA_ "GenSigStartValue" SG_ 384 BrkPedlTrvlStQf 1;
BA_ "GenSigSendType" SG_ 384 BrkPedlTrvlTar 0;
BA_ "GenSigStartValue" SG_ 384 BrkPedlTrvlTar 500;
BA_ "GenSigSendType" SG_ 483 BrkPedlrRatPerc 0;
BA_ "GenSigSendType" SG_ 483 BrkPedlrRatQf 0;
BA_ "GenSigSendType" SG_ 949 BrkRelsWarnReq 0;
BA_ "GenSigSendType" SG_ 384 BrkSysCylPMstAct 0;
BA_ "GenSigStartValue" SG_ 384 BrkSysCylPMstAct 100;
BA_ "GenSigSendType" SG_ 384 BrkSysCylPMstActQf 0;
BA_ "GenSigStartValue" SG_ 384 BrkSysCylPMstActQf 1;
BA_ "GenSigDataID" SG_ 384 BrkSysCylPMstChks "0xB7";
BA_ "GenSigFuncType" SG_ 384 BrkSysCylPMstChks 15;
BA_ "GenSigSendType" SG_ 384 BrkSysCylPMstChks 0;
BA_ "GenSigFuncType" SG_ 384 BrkSysCylPMstCntr 16;
BA_ "GenSigSendType" SG_ 384 BrkSysCylPMstCntr 0;
BA_ "GenSigSendType" SG_ 384 BrkSysCylPMstTar 0;
BA_ "GenSigSendType" SG_ 384 BrkSysCylPMstVirt 0;
BA_ "GenSigSendType" SG_ 384 BrkSysCylPMstVirtQf 0;
BA_ "GenSigStartValue" SG_ 384 BrkSysCylPMstVirtQf 1;
BA_ "GenSigSendType" SG_ 576 BrkSysStsADL3BrkFallBck 0;
BA_ "GenSigSendType" SG_ 576 BrkSysStsBrkDegradation 0;
BA_ "GenSigSendType" SG_ 576 BrkSysStsBrkSysCapability 0;
BA_ "GenSigSendType" SG_ 576 BrkSysStsBrkSysModCfmd 0;
BA_ "GenSigDataID" SG_ 576 BrkSysStsChks "0x447";
BA_ "GenSigFuncType" SG_ 576 BrkSysStsChks 15;
BA_ "GenSigSendType" SG_ 576 BrkSysStsChks 0;
BA_ "GenSigFuncType" SG_ 576 BrkSysStsCntr 16;
BA_ "GenSigSendType" SG_ 576 BrkSysStsCntr 0;
BA_ "GenSigSendType" SG_ 949 BrkSysWarnIndcnReq 0;
BA_ "GenSigSendType" SG_ 257 BrkTqAtWhlsReq 0;
BA_ "GenSigDataID" SG_ 257 BrkTqChks "0x4B1";
BA_ "GenSigFuncType" SG_ 257 BrkTqChks 15;
BA_ "GenSigSendType" SG_ 257 BrkTqChks 0;
BA_ "GenSigFuncType" SG_ 257 BrkTqCntr 16;
BA_ "GenSigSendType" SG_ 257 BrkTqCntr 0;
BA_ "GenSigSendType" SG_ 257 BrkTqQf 0;
BA_ "GenSigSendType" SG_ 257 BrkTqRgnAtAxleReReq 0;
BA_ "GenSigSendType" SG_ 257 BrkTqSts 0;
BA_ "GenSigSendType" SG_ 257 BrkTqTotReqForPt 0;
BA_ "GenSigSendType" SG_ 816 BrkTracCtrlActvForWhlFrntLe 0;
BA_ "GenSigSendType" SG_ 816 BrkTracCtrlActvForWhlFrntRi 0;
BA_ "GenSigSendType" SG_ 816 BrkTracCtrlActvForWhlReLe 0;
BA_ "GenSigSendType" SG_ 816 BrkTracCtrlActvForWhlReRi 0;
BA_ "GenSigSendType" SG_ 949 CstCtrlActvCstCtrlEab 0;
BA_ "GenSigSendType" SG_ 949 CstCtrlActvCtrlSts1 0;
BA_ "GenSigSendType" SG_ 949 DispMsgByVehHld 0;
BA_ "GenSigStartValue" SG_ 949 DispMsgByVehHld 1;
BA_ "GenSigDataID" SG_ 949 DrvModEscOffChks "0x45F";
BA_ "GenSigFuncType" SG_ 949 DrvModEscOffChks 15;
BA_ "GenSigSendType" SG_ 949 DrvModEscOffChks 0;
BA_ "GenSigFuncType" SG_ 949 DrvModEscOffCntr 16;
BA_ "GenSigSendType" SG_ 949 DrvModEscOffCntr 0;
BA_ "GenSigSendType" SG_ 949 DrvModEscOffDrvModEscOff 0;
BA_ "GenSigDataID" SG_ 257 DrvrBrkTqAtWhlsReqdChks "0x7A";
BA_ "GenSigFuncType" SG_ 257 DrvrBrkTqAtWhlsReqdChks 15;
BA_ "GenSigSendType" SG_ 257 DrvrBrkTqAtWhlsReqdChks 0;
BA_ "GenSigFuncType" SG_ 257 DrvrBrkTqAtWhlsReqdCntr 16;
BA_ "GenSigSendType" SG_ 257 DrvrBrkTqAtWhlsReqdCntr 0;
BA_ "GenSigSendType" SG_ 257 DrvrBrkTqAtWhlsReqdDrvrBrkTqAtWhlsReqd 0;
BA_ "GenSigSendType" SG_ 257 DrvrBrkTqAtWhlsReqdQf 0;
BA_ "GenSigStartValue" SG_ 257 DrvrBrkTqAtWhlsReqdQf 1;
BA_ "GenSigDataID" SG_ 384 DrvrDecelReqChks "0x1B";
BA_ "GenSigFuncType" SG_ 384 DrvrDecelReqChks 15;
BA_ "GenSigSendType" SG_ 384 DrvrDecelReqChks 0;
BA_ "GenSigFuncType" SG_ 384 DrvrDecelReqCntr 16;
BA_ "GenSigSendType" SG_ 384 DrvrDecelReqCntr 0;
BA_ "GenSigSendType" SG_ 384 DrvrDecelReqFloat8 0;
BA_ "GenSigSendType" SG_ 997 DstTrvldVldFromBrkBkp 0;
BA_ "GenSigSendType" SG_ 997 EPBLockChkChk 0;
BA_ "GenSigSendType" SG_ 997 EPBLockChkData0 0;
BA_ "GenSigSendType" SG_ 997 EPBLockChkData1 0;
BA_ "GenSigSendType" SG_ 997 EPBLockChkData2 0;
BA_ "GenSigSendType" SG_ 997 EPBLockChkData3 0;
BA_ "GenSigSendType" SG_ 997 EPBLockChkData4 0;
BA_ "GenSigSendType" SG_ 997 EPBLockChkData5 0;
BA_ "GenSigSendType" SG_ 997 EPBLockChkData6 0;
BA_ "GenSigSendType" SG_ 997 EPBLockSts 0;
BA_ "GenSigDataID" SG_ 997 EmgyBrkLiReqChks "0x1AE0";
BA_ "GenSigFuncType" SG_ 997 EmgyBrkLiReqChks 15;
BA_ "GenSigSendType" SG_ 997 EmgyBrkLiReqChks 0;
BA_ "GenSigFuncType" SG_ 997 EmgyBrkLiReqCntr 16;
BA_ "GenSigSendType" SG_ 997 EmgyBrkLiReqCntr 0;
BA_ "GenSigSendType" SG_ 997 EmgyBrkLiReqEmgyBrk 0;
BA_ "GenSigSendType" SG_ 384 EngRunngReqByBrk 0;
BA_ "GenSigSendType" SG_ 384 EpbActrStPrim 0;
BA_ "GenSigStartValue" SG_ 384 EpbActrStPrim 4;
BA_ "GenSigSendType" SG_ 949 EpbApplyEna 0;
BA_ "GenSigSendType" SG_ 608 EpbDrvrDisp 0;
BA_ "GenSigDataID" SG_ 816 EpbLampReqChks "0x55";
BA_ "GenSigFuncType" SG_ 816 EpbLampReqChks 15;
BA_ "GenSigSendType" SG_ 816 EpbLampReqChks 0;
BA_ "GenSigFuncType" SG_ 816 EpbLampReqCntr 16;
BA_ "GenSigSendType" SG_ 816 EpbLampReqCntr 0;
BA_ "GenSigSendType" SG_ 816 EpbLampReqEpbLampReq 0;
BA_ "GenSigSendType" SG_ 949 EpbRelsEna 0;
BA_ "GenSigDataID" SG_ 384 EpbStsChks "0x84";
BA_ "GenSigFuncType" SG_ 384 EpbStsChks 15;
BA_ "GenSigSendType" SG_ 384 EpbStsChks 0;
BA_ "GenSigFuncType" SG_ 384 EpbStsCntr 16;
BA_ "GenSigSendType" SG_ 384 EpbStsCntr 0;
BA_ "GenSigSendType" SG_ 384 EpbStsEpbSts 0;
BA_ "GenSigSendType" SG_ 483 EscActvCtrlIndcdToDrvr 0;
BA_ "GenSigSendType" SG_ 384 EscCtrlIndcn 0;
BA_ "GenSigStartValue" SG_ 384 EscCtrlIndcn 1;
BA_ "GenSigSendType" SG_ 384 EscGearShiftInhbReq 0;
BA_ "GenSigDataID" SG_ 384 EscStChks "0x7F";
BA_ "GenSigFuncType" SG_ 384 EscStChks 15;
BA_ "GenSigSendType" SG_ 384 EscStChks 0;
BA_ "GenSigFuncType" SG_ 384 EscStCntr 16;
BA_ "GenSigSendType" SG_ 384 EscStCntr 0;
BA_ "GenSigSendType" SG_ 384 EscStEscSt 0;
BA_ "GenSigStartValue" SG_ 384 EscStEscSt 1;
BA_ "GenSigDataID" SG_ 257 EscVariantToDmcChks "0x19A4";
BA_ "GenSigFuncType" SG_ 257 EscVariantToDmcChks 15;
BA_ "GenSigSendType" SG_ 257 EscVariantToDmcChks 0;
BA_ "GenSigFuncType" SG_ 257 EscVariantToDmcCntr 16;
BA_ "GenSigSendType" SG_ 257 EscVariantToDmcCntr 0;
BA_ "GenSigSendType" SG_ 257 EscVariantToDmcEscVariantToDmc 0;
BA_ "GenSigDataID" SG_ 576 EscWarnIndcnReqChks "0x66";
BA_ "GenSigFuncType" SG_ 576 EscWarnIndcnReqChks 15;
BA_ "GenSigSendType" SG_ 576 EscWarnIndcnReqChks 0;
BA_ "GenSigFuncType" SG_ 576 EscWarnIndcnReqCntr 16;
BA_ "GenSigSendType" SG_ 576 EscWarnIndcnReqCntr 0;
BA_ "GenSigSendType" SG_ 576 EscWarnIndcnReqEscWarnIndcnReq 0;
BA_ "GenSigStartValue" SG_ 576 EscWarnIndcnReqEscWarnIndcnReq 3;
BA_ "GenSigSendType" SG_ 257 FricEstimnFromVehDynFricEstimnFromVehDyn 0;
BA_ "GenSigSendType" SG_ 257 FricEstimnFromVehDynQly 0;
BA_ "GenSigStartValue" SG_ 257 FricEstimnFromVehDynQly 1;
BA_ "GenSigStartValue" SG_ 1129 FrntRdrStsRdrStsSftyFlt 1;
BA_ "GenSigStartValue" SG_ 1129 FrntRdrStsRdrStsWhlSpdCmpFac 16;
BA_ "GenSigSendType" SG_ 483 HsaSt 0;
BA_ "GenSigStartValue" SG_ 483 HsaSt 1;
BA_ "GenSigSendType" SG_ 608 ImobBrkNrSerl0 0;
BA_ "GenSigSendType" SG_ 608 ImobBrkNrSerl1 0;
BA_ "GenSigSendType" SG_ 608 ImobBrkNrSerl2 0;
BA_ "GenSigSendType" SG_ 608 ImobBrkNrSerl3 0;
BA_ "GenSigSendType" SG_ 608 ImobBrkNrSerl4 0;
BA_ "GenSigSendType" SG_ 608 ImobBrkNrSerl5 0;
BA_ "GenSigSendType" SG_ 997 IndcnToDrvrPostImpctCtrl 0;
BA_ "GenSigSendType" SG_ 483 InhbOfAsySftyDecelByVehDyn 0;
BA_ "GenSigSendType" SG_ 576 LampReqByVehHld 0;
BA_ "GenSigDataID" SG_ 257 LatCtrlReqSafeChks "0x30";
BA_ "GenSigFuncType" SG_ 257 LatCtrlReqSafeChks 15;
BA_ "GenSigSendType" SG_ 257 LatCtrlReqSafeChks 0;
BA_ "GenSigFuncType" SG_ 257 LatCtrlReqSafeCntr 16;
BA_ "GenSigSendType" SG_ 257 LatCtrlReqSafeCntr 0;
BA_ "GenSigSendType" SG_ 257 LatCtrlReqSafeLatCtrlModReq 0;
BA_ "GenSigSendType" SG_ 257 LatCtrlReqSafeSteerTqReq 0;
BA_ "GenSigSendType" SG_ 257 LatCtrlReqSafeSteerWhlHptcWarnReq 0;
BA_ "GenSigDataID" SG_ 257 LgtCtrlModReqSafeChks "0x422";
BA_ "GenSigFuncType" SG_ 257 LgtCtrlModReqSafeChks 15;
BA_ "GenSigSendType" SG_ 257 LgtCtrlModReqSafeChks 0;
BA_ "GenSigFuncType" SG_ 257 LgtCtrlModReqSafeCntr 16;
BA_ "GenSigSendType" SG_ 257 LgtCtrlModReqSafeCntr 0;
BA_ "GenSigSendType" SG_ 257 LgtCtrlModReqSafeLgtCtrlModReqSafe 0;
BA_ "GenSigSendType" SG_ 257 LgtCtrlModReqSafeLgtFctFailr 0;
BA_ "GenSigDataID" SG_ 483 LimForDecelChks "0x8B";
BA_ "GenSigFuncType" SG_ 483 LimForDecelChks 15;
BA_ "GenSigSendType" SG_ 483 LimForDecelChks 0;
BA_ "GenSigFuncType" SG_ 483 LimForDecelCntr 16;
BA_ "GenSigSendType" SG_ 483 LimForDecelCntr 0;
BA_ "GenSigSendType" SG_ 483 LimForDecelNotExcd 0;
BA_ "GenSigStartValue" SG_ 483 LimForDecelNotExcd 1;
BA_ "GenSigDataID" SG_ 384 LimForJerkPosNotExcdChks "0x73";
BA_ "GenSigFuncType" SG_ 384 LimForJerkPosNotExcdChks 15;
BA_ "GenSigSendType" SG_ 384 LimForJerkPosNotExcdChks 0;
BA_ "GenSigFuncType" SG_ 384 LimForJerkPosNotExcdCntr 16;
BA_ "GenSigSendType" SG_ 384 LimForJerkPosNotExcdCntr 0;
BA_ "GenSigSendType" SG_ 384 LimForJerkPosNotExcdLimForJerkPosNotExcd 0;
BA_ "GenSigStartValue" SG_ 384 LimForJerkPosNotExcdLimForJerkPosNotExcd 1;
BA_ "GenSigSendType" SG_ 483 MsgReqByHillDwnCtrl 0;
BA_ "GenSigSendType" SG_ 1025 PitchAgGlbQf 0;
BA_ "GenSigStartValue" SG_ 1025 PitchAgGlbQf 1;
BA_ "GenSigSendType" SG_ 1025 PitchAgGlbVal 0;
BA_ "GenSigSendType" SG_ 800 PostImpctBrkgRdy 0;
BA_ "GenSigDataID" SG_ 402 PrkLatLgtFailrChks "0x421";
BA_ "GenSigFuncType" SG_ 402 PrkLatLgtFailrChks 15;
BA_ "GenSigSendType" SG_ 402 PrkLatLgtFailrChks 0;
BA_ "GenSigFuncType" SG_ 402 PrkLatLgtFailrCntr 16;
BA_ "GenSigSendType" SG_ 402 PrkLatLgtFailrCntr 0;
BA_ "GenSigSendType" SG_ 402 PrkLatLgtFailrPrkLatLgtFailr 0;
BA_ "GenSigSendType" SG_ 257 PrpsnTqForBrkRels 0;
BA_ "GenSigDataID" SG_ 384 PtTqAtAxleAddReqChks "0x6C";
BA_ "GenSigFuncType" SG_ 384 PtTqAtAxleAddReqChks 15;
BA_ "GenSigSendType" SG_ 384 PtTqAtAxleAddReqChks 0;
BA_ "GenSigFuncType" SG_ 384 PtTqAtAxleAddReqCntr 16;
BA_ "GenSigSendType" SG_ 384 PtTqAtAxleAddReqCntr 0;
BA_ "GenSigSendType" SG_ 384 PtTqAtAxleAddReqPtTqAtAxleAddFrntReq 0;
BA_ "GenSigSendType" SG_ 384 PtTqAtAxleAddReqPtTqAtAxleAddReReq 0;
BA_ "GenSigDataID" SG_ 257 PtTqAtAxleMinReqChks "0x454";
BA_ "GenSigFuncType" SG_ 257 PtTqAtAxleMinReqChks 15;
BA_ "GenSigSendType" SG_ 257 PtTqAtAxleMinReqChks 0;
BA_ "GenSigFuncType" SG_ 257 PtTqAtAxleMinReqCntr 16;
BA_ "GenSigSendType" SG_ 257 PtTqAtAxleMinReqCntr 0;
BA_ "GenSigSendType" SG_ 257 PtTqAtAxleMinReqPtTqAtAxleFrntReq 0;
BA_ "GenSigStartValue" SG_ 257 PtTqAtAxleMinReqPtTqAtAxleFrntReq -20000;
BA_ "GenSigSendType" SG_ 257 PtTqAtAxleMinReqPtTqAtAxleReReq 0;
BA_ "GenSigStartValue" SG_ 257 PtTqAtAxleMinReqPtTqAtAxleReReq -20000;
BA_ "GenSigSendType" SG_ 257 PtTqAtAxleReMinSlowReq 0;
BA_ "GenSigStartValue" SG_ 257 PtTqAtAxleReMinSlowReq -20000;
BA_ "GenSigDataID" SG_ 384 PtTqChks "0xA2";
BA_ "GenSigFuncType" SG_ 384 PtTqChks 15;
BA_ "GenSigSendType" SG_ 384 PtTqChks 0;
BA_ "GenSigFuncType" SG_ 384 PtTqCntr 16;
BA_ "GenSigSendType" SG_ 384 PtTqCntr 0;
BA_ "GenSigDataID" SG_ 384 PtTqHardMaxChks "0x95";
BA_ "GenSigFuncType" SG_ 384 PtTqHardMaxChks 15;
BA_ "GenSigSendType" SG_ 384 PtTqHardMaxChks 0;
BA_ "GenSigFuncType" SG_ 384 PtTqHardMaxCntr 16;
BA_ "GenSigSendType" SG_ 384 PtTqHardMaxCntr 0;
BA_ "GenSigSendType" SG_ 384 PtTqHardMaxGrdtNeg 0;
BA_ "GenSigStartValue" SG_ 384 PtTqHardMaxGrdtNeg 8191;
BA_ "GenSigSendType" SG_ 384 PtTqHardMaxGrdtPos 0;
BA_ "GenSigStartValue" SG_ 384 PtTqHardMaxGrdtPos 8191;
BA_ "GenSigSendType" SG_ 384 PtTqHardMaxReq 0;
BA_ "GenSigStartValue" SG_ 384 PtTqHardMaxReq 4095;
BA_ "GenSigSendType" SG_ 384 PtTqMinReq 0;
BA_ "GenSigDataID" SG_ 384 PtTqSetSafeChks "0x374";
BA_ "GenSigFuncType" SG_ 384 PtTqSetSafeChks 15;
BA_ "GenSigSendType" SG_ 384 PtTqSetSafeChks 0;
BA_ "GenSigFuncType" SG_ 384 PtTqSetSafeCntr 16;
BA_ "GenSigSendType" SG_ 384 PtTqSetSafeCntr 0;
BA_ "GenSigSendType" SG_ 384 PtTqSetSafeGrdtNeg 0;
BA_ "GenSigSendType" SG_ 384 PtTqSetSafeGrdtPos 0;
BA_ "GenSigSendType" SG_ 384 PtTqSetSafeReq 0;
BA_ "GenSigSendType" SG_ 257 PtTqSoftMaxGenn2Allwd 0;
BA_ "GenSigDataID" SG_ 257 PtTqSoftMaxGenn2AllwdChks "0xDB";
BA_ "GenSigFuncType" SG_ 257 PtTqSoftMaxGenn2AllwdChks 15;
BA_ "GenSigSendType" SG_ 257 PtTqSoftMaxGenn2AllwdChks 0;
BA_ "GenSigFuncType" SG_ 257 PtTqSoftMaxGenn2AllwdCntr 16;
BA_ "GenSigSendType" SG_ 257 PtTqSoftMaxGenn2AllwdCntr 0;
BA_ "GenSigSendType" SG_ 384 PtTqSoftMaxReq 0;
BA_ "GenSigSendType" SG_ 483 RctaBrkActvd 0;
BA_ "GenSigSendType" SG_ 483 RcwmBrkActvd 0;
BA_ "GenSigSendType" SG_ 1129 ReSideRdrLeStsRdrNrDetn 0;
BA_ "GenSigSendType" SG_ 1129 ReSideRdrLeStsRdrNrObj 0;
BA_ "GenSigSendType" SG_ 1129 ReSideRdrLeStsRdrStsBlkd0bin 0;
BA_ "GenSigSendType" SG_ 1129 ReSideRdrLeStsRdrStsBlkdConf 0;
BA_ "GenSigDataID" SG_ 1129 ReSideRdrLeStsRdrStsChks "0xA3F";
BA_ "GenSigFuncType" SG_ 1129 ReSideRdrLeStsRdrStsChks 15;
BA_ "GenSigSendType" SG_ 1129 ReSideRdrLeStsRdrStsChks 0;
BA_ "GenSigFuncType" SG_ 1129 ReSideRdrLeStsRdrStsCntr 16;
BA_ "GenSigSendType" SG_ 1129 ReSideRdrLeStsRdrStsCntr 0;
BA_ "GenSigSendType" SG_ 1129 ReSideRdrLeStsRdrStsDstbc 0;
BA_ "GenSigSendType" SG_ 1129 ReSideRdrLeStsRdrStsEna 0;
BA_ "GenSigSendType" SG_ 1129 ReSideRdrLeStsRdrStsFaulty 0;
BA_ "GenSigSendType" SG_ 1129 ReSideRdrLeStsRdrStsIfVersMajor 0;
BA_ "GenSigSendType" SG_ 1129 ReSideRdrLeStsRdrStsIfVersMinor 0;
BA_ "GenSigSendType" SG_ 1129 ReSideRdrLeStsRdrStsLatency 0;
BA_ "GenSigStartValue" SG_ 1129 ReSideRdrLeStsRdrStsLatency 65535;
BA_ "GenSigSendType" SG_ 1129 ReSideRdrLeStsRdrStsMisAlign 0;
BA_ "GenSigSendType" SG_ 1129 ReSideRdrLeStsRdrStsMissCom 0;
BA_ "GenSigSendType" SG_ 1129 ReSideRdrLeStsRdrStsSftyFlt 0;
BA_ "GenSigStartValue" SG_ 1129 ReSideRdrLeStsRdrStsSftyFlt 1;
BA_ "GenSigSendType" SG_ 1129 ReSideRdrLeStsRdrStsTiStamp 0;
BA_ "GenSigSendType" SG_ 1129 ReSideRdrLeStsRdrStsTiStampStsGlbTiBas 0;
BA_ "GenSigSendType" SG_ 1129 ReSideRdrLeStsRdrStsTiStampStsSyncToGatewy 0;
BA_ "GenSigSendType" SG_ 1129 ReSideRdrLeStsRdrStsTiStampStsTiLeap 0;
BA_ "GenSigSendType" SG_ 1129 ReSideRdrLeStsRdrStsTiStampStsTiOut 0;
BA_ "GenSigSendType" SG_ 1129 ReSideRdrLeStsRdrStsWhlSpdCmpFac 0;
BA_ "GenSigStartValue" SG_ 1129 ReSideRdrLeStsRdrStsWhlSpdCmpFac 16;
BA_ "GenSigSendType" SG_ 1129 ReSideRdrRiStsRdrNrDetn 0;
BA_ "GenSigSendType" SG_ 1129 ReSideRdrRiStsRdrNrObj 0;
BA_ "GenSigSendType" SG_ 1129 ReSideRdrRiStsRdrStsBlkd0bin 0;
BA_ "GenSigSendType" SG_ 1129 ReSideRdrRiStsRdrStsBlkdConf 0;
BA_ "GenSigDataID" SG_ 1129 ReSideRdrRiStsRdrStsChks "0xAEE";
BA_ "GenSigFuncType" SG_ 1129 ReSideRdrRiStsRdrStsChks 15;
BA_ "GenSigSendType" SG_ 1129 ReSideRdrRiStsRdrStsChks 0;
BA_ "GenSigFuncType" SG_ 1129 ReSideRdrRiStsRdrStsCntr 16;
BA_ "GenSigSendType" SG_ 1129 ReSideRdrRiStsRdrStsCntr 0;
BA_ "GenSigSendType" SG_ 1129 ReSideRdrRiStsRdrStsDstbc 0;
BA_ "GenSigSendType" SG_ 1129 ReSideRdrRiStsRdrStsEna 0;
BA_ "GenSigSendType" SG_ 1129 ReSideRdrRiStsRdrStsFaulty 0;
BA_ "GenSigSendType" SG_ 1129 ReSideRdrRiStsRdrStsIfVersMajor 0;
BA_ "GenSigSendType" SG_ 1129 ReSideRdrRiStsRdrStsIfVersMinor 0;
BA_ "GenSigSendType" SG_ 1129 ReSideRdrRiStsRdrStsLatency 0;
BA_ "GenSigStartValue" SG_ 1129 ReSideRdrRiStsRdrStsLatency 65535;
BA_ "GenSigSendType" SG_ 1129 ReSideRdrRiStsRdrStsMisAlign 0;
BA_ "GenSigSendType" SG_ 1129 ReSideRdrRiStsRdrStsMissCom 0;
BA_ "GenSigSendType" SG_ 1129 ReSideRdrRiStsRdrStsSftyFlt 0;
BA_ "GenSigStartValue" SG_ 1129 ReSideRdrRiStsRdrStsSftyFlt 1;
BA_ "GenSigSendType" SG_ 1129 ReSideRdrRiStsRdrStsTiStamp 0;
BA_ "GenSigSendType" SG_ 1129 ReSideRdrRiStsRdrStsTiStampStsGlbTiBas 0;
BA_ "GenSigSendType" SG_ 1129 ReSideRdrRiStsRdrStsTiStampStsSyncToGatewy 0;
BA_ "GenSigSendType" SG_ 1129 ReSideRdrRiStsRdrStsTiStampStsTiLeap 0;
BA_ "GenSigSendType" SG_ 1129 ReSideRdrRiStsRdrStsTiStampStsTiOut 0;
BA_ "GenSigSendType" SG_ 1129 ReSideRdrRiStsRdrStsWhlSpdCmpFac 0;
BA_ "GenSigStartValue" SG_ 1129 ReSideRdrRiStsRdrStsWhlSpdCmpFac 16;
BA_ "GenSigSendType" SG_ 384 RoadInclnQly 0;
BA_ "GenSigStartValue" SG_ 384 RoadInclnQly 1;
BA_ "GenSigSendType" SG_ 384 RoadInclnRoadIncln 0;
BA_ "GenSigSendType" SG_ 1025 RoadLoadNomCoeff0 0;
BA_ "GenSigSendType" SG_ 1025 RoadLoadNomCoeff1 0;
BA_ "GenSigSendType" SG_ 1025 RoadLoadNomCoeff2 0;
BA_ "GenSigSendType" SG_ 1025 RoadLoadNomCoeffSts 0;
BA_ "GenSigSendType" SG_ 816 RollAgGlbQf 0;
BA_ "GenSigStartValue" SG_ 816 RollAgGlbQf 1;
BA_ "GenSigSendType" SG_ 816 RollAgGlbVal 0;
BA_ "GenSigDataID" SG_ 384 SpdRotlForWhlsAtAxleFrntChks "0x35";
BA_ "GenSigFuncType" SG_ 384 SpdRotlForWhlsAtAxleFrntChks 15;
BA_ "GenSigSendType" SG_ 384 SpdRotlForWhlsAtAxleFrntChks 0;
BA_ "GenSigFuncType" SG_ 384 SpdRotlForWhlsAtAxleFrntCntr 16;
BA_ "GenSigSendType" SG_ 384 SpdRotlForWhlsAtAxleFrntCntr 0;
BA_ "GenSigSendType" SG_ 384 SpdRotlForWhlsAtAxleFrntSpdRotlForWhlsAtAxleFrnt 0;
BA_ "GenSigSendType" SG_ 384 SpdRotlForWhlsAtAxleRe 0;
BA_ "GenSigSendType" SG_ 402 StandStillMgrStsForHld1 0;
BA_ "GenSigSendType" SG_ 1025 StandStillMgrStsForHldByBrkChks 0;
BA_ "GenSigSendType" SG_ 1025 StandStillMgrStsForHldByBrkCntr 0;
BA_ "GenSigSendType" SG_ 1025 StandStillMgrStsForHldByBrkStandStillMgrStsForHld1 0;
BA_ "GenSigDataID" SG_ 402 StandStillMgrStsForHldChks "0x448";
BA_ "GenSigFuncType" SG_ 402 StandStillMgrStsForHldChks 15;
BA_ "GenSigSendType" SG_ 402 StandStillMgrStsForHldChks 0;
BA_ "GenSigFuncType" SG_ 402 StandStillMgrStsForHldCntr 16;
BA_ "GenSigSendType" SG_ 402 StandStillMgrStsForHldCntr 0;
BA_ "GenSigSendType" SG_ 1025 StandStillMgrStsForPark 0;
BA_ "GenSigDataID" SG_ 257 StcStsToDmcChks "0x19A5";
BA_ "GenSigFuncType" SG_ 257 StcStsToDmcChks 15;
BA_ "GenSigSendType" SG_ 257 StcStsToDmcChks 0;
BA_ "GenSigFuncType" SG_ 257 StcStsToDmcCntr 16;
BA_ "GenSigSendType" SG_ 257 StcStsToDmcCntr 0;
BA_ "GenSigSendType" SG_ 257 StcStsToDmcEngRotTarSpdDMCFrnt 0;
BA_ "GenSigSendType" SG_ 257 StcStsToDmcEngRotTarSpdDMCRear 0;
BA_ "GenSigSendType" SG_ 257 StcStsToDmcFrnt 0;
BA_ "GenSigSendType" SG_ 257 StcStsToDmcRear 0;
BA_ "GenSigSendType" SG_ 997 SteerAssiAvlSts 0;
BA_ "GenSigSendType" SG_ 257 SteerAssiCtrlSts 0;
BA_ "GenSigSendType" SG_ 997 SteerAssiWarnMsg 0;
BA_ "GenSigSendType" SG_ 483 SuspPosnVertAgGenQf 0;
BA_ "GenSigStartValue" SG_ 483 SuspPosnVertAgGenQf 1;
BA_ "GenSigSendType" SG_ 483 SuspPosnVertAgSuspPosnVertAg 0;
BA_ "GenSigSendType" SG_ 483 SuspPosnVertLvlFrnt 0;
BA_ "GenSigSendType" SG_ 483 SuspPosnVertLvlFrntQf 0;
BA_ "GenSigSendType" SG_ 483 SuspPosnVertLvlRe 0;
BA_ "GenSigSendType" SG_ 483 SuspPosnVertLvlReQf 0;
BA_ "GenSigSendType" SG_ 805 SwtStsforHillDwnCtrl 0;
BA_ "GenSigSendType" SG_ 704 TireRdEstimd 0;
BA_ "GenSigStartValue" SG_ 704 TireRdEstimd 266.2406816;
BA_ "GenSigSendType" SG_ 257 TqRednDurgCllsnMtgtnByBrkg 0;
BA_ "GenSigSendType" SG_ 341 TripResetSyncReqMsgASDM 1;
BA_ "GenSigSendType" SG_ 1025 TrlrModBCSts 0;
BA_ "GenSigSendType" SG_ 997 VBFAvlSts 0;
BA_ "GenSigSendType" SG_ 1345 VFCVectorASDMBlockID 0;
BA_ "GenSigSendType" SG_ 1345 VFCVectorASDMVFCid0 0;
BA_ "GenSigSendType" SG_ 1345 VFCVectorASDMVFCid1 0;
BA_ "GenSigSendType" SG_ 1345 VFCVectorASDMVFCid10 0;
BA_ "GenSigSendType" SG_ 1345 VFCVectorASDMVFCid11 0;
BA_ "GenSigSendType" SG_ 1345 VFCVectorASDMVFCid12 0;
BA_ "GenSigSendType" SG_ 1345 VFCVectorASDMVFCid13 0;
BA_ "GenSigSendType" SG_ 1345 VFCVectorASDMVFCid14 0;
BA_ "GenSigSendType" SG_ 1345 VFCVectorASDMVFCid15 0;
BA_ "GenSigSendType" SG_ 1345 VFCVectorASDMVFCid16 0;
BA_ "GenSigSendType" SG_ 1345 VFCVectorASDMVFCid17 0;
BA_ "GenSigSendType" SG_ 1345 VFCVectorASDMVFCid18 0;
BA_ "GenSigSendType" SG_ 1345 VFCVectorASDMVFCid19 0;
BA_ "GenSigSendType" SG_ 1345 VFCVectorASDMVFCid2 0;
BA_ "GenSigSendType" SG_ 1345 VFCVectorASDMVFCid20 0;
BA_ "GenSigSendType" SG_ 1345 VFCVectorASDMVFCid21 0;
BA_ "GenSigSendType" SG_ 1345 VFCVectorASDMVFCid22 0;
BA_ "GenSigSendType" SG_ 1345 VFCVectorASDMVFCid23 0;
BA_ "GenSigSendType" SG_ 1345 VFCVectorASDMVFCid24 0;
BA_ "GenSigSendType" SG_ 1345 VFCVectorASDMVFCid25 0;
BA_ "GenSigSendType" SG_ 1345 VFCVectorASDMVFCid26 0;
BA_ "GenSigSendType" SG_ 1345 VFCVectorASDMVFCid27 0;
BA_ "GenSigSendType" SG_ 1345 VFCVectorASDMVFCid28 0;
BA_ "GenSigSendType" SG_ 1345 VFCVectorASDMVFCid29 0;
BA_ "GenSigSendType" SG_ 1345 VFCVectorASDMVFCid3 0;
BA_ "GenSigSendType" SG_ 1345 VFCVectorASDMVFCid30 0;
BA_ "GenSigSendType" SG_ 1345 VFCVectorASDMVFCid31 0;
BA_ "GenSigSendType" SG_ 1345 VFCVectorASDMVFCid32 0;
BA_ "GenSigSendType" SG_ 1345 VFCVectorASDMVFCid33 0;
BA_ "GenSigSendType" SG_ 1345 VFCVectorASDMVFCid34 0;
BA_ "GenSigSendType" SG_ 1345 VFCVectorASDMVFCid35 0;
BA_ "GenSigSendType" SG_ 1345 VFCVectorASDMVFCid36 0;
BA_ "GenSigSendType" SG_ 1345 VFCVectorASDMVFCid37 0;
BA_ "GenSigSendType" SG_ 1345 VFCVectorASDMVFCid38 0;
BA_ "GenSigSendType" SG_ 1345 VFCVectorASDMVFCid39 0;
BA_ "GenSigSendType" SG_ 1345 VFCVectorASDMVFCid4 0;
BA_ "GenSigSendType" SG_ 1345 VFCVectorASDMVFCid40 0;
BA_ "GenSigSendType" SG_ 1345 VFCVectorASDMVFCid41 0;
BA_ "GenSigSendType" SG_ 1345 VFCVectorASDMVFCid42 0;
BA_ "GenSigSendType" SG_ 1345 VFCVectorASDMVFCid43 0;
BA_ "GenSigSendType" SG_ 1345 VFCVectorASDMVFCid44 0;
BA_ "GenSigSendType" SG_ 1345 VFCVectorASDMVFCid45 0;
BA_ "GenSigSendType" SG_ 1345 VFCVectorASDMVFCid46 0;
BA_ "GenSigSendType" SG_ 1345 VFCVectorASDMVFCid47 0;
BA_ "GenSigSendType" SG_ 1345 VFCVectorASDMVFCid48 0;
BA_ "GenSigSendType" SG_ 1345 VFCVectorASDMVFCid49 0;
BA_ "GenSigSendType" SG_ 1345 VFCVectorASDMVFCid5 0;
BA_ "GenSigSendType" SG_ 1345 VFCVectorASDMVFCid50 0;
BA_ "GenSigSendType" SG_ 1345 VFCVectorASDMVFCid51 0;
BA_ "GenSigSendType" SG_ 1345 VFCVectorASDMVFCid52 0;
BA_ "GenSigSendType" SG_ 1345 VFCVectorASDMVFCid53 0;
BA_ "GenSigSendType" SG_ 1345 VFCVectorASDMVFCid54 0;
BA_ "GenSigSendType" SG_ 1345 VFCVectorASDMVFCid55 0;
BA_ "GenSigSendType" SG_ 1345 VFCVectorASDMVFCid56 0;
BA_ "GenSigSendType" SG_ 1345 VFCVectorASDMVFCid57 0;
BA_ "GenSigSendType" SG_ 1345 VFCVectorASDMVFCid58 0;
BA_ "GenSigSendType" SG_ 1345 VFCVectorASDMVFCid59 0;
BA_ "GenSigSendType" SG_ 1345 VFCVectorASDMVFCid6 0;
BA_ "GenSigSendType" SG_ 1345 VFCVectorASDMVFCid60 0;
BA_ "GenSigSendType" SG_ 1345 VFCVectorASDMVFCid61 0;
BA_ "GenSigSendType" SG_ 1345 VFCVectorASDMVFCid7 0;
BA_ "GenSigSendType" SG_ 1345 VFCVectorASDMVFCid8 0;
BA_ "GenSigSendType" SG_ 1345 VFCVectorASDMVFCid9 0;
BA_ "GenSigDataID" SG_ 98 VehDynCtrlStsForALgtCmftVehDynCtrlStsChks "0x87";
BA_ "GenSigFuncType" SG_ 98 VehDynCtrlStsForALgtCmftVehDynCtrlStsChks 15;
BA_ "GenSigSendType" SG_ 98 VehDynCtrlStsForALgtCmftVehDynCtrlStsChks 0;
BA_ "GenSigFuncType" SG_ 98 VehDynCtrlStsForALgtCmftVehDynCtrlStsCntr 16;
BA_ "GenSigSendType" SG_ 98 VehDynCtrlStsForALgtCmftVehDynCtrlStsCntr 0;
BA_ "GenSigSendType" SG_ 98 VehDynCtrlStsForALgtCmftVehDynCtrlStsDend 0;
BA_ "GenSigSendType" SG_ 98 VehDynCtrlStsForALgtCmftVehDynCtrlStsForBrkActv 0;
BA_ "GenSigSendType" SG_ 98 VehDynCtrlStsForALgtCmftVehDynCtrlStsForBrkPrecActv 0;
BA_ "GenSigSendType" SG_ 98 VehDynCtrlStsForALgtCmftVehDynCtrlStsForStandStillMgrForPark 0;
BA_ "GenSigSendType" SG_ 98 VehDynCtrlStsForALgtCmftVehDynCtrlStsForWhlBrkWrm 0;
BA_ "GenSigSendType" SG_ 98 VehDynCtrlStsForALgtCmftVehDynCtrlStsNotEna 0;
BA_ "GenSigSendType" SG_ 402 VehMNomTrlrM 0;
BA_ "GenSigSendType" SG_ 402 VehMNomVehM 0;
BA_ "GenSigSendType" SG_ 402 VehMNomVehMQly 0;
BA_ "GenSigStartValue" SG_ 402 VehMNomVehMQly 1;
BA_ "GenSigDataID" SG_ 98 VehMtnStChks "0x36";
BA_ "GenSigFuncType" SG_ 98 VehMtnStChks 15;
BA_ "GenSigSendType" SG_ 98 VehMtnStChks 0;
BA_ "GenSigFuncType" SG_ 98 VehMtnStCntr 16;
BA_ "GenSigSendType" SG_ 98 VehMtnStCntr 0;
BA_ "GenSigSendType" SG_ 98 VehMtnStVehMtnSt 0;
BA_ "GenSigSendType" SG_ 544 VehObjforADB1AdbAbsDist 0;
BA_ "GenSigSendType" SG_ 544 VehObjforADB1AdbClassn 0;
BA_ "GenSigSendType" SG_ 544 VehObjforADB1AdbHozlAgLe 0;
BA_ "GenSigStartValue" SG_ 544 VehObjforADB1AdbHozlAgLe 800;
BA_ "GenSigSendType" SG_ 544 VehObjforADB1AdbHozlAgRi 0;
BA_ "GenSigStartValue" SG_ 544 VehObjforADB1AdbHozlAgRi 800;
BA_ "GenSigSendType" SG_ 544 VehObjforADB1AdbObjDir 0;
BA_ "GenSigSendType" SG_ 544 VehObjforADB1AdbObjHozlAgSpdLe 0;
BA_ "GenSigStartValue" SG_ 544 VehObjforADB1AdbObjHozlAgSpdLe 250;
BA_ "GenSigSendType" SG_ 544 VehObjforADB1AdbObjHozlAgSpdRi 0;
BA_ "GenSigStartValue" SG_ 544 VehObjforADB1AdbObjHozlAgSpdRi 250;
BA_ "GenSigSendType" SG_ 544 VehObjforADB1AdbTrkInfo 0;
BA_ "GenSigSendType" SG_ 544 VehObjforADB1AdbVertAg 0;
BA_ "GenSigStartValue" SG_ 544 VehObjforADB1AdbVertAg 6;
BA_ "GenSigSendType" SG_ 544 VehObjforADB2AdbAbsDist 0;
BA_ "GenSigSendType" SG_ 544 VehObjforADB2AdbClassn 0;
BA_ "GenSigSendType" SG_ 544 VehObjforADB2AdbHozlAgLe 0;
BA_ "GenSigStartValue" SG_ 544 VehObjforADB2AdbHozlAgLe 800;
BA_ "GenSigSendType" SG_ 544 VehObjforADB2AdbHozlAgRi 0;
BA_ "GenSigStartValue" SG_ 544 VehObjforADB2AdbHozlAgRi 800;
BA_ "GenSigSendType" SG_ 544 VehObjforADB2AdbObjDir 0;
BA_ "GenSigSendType" SG_ 544 VehObjforADB2AdbObjHozlAgSpdLe 0;
BA_ "GenSigStartValue" SG_ 544 VehObjforADB2AdbObjHozlAgSpdLe 250;
BA_ "GenSigSendType" SG_ 544 VehObjforADB2AdbObjHozlAgSpdRi 0;
BA_ "GenSigStartValue" SG_ 544 VehObjforADB2AdbObjHozlAgSpdRi 250;
BA_ "GenSigSendType" SG_ 544 VehObjforADB2AdbTrkInfo 0;
BA_ "GenSigSendType" SG_ 544 VehObjforADB2AdbVertAg 0;
BA_ "GenSigStartValue" SG_ 544 VehObjforADB2AdbVertAg 6;
BA_ "GenSigSendType" SG_ 544 VehObjforADB3AdbAbsDist 0;
BA_ "GenSigSendType" SG_ 544 VehObjforADB3AdbClassn 0;
BA_ "GenSigSendType" SG_ 544 VehObjforADB3AdbHozlAgLe 0;
BA_ "GenSigStartValue" SG_ 544 VehObjforADB3AdbHozlAgLe 800;
BA_ "GenSigSendType" SG_ 544 VehObjforADB3AdbHozlAgRi 0;
BA_ "GenSigStartValue" SG_ 544 VehObjforADB3AdbHozlAgRi 800;
BA_ "GenSigSendType" SG_ 544 VehObjforADB3AdbObjDir 0;
BA_ "GenSigSendType" SG_ 544 VehObjforADB3AdbObjHozlAgSpdLe 0;
BA_ "GenSigStartValue" SG_ 544 VehObjforADB3AdbObjHozlAgSpdLe 250;
BA_ "GenSigSendType" SG_ 544 VehObjforADB3AdbObjHozlAgSpdRi 0;
BA_ "GenSigStartValue" SG_ 544 VehObjforADB3AdbObjHozlAgSpdRi 250;
BA_ "GenSigSendType" SG_ 544 VehObjforADB3AdbTrkInfo 0;
BA_ "GenSigSendType" SG_ 544 VehObjforADB3AdbVertAg 0;
BA_ "GenSigStartValue" SG_ 544 VehObjforADB3AdbVertAg 6;
BA_ "GenSigSendType" SG_ 544 VehObjforADB4AdbAbsDist 0;
BA_ "GenSigSendType" SG_ 544 VehObjforADB4AdbClassn 0;
BA_ "GenSigSendType" SG_ 544 VehObjforADB4AdbHozlAgLe 0;
BA_ "GenSigStartValue" SG_ 544 VehObjforADB4AdbHozlAgLe 800;
BA_ "GenSigSendType" SG_ 544 VehObjforADB4AdbHozlAgRi 0;
BA_ "GenSigStartValue" SG_ 544 VehObjforADB4AdbHozlAgRi 800;
BA_ "GenSigSendType" SG_ 544 VehObjforADB4AdbObjDir 0;
BA_ "GenSigSendType" SG_ 544 VehObjforADB4AdbObjHozlAgSpdLe 0;
BA_ "GenSigStartValue" SG_ 544 VehObjforADB4AdbObjHozlAgSpdLe 250;
BA_ "GenSigSendType" SG_ 544 VehObjforADB4AdbObjHozlAgSpdRi 0;
BA_ "GenSigStartValue" SG_ 544 VehObjforADB4AdbObjHozlAgSpdRi 250;
BA_ "GenSigSendType" SG_ 544 VehObjforADB4AdbTrkInfo 0;
BA_ "GenSigSendType" SG_ 544 VehObjforADB4AdbVertAg 0;
BA_ "GenSigStartValue" SG_ 544 VehObjforADB4AdbVertAg 6;
BA_ "GenSigSendType" SG_ 544 VehObjforADB5AdbAbsDist 0;
BA_ "GenSigSendType" SG_ 544 VehObjforADB5AdbClassn 0;
BA_ "GenSigSendType" SG_ 544 VehObjforADB5AdbHozlAgLe 0;
BA_ "GenSigStartValue" SG_ 544 VehObjforADB5AdbHozlAgLe 800;
BA_ "GenSigSendType" SG_ 544 VehObjforADB5AdbHozlAgRi 0;
BA_ "GenSigStartValue" SG_ 544 VehObjforADB5AdbHozlAgRi 800;
BA_ "GenSigSendType" SG_ 544 VehObjforADB5AdbObjDir 0;
BA_ "GenSigSendType" SG_ 544 VehObjforADB5AdbObjHozlAgSpdLe 0;
BA_ "GenSigStartValue" SG_ 544 VehObjforADB5AdbObjHozlAgSpdLe 250;
BA_ "GenSigSendType" SG_ 544 VehObjforADB5AdbObjHozlAgSpdRi 0;
BA_ "GenSigStartValue" SG_ 544 VehObjforADB5AdbObjHozlAgSpdRi 250;
BA_ "GenSigSendType" SG_ 544 VehObjforADB5AdbTrkInfo 0;
BA_ "GenSigSendType" SG_ 544 VehObjforADB5AdbVertAg 0;
BA_ "GenSigStartValue" SG_ 544 VehObjforADB5AdbVertAg 6;
BA_ "GenSigSendType" SG_ 544 VehObjforADB6AdbAbsDist 0;
BA_ "GenSigSendType" SG_ 544 VehObjforADB6AdbClassn 0;
BA_ "GenSigSendType" SG_ 544 VehObjforADB6AdbHozlAgLe 0;
BA_ "GenSigStartValue" SG_ 544 VehObjforADB6AdbHozlAgLe 800;
BA_ "GenSigSendType" SG_ 544 VehObjforADB6AdbHozlAgRi 0;
BA_ "GenSigStartValue" SG_ 544 VehObjforADB6AdbHozlAgRi 800;
BA_ "GenSigSendType" SG_ 544 VehObjforADB6AdbObjDir 0;
BA_ "GenSigSendType" SG_ 544 VehObjforADB6AdbObjHozlAgSpdLe 0;
BA_ "GenSigStartValue" SG_ 544 VehObjforADB6AdbObjHozlAgSpdLe 250;
BA_ "GenSigSendType" SG_ 544 VehObjforADB6AdbObjHozlAgSpdRi 0;
BA_ "GenSigStartValue" SG_ 544 VehObjforADB6AdbObjHozlAgSpdRi 250;
BA_ "GenSigSendType" SG_ 544 VehObjforADB6AdbTrkInfo 0;
BA_ "GenSigSendType" SG_ 544 VehObjforADB6AdbVertAg 0;
BA_ "GenSigStartValue" SG_ 544 VehObjforADB6AdbVertAg 6;
BA_ "GenSigSendType" SG_ 544 VehObjforADB7AdbAbsDist 0;
BA_ "GenSigSendType" SG_ 544 VehObjforADB7AdbClassn 0;
BA_ "GenSigSendType" SG_ 544 VehObjforADB7AdbHozlAgLe 0;
BA_ "GenSigStartValue" SG_ 544 VehObjforADB7AdbHozlAgLe 800;
BA_ "GenSigSendType" SG_ 544 VehObjforADB7AdbHozlAgRi 0;
BA_ "GenSigStartValue" SG_ 544 VehObjforADB7AdbHozlAgRi 800;
BA_ "GenSigSendType" SG_ 544 VehObjforADB7AdbObjDir 0;
BA_ "GenSigSendType" SG_ 544 VehObjforADB7AdbObjHozlAgSpdLe 0;
BA_ "GenSigStartValue" SG_ 544 VehObjforADB7AdbObjHozlAgSpdLe 250;
BA_ "GenSigSendType" SG_ 544 VehObjforADB7AdbObjHozlAgSpdRi 0;
BA_ "GenSigStartValue" SG_ 544 VehObjforADB7AdbObjHozlAgSpdRi 250;
BA_ "GenSigSendType" SG_ 544 VehObjforADB7AdbTrkInfo 0;
BA_ "GenSigSendType" SG_ 544 VehObjforADB7AdbVertAg 0;
BA_ "GenSigStartValue" SG_ 544 VehObjforADB7AdbVertAg 6;
BA_ "GenSigSendType" SG_ 544 VehObjforADB8AdbAbsDist 0;
BA_ "GenSigSendType" SG_ 544 VehObjforADB8AdbClassn 0;
BA_ "GenSigSendType" SG_ 544 VehObjforADB8AdbHozlAgLe 0;
BA_ "GenSigStartValue" SG_ 544 VehObjforADB8AdbHozlAgLe 800;
BA_ "GenSigSendType" SG_ 544 VehObjforADB8AdbHozlAgRi 0;
BA_ "GenSigStartValue" SG_ 544 VehObjforADB8AdbHozlAgRi 800;
BA_ "GenSigSendType" SG_ 544 VehObjforADB8AdbObjDir 0;
BA_ "GenSigSendType" SG_ 544 VehObjforADB8AdbObjHozlAgSpdLe 0;
BA_ "GenSigStartValue" SG_ 544 VehObjforADB8AdbObjHozlAgSpdLe 250;
BA_ "GenSigSendType" SG_ 544 VehObjforADB8AdbObjHozlAgSpdRi 0;
BA_ "GenSigStartValue" SG_ 544 VehObjforADB8AdbObjHozlAgSpdRi 250;
BA_ "GenSigSendType" SG_ 544 VehObjforADB8AdbTrkInfo 0;
BA_ "GenSigSendType" SG_ 544 VehObjforADB8AdbVertAg 0;
BA_ "GenSigStartValue" SG_ 544 VehObjforADB8AdbVertAg 6;
BA_ "GenSigSendType" SG_ 98 VehSpdLgtA 0;
BA_ "GenSigDataID" SG_ 98 VehSpdLgtChks "0x37";
BA_ "GenSigFuncType" SG_ 98 VehSpdLgtChks 15;
BA_ "GenSigSendType" SG_ 98 VehSpdLgtChks 0;
BA_ "GenSigFuncType" SG_ 98 VehSpdLgtCntr 16;
BA_ "GenSigSendType" SG_ 98 VehSpdLgtCntr 0;
BA_ "GenSigSendType" SG_ 98 VehSpdLgtQf 0;
BA_ "GenSigStartValue" SG_ 98 VehSpdLgtQf 1;
BA_ "GenSigSendType" SG_ 997 VehSpdLgtTar 0;
BA_ "GenSigSendType" SG_ 402 VehVLat 0;
BA_ "GenSigSendType" SG_ 402 VehVLatQf 0;
BA_ "GenSigStartValue" SG_ 402 VehVLatQf 1;
BA_ "GenSigSendType" SG_ 402 VehVLgt 0;
BA_ "GenSigSendType" SG_ 402 VehVLgtQf 0;
BA_ "GenSigStartValue" SG_ 402 VehVLgtQf 1;
BA_ "GenSigSendType" SG_ 1281 WakeUpReasonsforADCU 0;
BA_ "GenSigSendType" SG_ 98 WhlAFrntMax 0;
BA_ "GenSigSendType" SG_ 483 WhlBrkOvrheatd 0;
BA_ "GenSigSendType" SG_ 800 WhlBrkWrm 0;
BA_ "GenSigDataID" SG_ 402 WhlDirRotlFrntChks "0x228";
BA_ "GenSigFuncType" SG_ 402 WhlDirRotlFrntChks 15;
BA_ "GenSigSendType" SG_ 402 WhlDirRotlFrntChks 0;
BA_ "GenSigFuncType" SG_ 402 WhlDirRotlFrntCntr 16;
BA_ "GenSigSendType" SG_ 402 WhlDirRotlFrntCntr 0;
BA_ "GenSigSendType" SG_ 402 WhlDirRotlFrntLe 0;
BA_ "GenSigSendType" SG_ 402 WhlDirRotlFrntRi 0;
BA_ "GenSigDataID" SG_ 402 WhlDirRotlReChks "0x227";
BA_ "GenSigFuncType" SG_ 402 WhlDirRotlReChks 15;
BA_ "GenSigSendType" SG_ 402 WhlDirRotlReChks 0;
BA_ "GenSigFuncType" SG_ 402 WhlDirRotlReCntr 16;
BA_ "GenSigSendType" SG_ 402 WhlDirRotlReCntr 0;
BA_ "GenSigSendType" SG_ 402 WhlDirRotlReLe 0;
BA_ "GenSigSendType" SG_ 402 WhlDirRotlReRi 0;
BA_ "GenSigSendType" SG_ 402 WhlFastSpdSafeA 0;
BA_ "GenSigDataID" SG_ 402 WhlFastSpdSafeChks "0x1972";
BA_ "GenSigFuncType" SG_ 402 WhlFastSpdSafeChks 15;
BA_ "GenSigSendType" SG_ 402 WhlFastSpdSafeChks 0;
BA_ "GenSigFuncType" SG_ 402 WhlFastSpdSafeCntr 16;
BA_ "GenSigSendType" SG_ 402 WhlFastSpdSafeCntr 0;
BA_ "GenSigSendType" SG_ 402 WhlFastSpdSafeQF 0;
BA_ "GenSigStartValue" SG_ 402 WhlFastSpdSafeQF 1;
BA_ "GenSigSendType" SG_ 608 WhlRotCntrFrnt 0;
BA_ "GenSigDataID" SG_ 402 WhlRotToothCntrChks "0x19C8";
BA_ "GenSigFuncType" SG_ 402 WhlRotToothCntrChks 15;
BA_ "GenSigSendType" SG_ 402 WhlRotToothCntrChks 0;
BA_ "GenSigFuncType" SG_ 402 WhlRotToothCntrCntr 16;
BA_ "GenSigSendType" SG_ 402 WhlRotToothCntrCntr 0;
BA_ "GenSigSendType" SG_ 402 WhlRotToothCntrFrntLe 0;
BA_ "GenSigSendType" SG_ 402 WhlRotToothCntrFrntRi 0;
BA_ "GenSigSendType" SG_ 402 WhlRotToothCntrReLe 0;
BA_ "GenSigSendType" SG_ 402 WhlRotToothCntrReRi 0;
BA_ "GenSigSendType" SG_ 483 WhlSpdCalcALgtALgt 0;
BA_ "GenSigStartValue" SG_ 483 WhlSpdCalcALgtALgt 1016.9491525;
BA_ "GenSigDataID" SG_ 483 WhlSpdCalcALgtChks "0xF8";
BA_ "GenSigFuncType" SG_ 483 WhlSpdCalcALgtChks 15;
BA_ "GenSigSendType" SG_ 483 WhlSpdCalcALgtChks 0;
BA_ "GenSigFuncType" SG_ 483 WhlSpdCalcALgtCntr 16;
BA_ "GenSigSendType" SG_ 483 WhlSpdCalcALgtCntr 0;
BA_ "GenSigDataID" SG_ 402 WhlSpdCircumlFrntChks "0x6F";
BA_ "GenSigFuncType" SG_ 402 WhlSpdCircumlFrntChks 15;
BA_ "GenSigSendType" SG_ 402 WhlSpdCircumlFrntChks 0;
BA_ "GenSigFuncType" SG_ 402 WhlSpdCircumlFrntCntr 16;
BA_ "GenSigSendType" SG_ 402 WhlSpdCircumlFrntCntr 0;
BA_ "GenSigSendType" SG_ 402 WhlSpdCircumlFrntLe 0;
BA_ "GenSigSendType" SG_ 402 WhlSpdCircumlFrntLeQf 0;
BA_ "GenSigStartValue" SG_ 402 WhlSpdCircumlFrntLeQf 1;
BA_ "GenSigSendType" SG_ 402 WhlSpdCircumlFrntRiQf 0;
BA_ "GenSigStartValue" SG_ 402 WhlSpdCircumlFrntRiQf 1;
BA_ "GenSigSendType" SG_ 402 WhlSpdCircumlFrntWhlSpdCircumlFrntRi 0;
BA_ "GenSigDataID" SG_ 402 WhlSpdCircumlReChks "0x7C";
BA_ "GenSigFuncType" SG_ 402 WhlSpdCircumlReChks 15;
BA_ "GenSigSendType" SG_ 402 WhlSpdCircumlReChks 0;
BA_ "GenSigFuncType" SG_ 402 WhlSpdCircumlReCntr 16;
BA_ "GenSigSendType" SG_ 402 WhlSpdCircumlReCntr 0;
BA_ "GenSigSendType" SG_ 402 WhlSpdCircumlReLe 0;
BA_ "GenSigSendType" SG_ 402 WhlSpdCircumlReLeQf 0;
BA_ "GenSigStartValue" SG_ 402 WhlSpdCircumlReLeQf 1;
BA_ "GenSigSendType" SG_ 402 WhlSpdCircumlReRi 0;
BA_ "GenSigSendType" SG_ 402 WhlSpdCircumlReRiQf 0;
BA_ "GenSigStartValue" SG_ 402 WhlSpdCircumlReRiQf 1;
BA_ "GenSigSendType" SG_ 98 WhlVAgrFrntLe 0;
BA_ "GenSigSendType" SG_ 98 WhlVAgrFrntLeQf 0;
BA_ "GenSigSendType" SG_ 98 WhlVAgrFrntRi 0;
BA_ "GenSigSendType" SG_ 98 WhlVAgrFrntRiQf 0;
BA_ "GenSigSendType" SG_ 98 WhlVAgrReLe 0;
BA_ "GenSigSendType" SG_ 98 WhlVAgrReLeQf 0;
BA_ "GenSigSendType" SG_ 98 WhlVAgrReRi 0;
BA_ "GenSigSendType" SG_ 98 WhlVAgrReRiQf 0;
BA_ "GenSigSendType" SG_ 402 YawRateReqdByDrvr 0;
BA_ "GenSigSendType" SG_ 1025 YawStabyCtrlActv 0;
VAL_ 544 VehObjforADB1AdbClassn 0 "AdbClassn_NoVehicle" 1 "AdbClassn_Car" 2 "AdbClassn_Truck" 3 "AdbClassn_Bus" 4 "AdbClassn_BikeOrMotorBike" 5 "AdbClassn_Pedestrain" 6 "AdbClassn_Mixed" 7 "AdbClassn_Unknown";
VAL_ 544 VehObjforADB1AdbObjDir 0 "AdbObjDir_Idle" 1 "AdbObjDir_Oncoming" 2 "AdbObjDir_Preceding" 3 "AdbObjDir_Others";
VAL_ 544 VehObjforADB1AdbTrkInfo 0 "NotTracked" 1 "Tracking";
VAL_ 544 VehObjforADB2AdbClassn 0 "AdbClassn_NoVehicle" 1 "AdbClassn_Car" 2 "AdbClassn_Truck" 3 "AdbClassn_Bus" 4 "AdbClassn_BikeOrMotorBike" 5 "AdbClassn_Pedestrain" 6 "AdbClassn_Mixed" 7 "AdbClassn_Unknown";
VAL_ 544 VehObjforADB2AdbObjDir 0 "AdbObjDir_Idle" 1 "AdbObjDir_Oncoming" 2 "AdbObjDir_Preceding" 3 "AdbObjDir_Others";
VAL_ 544 VehObjforADB2AdbTrkInfo 0 "NotTracked" 1 "Tracking";
VAL_ 544 VehObjforADB3AdbClassn 0 "AdbClassn_NoVehicle" 1 "AdbClassn_Car" 2 "AdbClassn_Truck" 3 "AdbClassn_Bus" 4 "AdbClassn_BikeOrMotorBike" 5 "AdbClassn_Pedestrain" 6 "AdbClassn_Mixed" 7 "AdbClassn_Unknown";
VAL_ 544 VehObjforADB3AdbObjDir 0 "AdbObjDir_Idle" 1 "AdbObjDir_Oncoming" 2 "AdbObjDir_Preceding" 3 "AdbObjDir_Others";
VAL_ 544 VehObjforADB3AdbTrkInfo 0 "NotTracked" 1 "Tracking";
VAL_ 544 VehObjforADB4AdbClassn 0 "AdbClassn_NoVehicle" 1 "AdbClassn_Car" 2 "AdbClassn_Truck" 3 "AdbClassn_Bus" 4 "AdbClassn_BikeOrMotorBike" 5 "AdbClassn_Pedestrain" 6 "AdbClassn_Mixed" 7 "AdbClassn_Unknown";
VAL_ 544 VehObjforADB4AdbObjDir 0 "AdbObjDir_Idle" 1 "AdbObjDir_Oncoming" 2 "AdbObjDir_Preceding" 3 "AdbObjDir_Others";
VAL_ 544 VehObjforADB4AdbTrkInfo 0 "NotTracked" 1 "Tracking";
VAL_ 544 VehObjforADB5AdbClassn 0 "AdbClassn_NoVehicle" 1 "AdbClassn_Car" 2 "AdbClassn_Truck" 3 "AdbClassn_Bus" 4 "AdbClassn_BikeOrMotorBike" 5 "AdbClassn_Pedestrain" 6 "AdbClassn_Mixed" 7 "AdbClassn_Unknown";
VAL_ 544 VehObjforADB5AdbObjDir 0 "AdbObjDir_Idle" 1 "AdbObjDir_Oncoming" 2 "AdbObjDir_Preceding" 3 "AdbObjDir_Others";
VAL_ 544 VehObjforADB5AdbTrkInfo 0 "NotTracked" 1 "Tracking";
VAL_ 544 VehObjforADB6AdbClassn 0 "AdbClassn_NoVehicle" 1 "AdbClassn_Car" 2 "AdbClassn_Truck" 3 "AdbClassn_Bus" 4 "AdbClassn_BikeOrMotorBike" 5 "AdbClassn_Pedestrain" 6 "AdbClassn_Mixed" 7 "AdbClassn_Unknown";
VAL_ 544 VehObjforADB6AdbObjDir 0 "AdbObjDir_Idle" 1 "AdbObjDir_Oncoming" 2 "AdbObjDir_Preceding" 3 "AdbObjDir_Others";
VAL_ 544 VehObjforADB6AdbTrkInfo 0 "NotTracked" 1 "Tracking";
VAL_ 544 VehObjforADB7AdbClassn 0 "AdbClassn_NoVehicle" 1 "AdbClassn_Car" 2 "AdbClassn_Truck" 3 "AdbClassn_Bus" 4 "AdbClassn_BikeOrMotorBike" 5 "AdbClassn_Pedestrain" 6 "AdbClassn_Mixed" 7 "AdbClassn_Unknown";
VAL_ 544 VehObjforADB7AdbObjDir 0 "AdbObjDir_Idle" 1 "AdbObjDir_Oncoming" 2 "AdbObjDir_Preceding" 3 "AdbObjDir_Others";
VAL_ 544 VehObjforADB7AdbTrkInfo 0 "NotTracked" 1 "Tracking";
VAL_ 544 VehObjforADB8AdbClassn 0 "AdbClassn_NoVehicle" 1 "AdbClassn_Car" 2 "AdbClassn_Truck" 3 "AdbClassn_Bus" 4 "AdbClassn_BikeOrMotorBike" 5 "AdbClassn_Pedestrain" 6 "AdbClassn_Mixed" 7 "AdbClassn_Unknown";
VAL_ 544 VehObjforADB8AdbObjDir 0 "AdbObjDir_Idle" 1 "AdbObjDir_Oncoming" 2 "AdbObjDir_Preceding" 3 "AdbObjDir_Others";
VAL_ 544 VehObjforADB8AdbTrkInfo 0 "NotTracked" 1 "Tracking";
VAL_ 1129 FrntRdrStsRdrStsBlkd0bin 0 "YesNo2_No" 1 "YesNo2_Yes";
VAL_ 1129 FrntRdrStsRdrStsEna 0 "YesNo2_No" 1 "YesNo2_Yes";
VAL_ 1129 FrntRdrStsRdrStsFaulty 0 "YesNo2_No" 1 "YesNo2_Yes";
VAL_ 1129 FrntRdrStsRdrStsMisAlign 0 "MisAlign_CalibrationNotStart" 1 "MisAlign_SuccessfullyCalibratedInFactoryOrAftersales" 2 "MisAlign_SuccessfullyAutoCalibrated" 3 "MisAlign_MisalignmentDegreeIsLargerThanThreshold_StaticCalibrationFail" 4 "MisAlign_CanNotBeCalibratedStaticallyCauseOtherReason" 5 "MisAlign_AutoCalibrateFail_CauseMisalignmentDegreeIsLargerThanThresholdOrOtherReason" 6 "MisAlign_MisalignmentDegreeIsLargerThanThreshold_DynamicCalibrationFailInFactoryOrAftersales" 7 "MisAlign_CanNotBeCalibratedDynamicallyCauseOtherReason";
VAL_ 1129 FrntRdrStsRdrStsMissCom 0 "YesNo2_No" 1 "YesNo2_Yes";
VAL_ 1129 FrntRdrStsRdrStsSftyFlt 0 "SftyFlt_Undefined" 1 "SftyFlt_NoSafetyFault" 2 "SftyFlt_SafetyFault" 3 "SftyFlt_Reserved";
VAL_ 1129 FrntRdrStsRdrStsTiStampStsGlbTiBas 0 "YesNo2_No" 1 "YesNo2_Yes";
VAL_ 1129 FrntRdrStsRdrStsTiStampStsSyncToGatewy 0 "YesNo2_No" 1 "YesNo2_Yes";
VAL_ 1129 FrntRdrStsRdrStsTiStampStsTiLeap 0 "YesNo2_No" 1 "YesNo2_Yes";
VAL_ 1129 FrntRdrStsRdrStsTiStampStsTiOut 0 "YesNo2_No" 1 "YesNo2_Yes";
VAL_ 1129 ReSideRdrLeStsRdrStsBlkd0bin 0 "YesNo2_No" 1 "YesNo2_Yes";
VAL_ 1129 ReSideRdrLeStsRdrStsEna 0 "YesNo2_No" 1 "YesNo2_Yes";
VAL_ 1129 ReSideRdrLeStsRdrStsFaulty 0 "YesNo2_No" 1 "YesNo2_Yes";
VAL_ 1129 ReSideRdrLeStsRdrStsMisAlign 0 "MisAlign_CalibrationNotStart" 1 "MisAlign_SuccessfullyCalibratedInFactoryOrAftersales" 2 "MisAlign_SuccessfullyAutoCalibrated" 3 "MisAlign_MisalignmentDegreeIsLargerThanThreshold_StaticCalibrationFail" 4 "MisAlign_CanNotBeCalibratedStaticallyCauseOtherReason" 5 "MisAlign_AutoCalibrateFail_CauseMisalignmentDegreeIsLargerThanThresholdOrOtherReason" 6 "MisAlign_MisalignmentDegreeIsLargerThanThreshold_DynamicCalibrationFailInFactoryOrAftersales" 7 "MisAlign_CanNotBeCalibratedDynamicallyCauseOtherReason";
VAL_ 1129 ReSideRdrLeStsRdrStsMissCom 0 "YesNo2_No" 1 "YesNo2_Yes";
VAL_ 1129 ReSideRdrLeStsRdrStsSftyFlt 0 "SftyFlt_Undefined" 1 "SftyFlt_NoSafetyFault" 2 "SftyFlt_SafetyFault" 3 "SftyFlt_Reserved";
VAL_ 1129 ReSideRdrLeStsRdrStsTiStampStsGlbTiBas 0 "YesNo2_No" 1 "YesNo2_Yes";
VAL_ 1129 ReSideRdrLeStsRdrStsTiStampStsSyncToGatewy 0 "YesNo2_No" 1 "YesNo2_Yes";
VAL_ 1129 ReSideRdrLeStsRdrStsTiStampStsTiLeap 0 "YesNo2_No" 1 "YesNo2_Yes";
VAL_ 1129 ReSideRdrLeStsRdrStsTiStampStsTiOut 0 "YesNo2_No" 1 "YesNo2_Yes";
VAL_ 1129 ReSideRdrRiStsRdrStsBlkd0bin 0 "YesNo2_No" 1 "YesNo2_Yes";
VAL_ 1129 ReSideRdrRiStsRdrStsEna 0 "YesNo2_No" 1 "YesNo2_Yes";
VAL_ 1129 ReSideRdrRiStsRdrStsFaulty 0 "YesNo2_No" 1 "YesNo2_Yes";
VAL_ 1129 ReSideRdrRiStsRdrStsMisAlign 0 "MisAlign_CalibrationNotStart" 1 "MisAlign_SuccessfullyCalibratedInFactoryOrAftersales" 2 "MisAlign_SuccessfullyAutoCalibrated" 3 "MisAlign_MisalignmentDegreeIsLargerThanThreshold_StaticCalibrationFail" 4 "MisAlign_CanNotBeCalibratedStaticallyCauseOtherReason" 5 "MisAlign_AutoCalibrateFail_CauseMisalignmentDegreeIsLargerThanThresholdOrOtherReason" 6 "MisAlign_MisalignmentDegreeIsLargerThanThreshold_DynamicCalibrationFailInFactoryOrAftersales" 7 "MisAlign_CanNotBeCalibratedDynamicallyCauseOtherReason";
VAL_ 1129 ReSideRdrRiStsRdrStsMissCom 0 "YesNo2_No" 1 "YesNo2_Yes";
VAL_ 1129 ReSideRdrRiStsRdrStsSftyFlt 0 "SftyFlt_Undefined" 1 "SftyFlt_NoSafetyFault" 2 "SftyFlt_SafetyFault" 3 "SftyFlt_Reserved";
VAL_ 1129 ReSideRdrRiStsRdrStsTiStampStsGlbTiBas 0 "YesNo2_No" 1 "YesNo2_Yes";
VAL_ 1129 ReSideRdrRiStsRdrStsTiStampStsSyncToGatewy 0 "YesNo2_No" 1 "YesNo2_Yes";
VAL_ 1129 ReSideRdrRiStsRdrStsTiStampStsTiLeap 0 "YesNo2_No" 1 "YesNo2_Yes";
VAL_ 1129 ReSideRdrRiStsRdrStsTiStampStsTiOut 0 "YesNo2_No" 1 "YesNo2_Yes";
VAL_ 1281 WakeUpReasonsforADCU 0 "WakeupReasons_667949" 1 "WakeupReasons_667950" 2 "WakeupReasons_169654" 3 "WakeupReasons_667951" 4 "WakeupReasons_168965" 5 "WakeupReasons_197643" 6 "WakeupReasons_264933" 7 "WakeupReasons_45654" 8 "WakeupReasons_22058" 9 "WakeupReasons_49446" 10 "WakeupReasons_22060" 11 "WakeupReasons_269740" 12 "WakeupReasons_269735" 13 "WakeupReasons_269739" 14 "WakeupReasons_658500" 15 "WakeupReasons_21901" 16 "WakeupReasons_45793" 17 "WakeupReasons_45794" 18 "WakeupReasons_22005" 19 "WakeupReasons_22013" 20 "WakeupReasons_22100" 21 "WakeupReasons_45659" 22 "WakeupReasons_45657" 23 "WakeupReasons_140084" 24 "WakeupReasons_21973" 25 "WakeupReasons_91253" 26 "WakeupReasons_88123" 27 "WakeupReasons_88125" 28 "WakeupReasons_321583" 29 "WakeupReasons_74188" 30 "WakeupReasons_667945" 31 "WakeupReasons_169655" 32 "WakeupReasons_667948" 33 "WakeupReasons_168966" 34 "WakeupReasons_170865" 35 "WakeupReasons_197642" 36 "WakeupReasons_264876" 37 "WakeupReasons_191050" 38 "WakeupReasons_182033" 39 "WakeupReasons_200937" 40 "WakeupReasons_170807" 41 "WakeupReasons_319139" 42 "WakeupReasons_100298" 43 "WakeupReasons_100275" 44 "WakeupReasons_100300" 45 "WakeupReasons_100278" 46 "WakeupReasons_100281" 47 "WakeupReasons_265333" 48 "WakeupReasons_108776" 49 "WakeupReasons_176921" 50 "WakeupReasons_197826" 51 "WakeupReasons_185670" 52 "WakeupReasons_161066" 53 "WakeupReasons_200156" 54 "WakeupReasons_225696" 55 "WakeupReasons_21997" 56 "WakeupReasons_45656" 57 "WakeupReasons_266860" 58 "WakeupReasons_169894" 59 "WakeupReasons_320282" 60 "WakeupReasons_319422" 61 "WakeupReasons_320277" 62 "WakeupReasons_355601" 63 "WakeupReasons_360904" 64 "WakeupReasons_361505" 65 "WakeupReasons_361509" 66 "WakeupReasons_645094" 67 "WakeupReasons_68676" 68 "WakeupReasons_360008" 69 "WakeupReasons_109382" 70 "WakeupReasons_119273" 71 "WakeupReasons_224065" 72 "WakeupReasons_68644" 73 "WakeupReasons_109364" 74 "WakeupReasons_68481" 75 "WakeupReasons_224061" 76 "WakeupReasons_360006" 77 "WakeupReasons_138997" 78 "WakeupReasons_634696" 79 "WakeupReasons_645810" 80 "WakeupReasons_297868" 81 "WakeupReasons_315364" 82 "WakeupReasons_109367" 83 "WakeupReasons_320126" 84 "WakeupReasons_109387" 85 "WakeupReasons_634710" 86 "WakeupReasons_338820" 87 "WakeupReasons_67182" 88 "WakeupReasons_152237" 89 "WakeupReasons_145707" 90 "WakeupReasons_199172" 91 "WakeupReasons_144897" 92 "WakeupReasons_186489" 93 "WakeupReasons_144970" 94 "WakeupReasons_152786" 95 "WakeupReasons_264932" 96 "WakeupReasons_264934" 97 "WakeupReasons_356190" 98 "WakeupReasons_145688" 99 "WakeupReasons_95444" 100 "WakeupReasons_169945" 101 "WakeupReasons_140678" 102 "WakeupReasons_222553" 103 "WakeupReasons_224831" 104 "WakeupReasons_201815" 105 "WakeupReasons_45864" 106 "WakeupReasons_659549" 107 "WakeupReasons_45866" 108 "WakeupReasons_45867" 109 "WakeupReasons_169884" 110 "WakeupReasons_264962" 111 "WakeupReasons_201348" 112 "WakeupReasons_320287" 113 "WakeupReasons_156412" 114 "WakeupReasons_133749" 115 "WakeupReasons_355409" 116 "WakeupReasons_636692" 117 "WakeupReasons_533044" 118 "WakeupReasons_106774" 119 "WakeupReasons_145311" 120 "WakeupReasons_145319" 121 "WakeupReasons_152774" 122 "WakeupReasons_145330" 123 "WakeupReasons_145388" 124 "WakeupReasons_145399" 125 "WakeupReasons_145362" 126 "WakeupReasons_145385" 127 "WakeupReasons_145373" 128 "WakeupReasons_145288" 129 "WakeupReasons_145419" 130 "WakeupReasons_145454" 131 "WakeupReasons_145462" 132 "WakeupReasons_269156" 133 "WakeupReasons_300427" 134 "WakeupReasons_220322" 135 "WakeupReasons_224617" 136 "WakeupReasons_224634" 137 "WakeupReasons_300682" 138 "WakeupReasons_264958" 139 "WakeupReasons_160597" 140 "WakeupReasons_160602" 141 "WakeupReasons_108841" 142 "WakeupReasons_265569" 143 "WakeupReasons_526429" 144 "WakeupReasons_514545" 145 "WakeupReasons_265232" 146 "WakeupReasons_644550" 147 "WakeupReasons_317616" 148 "WakeupReasons_354791" 149 "WakeupReasons_320631" 150 "WakeupReasons_337565" 151 "WakeupReasons_532007" 152 "WakeupReasons_514503" 153 "WakeupReasons_299117" 154 "WakeupReasons_340667" 155 "WakeupReasons_321845" 156 "WakeupReasons_179103" 157 "WakeupReasons_108810" 158 "WakeupReasons_322857" 159 "WakeupReasons_658603" 160 "WakeupReasons_197648" 161 "WakeupReasons_160596" 162 "WakeupReasons_361272" 163 "WakeupReasons_361279" 164 "WakeupReasons_265305" 165 "WakeupReasons_265328" 166 "WakeupReasons_265330" 167 "WakeupReasons_298808" 168 "WakeupReasons_515804" 169 "WakeupReasons_514502" 170 "WakeupReasons_645753" 171 "WakeupReasons_646109" 172 "WakeupReasons_299547" 173 "WakeupReasons_318342" 174 "WakeupReasons_360543" 175 "WakeupReasons_356549" 176 "WakeupReasons_198484" 177 "WakeupReasons_300681" 178 "WakeupReasons_359211" 179 "WakeupReasons_534077" 180 "WakeupReasons_525705" 181 "WakeupReasons_360299" 182 "WakeupReasons_526445" 183 "WakeupReasons_534145" 184 "WakeupReasons_192030" 185 "WakeupReasons_652361" 186 "WakeupReasons_355214" 187 "WakeupReasons_321317" 188 "WakeupReasons_359187" 189 "WakeupReasons_321057" 190 "WakeupReasons_321319" 191 "WakeupReasons_321323" 192 "WakeupReasons_321077" 193 "WakeupReasons_320895" 194 "WakeupReasons_655340" 195 "WakeupReasons_636556" 196 "WakeupReasons_108834" 197 "WakeupReasons_265937" 198 "WakeupReasons_533050" 199 "WakeupReasons_526426" 200 "WakeupReasons_264712" 201 "WakeupReasons_319401" 202 "WakeupReasons_643973" 203 "WakeupReasons_223715" 204 "WakeupReasons_199159" 205 "WakeupReasons_318382" 206 "WakeupReasons_226967" 207 "WakeupReasons_531743" 208 "WakeupReasons_360542" 209 "WakeupReasons_264726" 210 "WakeupReasons_535214" 211 "WakeupReasons_335068" 212 "WakeupReasons_316796" 213 "WakeupReasons_526438" 214 "WakeupReasons_198433" 215 "WakeupReasons_225961" 216 "WakeupReasons_197665" 217 "WakeupReasons_224550" 218 "WakeupReasons_667962" 219 "WakeupReasons_667953" 220 "WakeupReasons_110885" 221 "WakeupReasons_224552" 222 "WakeupReasons_224553" 223 "WakeupReasons_652546" 224 "WakeupReasons_331194" 225 "WakeupReasons_667820" 226 "WakeupReasons_659350" 227 "WakeupReasons_101706" 228 "WakeupReasons_101725" 229 "WakeupReasons_101728" 230 "WakeupReasons_101727" 231 "WakeupReasons_166267" 232 "WakeupReasons_156440" 233 "WakeupReasons_95949" 234 "WakeupReasons_112799" 235 "WakeupReasons_146470" 236 "WakeupReasons_176748" 237 "WakeupReasons_223920" 238 "WakeupReasons_668531" 239 "WakeupReasons_670087" 240 "WakeupReasons_668529" 241 "WakeupReasons_45858" 242 "WakeupReasons_315981" 243 "WakeupReasons_533370" 244 "WakeupReasons_533371" 245 "WakeupReasons_533372" 246 "WakeupReasons_241902" 247 "WakeupReasons_359559" 248 "WakeupReasons_516327" 249 "WakeupReasons_533872" 250 "WakeupReasons_45856" 251 "WakeupReasons_45853" 252 "WakeupReasons_45854" 253 "WakeupReasons_45852" 254 "WakeupReasons_45851" 255 "WakeupReasons_45850" 256 "WakeupReasons_45849" 257 "WakeupReasons_636801" 258 "WakeupReasons_109466" 259 "WakeupReasons_109467" 260 "WakeupReasons_670345" 261 "WakeupReasons_NMPDUReceived" 262 "WakeupReasons_358832" 263 "WakeupReasons_200683" 264 "WakeupReasons_198452" 265 "WakeupReasons_185457" 266 "WakeupReasons_185490" 267 "WakeupReasons_4471" 268 "WakeupReasons_269034" 269 "WakeupReasons_215560" 270 "WakeupReasons_312881" 271 "WakeupReasons_269140" 272 "WakeupReasons_197653" 273 "WakeupReasons_337991" 274 "WakeupReasons_658188" 275 "WakeupReasons_674953" 276 "WakeupReasons_675064" 277 "WakeupReasons_674958" 278 "WakeupReasons_675494" 279 "WakeupReasons_675837" 280 "WakeupReasons_667879" 281 "WakeupReasons_667947" 282 "WakeupReasons_676265" 283 "WakeupReasons_669465" 284 "WakeupReasons_670928" 285 "WakeupReasons_669447" 286 "WakeupReasons_667922" 287 "WakeupReasons_670753" 288 "WakeupReasons_668395" 289 "WakeupReasons_668393" 290 "WakeupReasons_667850" 291 "WakeupReasons_667848" 292 "WakeupReasons_311279" 293 "WakeupReasons_182918" 294 "WakeupReasons_667988" 295 "WakeupReasons_532555" 296 "WakeupReasons_532556" 297 "WakeupReasons_113348" 298 "WakeupReasons_193474" 299 "WakeupReasons_667871" 300 "WakeupReasons_670966" 301 "WakeupReasons_667985" 302 "WakeupReasons_670354" 303 "WakeupReasons_46017" 304 "WakeupReasons_675742" 305 "WakeupReasons_106669" 306 "WakeupReasons_80609" 307 "WakeupReasons_199714" 308 "WakeupReasons_200090" 309 "WakeupReasons_139075" 310 "WakeupReasons_268983" 311 "WakeupReasons_265131" 312 "WakeupReasons_263473" 313 "WakeupReasons_45887" 314 "WakeupReasons_69678" 315 "WakeupReasons_69679" 316 "WakeupReasons_45897" 317 "WakeupReasons_45898" 318 "WakeupReasons_80608" 319 "WakeupReasons_45869" 320 "WakeupReasons_45870" 321 "WakeupReasons_45872" 322 "WakeupReasons_45875" 323 "WakeupReasons_45871" 324 "WakeupReasons_45876" 325 "WakeupReasons_667980" 326 "WakeupReasons_45877" 327 "WakeupReasons_667973" 328 "WakeupReasons_670962" 329 "WakeupReasons_45888" 330 "WakeupReasons_45890" 331 "WakeupReasons_667869" 332 "WakeupReasons_45846" 333 "WakeupReasons_45847" 334 "WakeupReasons_45848" 335 "WakeupReasons_262872" 336 "WakeupReasons_127924" 337 "WakeupReasons_127926" 338 "WakeupReasons_674223" 339 "WakeupReasons_667982" 340 "WakeupReasons_657121" 341 "WakeupReasons_265745" 342 "WakeupReasons_657120" 343 "WakeupReasons_675564" 344 "WakeupReasons_197644" 345 "WakeupReasons_264943" 346 "WakeupReasons_264697" 347 "WakeupReasons_69216" 348 "WakeupReasons_128671" 349 "WakeupReasons_356598" 350 "WakeupReasons_675745" 351 "WakeupReasons_667983" 352 "WakeupReasons_667987" 353 "WakeupReasons_75103" 354 "WakeupReasons_305818" 355 "WakeupReasons_670942" 356 "WakeupReasons_532932" 357 "WakeupReasons_532933" 358 "WakeupReasons_83199" 359 "WakeupReasons_45900" 360 "WakeupReasons_88458" 361 "WakeupReasons_329457" 362 "WakeupReasons_45902" 363 "WakeupReasons_224211" 364 "WakeupReasons_667981" 365 "WakeupReasons_667874" 366 "WakeupReasons_46020" 367 "WakeupReasons_667842" 368 "WakeupReasons_145161" 369 "WakeupReasons_233755" 370 "WakeupReasons_297056" 371 "WakeupReasons_264691" 372 "WakeupReasons_262871" 373 "WakeupReasons_264964" 374 "WakeupReasons_667872" 375 "WakeupReasons_45655" 376 "WakeupReasons_177214" 377 "WakeupReasons_671005" 378 "WakeupReasons_680712" 379 "WakeupReasons_669822" 380 "WakeupReasons_668523" 381 "WakeupReasons_680974" 382 "WakeupReasons_680975" 383 "WakeupReasons_681028" 384 "WakeupReasons_670462" 385 "WakeupReasons_681134" 386 "WakeupReasons_681031" 387 "WakeupReasons_681711" 388 "WakeupReasons_682034" 389 "WakeupReasons_674839" 390 "WakeupReasons_681915" 391 "WakeupReasons_682032" 392 "WakeupReasons_682037" 393 "WakeupReasons_682688" 394 "WakeupReasons_681789" 395 "WakeupReasons_682023" 396 "WakeupReasons_681023" 397 "WakeupReasons_676285" 398 "WakeupReasons_682077" 399 "WakeupReasons_682076" 400 "WakeupReasons_682078" 401 "WakeupReasons_682153" 402 "WakeupReasons_682155" 403 "WakeupReasons_682152" 404 "WakeupReasons_682154" 405 "WakeupReasons_682074";
VAL_ 1345 VFCVectorASDMVFCid0 0 "VFCOnOff_Off" 1 "VFCOnOff_On";
VAL_ 1345 VFCVectorASDMVFCid1 0 "VFCOnOff_Off" 1 "VFCOnOff_On";
VAL_ 1345 VFCVectorASDMVFCid10 0 "VFCOnOff_Off" 1 "VFCOnOff_On";
VAL_ 1345 VFCVectorASDMVFCid11 0 "VFCOnOff_Off" 1 "VFCOnOff_On";
VAL_ 1345 VFCVectorASDMVFCid12 0 "VFCOnOff_Off" 1 "VFCOnOff_On";
VAL_ 1345 VFCVectorASDMVFCid13 0 "VFCOnOff_Off" 1 "VFCOnOff_On";
VAL_ 1345 VFCVectorASDMVFCid14 0 "VFCOnOff_Off" 1 "VFCOnOff_On";
VAL_ 1345 VFCVectorASDMVFCid15 0 "VFCOnOff_Off" 1 "VFCOnOff_On";
VAL_ 1345 VFCVectorASDMVFCid16 0 "VFCOnOff_Off" 1 "VFCOnOff_On";
VAL_ 1345 VFCVectorASDMVFCid17 0 "VFCOnOff_Off" 1 "VFCOnOff_On";
VAL_ 1345 VFCVectorASDMVFCid18 0 "VFCOnOff_Off" 1 "VFCOnOff_On";
VAL_ 1345 VFCVectorASDMVFCid19 0 "VFCOnOff_Off" 1 "VFCOnOff_On";
VAL_ 1345 VFCVectorASDMVFCid2 0 "VFCOnOff_Off" 1 "VFCOnOff_On";
VAL_ 1345 VFCVectorASDMVFCid20 0 "VFCOnOff_Off" 1 "VFCOnOff_On";
VAL_ 1345 VFCVectorASDMVFCid21 0 "VFCOnOff_Off" 1 "VFCOnOff_On";
VAL_ 1345 VFCVectorASDMVFCid22 0 "VFCOnOff_Off" 1 "VFCOnOff_On";
VAL_ 1345 VFCVectorASDMVFCid23 0 "VFCOnOff_Off" 1 "VFCOnOff_On";
VAL_ 1345 VFCVectorASDMVFCid24 0 "VFCOnOff_Off" 1 "VFCOnOff_On";
VAL_ 1345 VFCVectorASDMVFCid25 0 "VFCOnOff_Off" 1 "VFCOnOff_On";
VAL_ 1345 VFCVectorASDMVFCid26 0 "VFCOnOff_Off" 1 "VFCOnOff_On";
VAL_ 1345 VFCVectorASDMVFCid27 0 "VFCOnOff_Off" 1 "VFCOnOff_On";
VAL_ 1345 VFCVectorASDMVFCid28 0 "VFCOnOff_Off" 1 "VFCOnOff_On";
VAL_ 1345 VFCVectorASDMVFCid29 0 "VFCOnOff_Off" 1 "VFCOnOff_On";
VAL_ 1345 VFCVectorASDMVFCid3 0 "VFCOnOff_Off" 1 "VFCOnOff_On";
VAL_ 1345 VFCVectorASDMVFCid30 0 "VFCOnOff_Off" 1 "VFCOnOff_On";
VAL_ 1345 VFCVectorASDMVFCid31 0 "VFCOnOff_Off" 1 "VFCOnOff_On";
VAL_ 1345 VFCVectorASDMVFCid32 0 "VFCOnOff_Off" 1 "VFCOnOff_On";
VAL_ 1345 VFCVectorASDMVFCid33 0 "VFCOnOff_Off" 1 "VFCOnOff_On";
VAL_ 1345 VFCVectorASDMVFCid34 0 "VFCOnOff_Off" 1 "VFCOnOff_On";
VAL_ 1345 VFCVectorASDMVFCid35 0 "VFCOnOff_Off" 1 "VFCOnOff_On";
VAL_ 1345 VFCVectorASDMVFCid36 0 "VFCOnOff_Off" 1 "VFCOnOff_On";
VAL_ 1345 VFCVectorASDMVFCid37 0 "VFCOnOff_Off" 1 "VFCOnOff_On";
VAL_ 1345 VFCVectorASDMVFCid38 0 "VFCOnOff_Off" 1 "VFCOnOff_On";
VAL_ 1345 VFCVectorASDMVFCid39 0 "VFCOnOff_Off" 1 "VFCOnOff_On";
VAL_ 1345 VFCVectorASDMVFCid4 0 "VFCOnOff_Off" 1 "VFCOnOff_On";
VAL_ 1345 VFCVectorASDMVFCid40 0 "VFCOnOff_Off" 1 "VFCOnOff_On";
VAL_ 1345 VFCVectorASDMVFCid41 0 "VFCOnOff_Off" 1 "VFCOnOff_On";
VAL_ 1345 VFCVectorASDMVFCid42 0 "VFCOnOff_Off" 1 "VFCOnOff_On";
VAL_ 1345 VFCVectorASDMVFCid43 0 "VFCOnOff_Off" 1 "VFCOnOff_On";
VAL_ 1345 VFCVectorASDMVFCid44 0 "VFCOnOff_Off" 1 "VFCOnOff_On";
VAL_ 1345 VFCVectorASDMVFCid45 0 "VFCOnOff_Off" 1 "VFCOnOff_On";
VAL_ 1345 VFCVectorASDMVFCid46 0 "VFCOnOff_Off" 1 "VFCOnOff_On";
VAL_ 1345 VFCVectorASDMVFCid47 0 "VFCOnOff_Off" 1 "VFCOnOff_On";
VAL_ 1345 VFCVectorASDMVFCid48 0 "VFCOnOff_Off" 1 "VFCOnOff_On";
VAL_ 1345 VFCVectorASDMVFCid49 0 "VFCOnOff_Off" 1 "VFCOnOff_On";
VAL_ 1345 VFCVectorASDMVFCid5 0 "VFCOnOff_Off" 1 "VFCOnOff_On";
VAL_ 1345 VFCVectorASDMVFCid50 0 "VFCOnOff_Off" 1 "VFCOnOff_On";
VAL_ 1345 VFCVectorASDMVFCid51 0 "VFCOnOff_Off" 1 "VFCOnOff_On";
VAL_ 1345 VFCVectorASDMVFCid52 0 "VFCOnOff_Off" 1 "VFCOnOff_On";
VAL_ 1345 VFCVectorASDMVFCid53 0 "VFCOnOff_Off" 1 "VFCOnOff_On";
VAL_ 1345 VFCVectorASDMVFCid54 0 "VFCOnOff_Off" 1 "VFCOnOff_On";
VAL_ 1345 VFCVectorASDMVFCid55 0 "VFCOnOff_Off" 1 "VFCOnOff_On";
VAL_ 1345 VFCVectorASDMVFCid56 0 "VFCOnOff_Off" 1 "VFCOnOff_On";
VAL_ 1345 VFCVectorASDMVFCid57 0 "VFCOnOff_Off" 1 "VFCOnOff_On";
VAL_ 1345 VFCVectorASDMVFCid58 0 "VFCOnOff_Off" 1 "VFCOnOff_On";
VAL_ 1345 VFCVectorASDMVFCid59 0 "VFCOnOff_Off" 1 "VFCOnOff_On";
VAL_ 1345 VFCVectorASDMVFCid6 0 "VFCOnOff_Off" 1 "VFCOnOff_On";
VAL_ 1345 VFCVectorASDMVFCid60 0 "VFCOnOff_Off" 1 "VFCOnOff_On";
VAL_ 1345 VFCVectorASDMVFCid61 0 "VFCOnOff_Off" 1 "VFCOnOff_On";
VAL_ 1345 VFCVectorASDMVFCid7 0 "VFCOnOff_Off" 1 "VFCOnOff_On";
VAL_ 1345 VFCVectorASDMVFCid8 0 "VFCOnOff_Off" 1 "VFCOnOff_On";
VAL_ 1345 VFCVectorASDMVFCid9 0 "VFCOnOff_Off" 1 "VFCOnOff_On";
VAL_ 257 AbsCtrlActvCtrlSts1 0 "CtrlSts1_NoCtrl" 1 "CtrlSts1_InCtrl";
VAL_ 257 AsyALgtCtrlModCfmdAsyALgtCtrlMod1 0 "AsyALgtCtrlMod_NoReq" 10 "AsyALgtCtrlMod_PEB" 11 "AsyALgtCtrlMod_APA" 12 "AsyALgtCtrlMod_RPA" 13 "AsyALgtCtrlMod_HPA";
VAL_ 257 AutHldAvlSt 0 "AvlSts2_NotAvl" 1 "AvlSts2_Avl";
VAL_ 257 BrkTqQf 0 "Qf1_DevOfDataUndefd" 1 "Qf1_DataTmpUndefdAndEvlnInProgs" 2 "Qf1_DevOfDataNotWithinRngAllwd" 3 "Qf1_DataCalcdWithDevDefd";
VAL_ 257 BrkTqSts 0 "BrkSts_NoBrake" 1 "BrkSts_Brake";
VAL_ 257 DrvrBrkTqAtWhlsReqdQf 0 "GenQf1_UndefindDataAccur" 1 "GenQf1_TmpUndefdData" 2 "GenQf1_DataAccurNotWithinSpcn" 3 "GenQf1_AccurData";
VAL_ 257 FricEstimnFromVehDynQly 0 "Qly3_De0" 1 "Qly3_De1" 2 "Qly3_De2" 3 "Qly3_De3" 4 "Qly3_De4" 5 "Qly3_De5" 6 "Qly3_De6" 7 "Qly3_De7";
VAL_ 257 LatCtrlReqSafeLatCtrlModReq 0 "LatCtrlMod1_NoReq" 1 "LatCtrlMod1_HighWayAssist" 2 "LatCtrlMod1_EmgyLaneKeepAidForObjRe" 3 "LatCtrlMod1_EmgyLaneKeepAidForStat" 4 "LatCtrlMod1_SftyLaneKeepAid" 5 "LatCtrlMod1_SteerAssc" 6 "LatCtrlMod1_DsrOversteer" 7 "LatCtrlMod1_DsrMueSplit" 8 "LatCtrlMod1_DsrTrlrStaby" 9 "LatCtrlMod1_EmgyManvAssi" 10 "LatCtrlMod1_Reserved1" 11 "LatCtrlMod1_Reserved2" 12 "LatCtrlMod1_SHWA" 13 "LatCtrlMod1_APA" 14 "LatCtrlMod1_RPA" 15 "LatCtrlMod1_HPA";
VAL_ 257 LatCtrlReqSafeSteerWhlHptcWarnReq 0 "OnOff1_Off" 1 "OnOff1_On";
VAL_ 257 LgtCtrlModReqSafeLgtCtrlModReqSafe 0 "ModCfmd_NoReq" 1 "ModCfmd_E2E" 2 "ModCfmd_Reserved2" 3 "ModCfmd_Reserved3" 4 "ModCfmd_Reserved4" 5 "ModCfmd_Reserved5" 6 "ModCfmd_Reserved6" 7 "ModCfmd_Reserved7" 8 "ModCfmd_Reserved8" 9 "ModCfmd_ACC_HWA" 10 "ModCfmd_PEB" 11 "ModCfmd_APA" 12 "ModCfmd_RPA" 13 "ModCfmd_HPA" 14 "ModCfmd_TJP_HWC" 15 "ModCfmd_NOP";
VAL_ 257 LgtCtrlModReqSafeLgtFctFailr 0 "LgtFctFail_NoFailure" 1 "LgtFctFail_TJP_HWCFailure" 2 "LgtFctFail_APAFailure" 3 "LgtFctFail_RPAFailure" 4 "LgtFctFail_HPAFailure" 5 "LgtFctFail_HWAFailure" 6 "LgtFctFail_NOPFailure" 7 "LgtFctFail_E2EFailure";
VAL_ 257 StcStsToDmcFrnt 0 "ModeDMC_Off" 1 "ModeDMC_Rpm" 2 "ModeDMC_Trq";
VAL_ 257 StcStsToDmcRear 0 "ModeDMC_Off" 1 "ModeDMC_Rpm" 2 "ModeDMC_Trq";
VAL_ 257 SteerAssiCtrlSts 0 "Offrdcrzstate_undefined" 1 "Offrdcrzstate_off" 2 "Offrdcrzstate_standby" 3 "Offrdcrzstate_active";
VAL_ 257 TqRednDurgCllsnMtgtnByBrkg 0 "TqRednDurgBrk_NoTqRednReqd" 1 "TqRednDurgBrk_TqRednDurgPreBrk" 2 "TqRednDurgBrk_TqRednDurgBrkFull" 3 "TqRednDurgBrk_Resd3";
VAL_ 1025 AbsCtrlActvForWhlFrntLe 0 "CtrlSts1_NoCtrl" 1 "CtrlSts1_InCtrl";
VAL_ 1025 AbsCtrlActvForWhlFrntRi 0 "CtrlSts1_NoCtrl" 1 "CtrlSts1_InCtrl";
VAL_ 1025 AbsCtrlActvForWhlReLe 0 "CtrlSts1_NoCtrl" 1 "CtrlSts1_InCtrl";
VAL_ 1025 AbsCtrlActvForWhlReRi 0 "CtrlSts1_NoCtrl" 1 "CtrlSts1_InCtrl";
VAL_ 1025 ALgtStdFromWhlSpdQf 0 "GenQf1_UndefindDataAccur" 1 "GenQf1_TmpUndefdData" 2 "GenQf1_DataAccurNotWithinSpcn" 3 "GenQf1_AccurData";
VAL_ 1025 PitchAgGlbQf 0 "Qly2_Flt" 1 "Qly2_NoInfo" 2 "Qly2_Vld";
VAL_ 1025 RoadLoadNomCoeffSts 0 "Boolean_FALSE" 1 "Boolean_TRUE";
VAL_ 1025 StandStillMgrStsForHldByBrkStandStillMgrStsForHld1 0 "StandStillMgrStsForHld1_StandStillMgrStsForHldVal0" 1 "StandStillMgrStsForHld1_StandStillMgrStsForHldVal1" 2 "StandStillMgrStsForHld1_StandStillMgrStsForHldVal2" 3 "StandStillMgrStsForHld1_StandStillMgrStsForHldVal3" 4 "StandStillMgrStsForHld1_StandStillMgrStsForHldVal4" 5 "StandStillMgrStsForHld1_StandStillMgrStsForHldVal5" 6 "StandStillMgrStsForHld1_StandStillMgrStsForHldVal6" 7 "StandStillMgrStsForHld1_StandStillMgrStsForHldVal7";
VAL_ 1025 StandStillMgrStsForPark 0 "StandStillMgrStsForPark1_ParkNotReqd" 1 "StandStillMgrStsForPark1_ParkReqdByDrvr" 2 "StandStillMgrStsForPark1_ParkReqdAutByHldTiExcd" 3 "StandStillMgrStsForPark1_ParkReqdAut";
VAL_ 1025 TrlrModBCSts 0 "ModSts2_Init" 1 "ModSts2_ExtErr" 2 "ModSts2_IntErr" 3 "ModSts2_Cfmd";
VAL_ 1025 YawStabyCtrlActv 0 "CtrlSts1_NoCtrl" 1 "CtrlSts1_InCtrl";
VAL_ 483 AbsSts 0 "DevErrSts2_NoFlt" 1 "DevErrSts2_Flt";
VAL_ 483 AsyActrActvForLgtCtrl 0 "ActrActvForLgtCtrl_ActrNotEnadForCmft" 1 "ActrActvForLgtCtrl_PrpsnActrEnadForCmft" 2 "ActrActvForLgtCtrl_BrkActrEnadForCmft";
VAL_ 483 AsySftyDecelEnadByVehDyn 0 "AsySftyDecelEnadByVehDyn1_AsyBrkgNotAllwd" 1 "AsySftyDecelEnadByVehDyn1_AsyBrkgAllwd";
VAL_ 483 AsySftyEnaDecelAckd 0 "OnOff1_Off" 1 "OnOff1_On";
VAL_ 483 BrkPedlrRatQf 0 "GenQf1_UndefindDataAccur" 1 "GenQf1_TmpUndefdData" 2 "GenQf1_DataAccurNotWithinSpcn" 3 "GenQf1_AccurData";
VAL_ 483 EscActvCtrlIndcdToDrvr 0 "NoYes1_No" 1 "NoYes1_Yes";
VAL_ 483 HsaSt 0 "YesNo2_No" 1 "YesNo2_Yes";
VAL_ 483 InhbOfAsySftyDecelByVehDyn 0 "InhbOfAsySftyDecelByVehDyn1_AsySftyBrkgNotDendByBrk" 1 "InhbOfAsySftyDecelByVehDyn1_AsySftyBrkgDendByBrk";
VAL_ 483 LimForDecelNotExcd 0 "NoYes1_No" 1 "NoYes1_Yes";
VAL_ 483 MsgReqByHillDwnCtrl 0 "MsgReqByHillDwnCtrl1_MsgForHillDwnCtrlNotReqd" 1 "MsgReqByHillDwnCtrl1_MsgForHillDwnCtrlOnReqd" 2 "MsgReqByHillDwnCtrl1_MsgForHillDwnCtrlReqdForBrkg" 3 "MsgReqByHillDwnCtrl1_MsgForHillDwnCtrlTmpOffReqd" 4 "MsgReqByHillDwnCtrl1_Resd4" 5 "MsgReqByHillDwnCtrl1_Resd5" 6 "MsgReqByHillDwnCtrl1_Resd6" 7 "MsgReqByHillDwnCtrl1_Resd7";
VAL_ 483 RctaBrkActvd 0 "NoYes1_No" 1 "NoYes1_Yes";
VAL_ 483 RcwmBrkActvd 0 "NoYes1_No" 1 "NoYes1_Yes";
VAL_ 483 SuspPosnVertAgGenQf 0 "GenQf1_UndefindDataAccur" 1 "GenQf1_TmpUndefdData" 2 "GenQf1_DataAccurNotWithinSpcn" 3 "GenQf1_AccurData";
VAL_ 483 SuspPosnVertLvlFrntQf 0 "GenQf1_UndefindDataAccur" 1 "GenQf1_TmpUndefdData" 2 "GenQf1_DataAccurNotWithinSpcn" 3 "GenQf1_AccurData";
VAL_ 483 SuspPosnVertLvlReQf 0 "GenQf1_UndefindDataAccur" 1 "GenQf1_TmpUndefdData" 2 "GenQf1_DataAccurNotWithinSpcn" 3 "GenQf1_AccurData";
VAL_ 483 WhlBrkOvrheatd 0 "TSts1_Norm" 1 "TSts1_Ovrheatd";
VAL_ 816 AbsClrRdyReq 0 "OnOff1_Off" 1 "OnOff1_On";
VAL_ 816 BrkTracCtrlActvForWhlFrntLe 0 "CtrlSts1_NoCtrl" 1 "CtrlSts1_InCtrl";
VAL_ 816 BrkTracCtrlActvForWhlFrntRi 0 "CtrlSts1_NoCtrl" 1 "CtrlSts1_InCtrl";
VAL_ 816 BrkTracCtrlActvForWhlReLe 0 "CtrlSts1_NoCtrl" 1 "CtrlSts1_InCtrl";
VAL_ 816 BrkTracCtrlActvForWhlReRi 0 "CtrlSts1_NoCtrl" 1 "CtrlSts1_InCtrl";
VAL_ 816 EpbLampReqEpbLampReq 0 "EpbLampReqType1_On" 1 "EpbLampReqType1_Off" 2 "EpbLampReqType1_Flash2" 3 "EpbLampReqType1_Flash3";
VAL_ 816 RollAgGlbQf 0 "Qly2_Flt" 1 "Qly2_NoInfo" 2 "Qly2_Vld";
VAL_ 800 AbsErrIndcnReq 0 "OnOff1_Off" 1 "OnOff1_On";
VAL_ 800 PostImpctBrkgRdy 0 "PostImpctBrkgRdy_No" 1 "PostImpctBrkgRdy_Yes" 2 "PostImpctBrkgRdy_Di" 3 "PostImpctBrkgRdy_Resd";
VAL_ 800 WhlBrkWrm 0 "NoYes1_No" 1 "NoYes1_Yes";
VAL_ 384 BrkPedlPsdBrkPedlNotPsdSafe 0 "NoYes1_No" 1 "NoYes1_Yes";
VAL_ 384 BrkPedlPsdBrkPedlPsd 0 "NoYes1_No" 1 "NoYes1_Yes";
VAL_ 384 BrkPedlPsdQf 0 "GenQf1_UndefindDataAccur" 1 "GenQf1_TmpUndefdData" 2 "GenQf1_DataAccurNotWithinSpcn" 3 "GenQf1_AccurData";
VAL_ 384 BrkPedlTrvlQf 0 "GenQf1_UndefindDataAccur" 1 "GenQf1_TmpUndefdData" 2 "GenQf1_DataAccurNotWithinSpcn" 3 "GenQf1_AccurData";
VAL_ 384 BrkPedlTrvlSt 0 "PsdNotPsd_NotPsd" 1 "PsdNotPsd_Psd";
VAL_ 384 BrkPedlTrvlStQf 0 "GenQf1_UndefindDataAccur" 1 "GenQf1_TmpUndefdData" 2 "GenQf1_DataAccurNotWithinSpcn" 3 "GenQf1_AccurData";
VAL_ 384 BrkSysCylPMstActQf 0 "GenQf1_UndefindDataAccur" 1 "GenQf1_TmpUndefdData" 2 "GenQf1_DataAccurNotWithinSpcn" 3 "GenQf1_AccurData";
VAL_ 384 BrkSysCylPMstVirtQf 0 "GenQf1_UndefindDataAccur" 1 "GenQf1_TmpUndefdData" 2 "GenQf1_DataAccurNotWithinSpcn" 3 "GenQf1_AccurData";
VAL_ 384 EngRunngReqByBrk 0 "EngRunngReq_Dft" 1 "EngRunngReq_StopInhb" 2 "EngRunngReq_RunReq" 3 "EngRunngReq_Resd";
VAL_ 384 EpbActrStPrim 0 "AppRel_Applied" 1 "AppRel_Released" 2 "AppRel_Applying" 3 "AppRel_Releasing" 4 "AppRel_Unknown" 5 "AppRel_HoldApplied" 6 "AppRel_CompletelyReleased" 7 "AppRel_HapPrepared";
VAL_ 384 EpbStsEpbSts 0 "EpbSts_Resd0" 1 "EpbSts_Resd1" 2 "EpbSts_Resd2" 3 "EpbSts_AllAppld" 4 "EpbSts_Resd4" 5 "EpbSts_AllInTran" 6 "EpbSts_BrkgDynByActr" 7 "EpbSts_Resd7" 8 "EpbSts_Resd8" 9 "EpbSts_ActrAllReld" 10 "EpbSts_BrkgDynDegraded" 11 "EpbSts_Resd11" 12 "EpbSts_BrkgDyn" 13 "EpbSts_Resd13" 14 "EpbSts_Resd14" 15 "EpbSts_Err";
VAL_ 384 EscCtrlIndcn 0 "DevSts1_On" 1 "DevSts1_Off" 2 "DevSts1_Flt";
VAL_ 384 EscGearShiftInhbReq 0 "EscGearShiftInhbReq_GearShiftNotInhb" 1 "EscGearShiftInhbReq_GearShiftInhb" 2 "EscGearShiftInhbReq_UpShiftInhb" 3 "EscGearShiftInhbReq_InhbShiftDwn";
VAL_ 384 EscStEscSt 0 "EscSt1_Inin" 1 "EscSt1_Ok" 2 "EscSt1_TmpErr" 3 "EscSt1_PrmntErr" 4 "EscSt1_UsrOff";
VAL_ 384 LimForJerkPosNotExcdLimForJerkPosNotExcd 0 "NoYes1_No" 1 "NoYes1_Yes";
VAL_ 384 RoadInclnQly 0 "Qly2_Flt" 1 "Qly2_NoInfo" 2 "Qly2_Vld";
VAL_ 608 AutoShowModBCEna 0 "OkNotOk_NotOk" 1 "OkNotOk_Ok";
VAL_ 608 EpbDrvrDisp 0 "EpbDrvrDisp_Msg0" 1 "EpbDrvrDisp_Resd1" 2 "EpbDrvrDisp_Resd2" 3 "EpbDrvrDisp_Msg3" 4 "EpbDrvrDisp_Msg4" 5 "EpbDrvrDisp_Msg5" 6 "EpbDrvrDisp_Msg6" 7 "EpbDrvrDisp_Resd7" 8 "EpbDrvrDisp_Msg8" 9 "EpbDrvrDisp_Resd9" 10 "EpbDrvrDisp_Msg10" 11 "EpbDrvrDisp_Msg11" 12 "EpbDrvrDisp_Msg12" 13 "EpbDrvrDisp_Msg13" 14 "EpbDrvrDisp_Msg14" 15 "EpbDrvrDisp_Msg15";
VAL_ 997 DstTrvldVldFromBrkBkp 0 "InvldVld1_Invld" 1 "InvldVld1_Vld";
VAL_ 997 EmgyBrkLiReqEmgyBrk 0 "EblReq_EmgyBrkgNotInProgs" 1 "EblReq_EmgyBrkgInProgs" 2 "EblReq_EmgyBrkgInProgsAtSpdLo";
VAL_ 997 EPBLockChkChk 0 "AvlSts2_NotAvl" 1 "AvlSts2_Avl";
VAL_ 997 EPBLockSts 0 "TrsmLockSts_Undefd" 1 "TrsmLockSts_Unlocked" 2 "TrsmLockSts_Lockd" 3 "TrsmLockSts_Resd";
VAL_ 997 IndcnToDrvrPostImpctCtrl 0 "IndcnToDrvrPostImpctCtrl2_MsgNotRqrdForPostImpctCtrl" 1 "IndcnToDrvrPostImpctCtrl2_IntvReqdByPostImpctCtrl";
VAL_ 997 SteerAssiAvlSts 0 "AvlSts1_TmpNotAvl" 1 "AvlSts1_PrmntNotAvl" 2 "AvlSts1_Avl";
VAL_ 997 SteerAssiWarnMsg 0 "BrkMsgWarn1_NoReq" 1 "BrkMsgWarn1_Msg1" 2 "BrkMsgWarn1_Msg2" 3 "BrkMsgWarn1_Msg3" 4 "BrkMsgWarn1_Msg4" 5 "BrkMsgWarn1_Msg5" 6 "BrkMsgWarn1_Msg6" 7 "BrkMsgWarn1_Msg7";
VAL_ 997 VBFAvlSts 0 "AvlSts2_NotAvl" 1 "AvlSts2_Avl";
VAL_ 1040 BrkBoostClrRdyReq 0 "OnOff1_Off" 1 "OnOff1_On";
VAL_ 576 BrkSysStsADL3BrkFallBck 0 "Primary" 1 "Secondary";
VAL_ 576 BrkSysStsBrkDegradation 0 "NoDegradation_Green" 1 "LgtFailr_Red" 2 "AbsEscTemporarilyOff_Yellow" 3 "EscServiceRequired_Yellow" 4 "EscTemporarilyOff_Yellow" 5 "StcTemporarilyOff_Yellow" 6 "EpbFailr_Yellow" 7 "Reserved0" 8 "Reserved1" 9 "Reserved2" 10 "Reserved3" 11 "BrkDegrad_GeneralBrakeFailureYellow" 12 "Reserved5" 13 "Reserved6" 14 "Reserved7" 15 "Reserved8";
VAL_ 576 BrkSysStsBrkSysCapability 0 "NotInitialized" 1 "Full" 2 "TestPending" 3 "Fault";
VAL_ 576 BrkSysStsBrkSysModCfmd 0 "ModCfmd_NoReq" 1 "ModCfmd_E2E" 2 "ModCfmd_Reserved2" 3 "ModCfmd_Reserved3" 4 "ModCfmd_Reserved4" 5 "ModCfmd_Reserved5" 6 "ModCfmd_Reserved6" 7 "ModCfmd_Reserved7" 8 "ModCfmd_Reserved8" 9 "ModCfmd_ACC_HWA" 10 "ModCfmd_PEB" 11 "ModCfmd_APA" 12 "ModCfmd_RPA" 13 "ModCfmd_HPA" 14 "ModCfmd_TJP_HWC" 15 "ModCfmd_NOP";
VAL_ 576 EscWarnIndcnReqEscWarnIndcnReq 0 "EscWarnIndcnReq_EscWarnIndcnOnReq" 1 "EscWarnIndcnReq_EscWarnIndcnFlsgReq" 2 "EscWarnIndcnReq_Resd2" 3 "EscWarnIndcnReq_EscWarnIndcnOffReq";
VAL_ 576 LampReqByVehHld 0 "DevSts4_Off" 1 "DevSts4_On" 2 "DevSts4_Err" 3 "DevSts4_Resd";
VAL_ 949 AutHldSoftSwtEnaSts 0 "OnOff1_Off" 1 "OnOff1_On";
VAL_ 949 BrkAndAbsWarnIndcnReqAbsWarnIndcnReq 0 "AbsWarnIndcnReq_AbsWarnIndcnOnReq" 1 "AbsWarnIndcnReq_AbsWarnIndcnFlsgReq" 2 "AbsWarnIndcnReq_Resd2" 3 "AbsWarnIndcnReq_AbsWarnIndcnOffReq";
VAL_ 949 BrkAndAbsWarnIndcnReqBrkWarnIndcnReq 0 "OnOff2_On" 1 "OnOff2_Off";
VAL_ 949 BrkBoostErrIndcnReq 0 "OnOff1_Off" 1 "OnOff1_On";
VAL_ 949 BrkByWireWarnIndcn 0 "OnOff2_On" 1 "OnOff2_Off";
VAL_ 949 BrkFldLvl 0 "FldLvl_FldLvlHi" 1 "FldLvl_FldLvlLo";
VAL_ 949 BrkMsgForHybWarnReq 0 "BrkMsgWarn1_NoReq" 1 "BrkMsgWarn1_Msg1" 2 "BrkMsgWarn1_Msg2" 3 "BrkMsgWarn1_Msg3" 4 "BrkMsgWarn1_Msg4" 5 "BrkMsgWarn1_Msg5" 6 "BrkMsgWarn1_Msg6" 7 "BrkMsgWarn1_Msg7";
VAL_ 949 BrkMsgForLoVacReqd 0 "NoYes1_No" 1 "NoYes1_Yes";
VAL_ 949 BrkMsgWarnReq 0 "BrkMsgWarn1_NoReq" 1 "BrkMsgWarn1_Msg1" 2 "BrkMsgWarn1_Msg2" 3 "BrkMsgWarn1_Msg3" 4 "BrkMsgWarn1_Msg4" 5 "BrkMsgWarn1_Msg5" 6 "BrkMsgWarn1_Msg6" 7 "BrkMsgWarn1_Msg7";
VAL_ 949 BrkMsgWarnReqForHmi 0 "BrkMsgWarn1_NoReq" 1 "BrkMsgWarn1_Msg1" 2 "BrkMsgWarn1_Msg2" 3 "BrkMsgWarn1_Msg3" 4 "BrkMsgWarn1_Msg4" 5 "BrkMsgWarn1_Msg5" 6 "BrkMsgWarn1_Msg6" 7 "BrkMsgWarn1_Msg7" 8 "BrkMsgWarn1_Msg8" 9 "BrkMsgWarn1_Msg9" 10 "BrkMsgWarn1_Msg10" 11 "BrkMsgWarn1_Msg11" 12 "BrkMsgWarn1_Msg12" 13 "BrkMsgWarn1_Msg13" 14 "BrkMsgWarn1_Msg14" 15 "BrkMsgWarn1_Msg15";
VAL_ 949 BrkRelsWarnReq 0 "NoYes1_No" 1 "NoYes1_Yes";
VAL_ 949 BrkSysWarnIndcnReq 0 "OnOff2_On" 1 "OnOff2_Off";
VAL_ 949 CstCtrlActvCstCtrlEab 0 "YesNo2_No" 1 "YesNo2_Yes";
VAL_ 949 CstCtrlActvCtrlSts1 0 "CtrlSts1_NoCtrl" 1 "CtrlSts1_InCtrl";
VAL_ 949 DispMsgByVehHld 1 "AutHldDrvrDisp_Msg1" 2 "AutHldDrvrDisp_Msg2" 3 "AutHldDrvrDisp_Msg3" 4 "AutHldDrvrDisp_Msg4" 5 "AutHldDrvrDisp_Err";
VAL_ 949 DrvModEscOffDrvModEscOff 0 "YesNo2_No" 1 "YesNo2_Yes";
VAL_ 949 EpbApplyEna 0 "YesNo2_No" 1 "YesNo2_Yes";
VAL_ 949 EpbRelsEna 0 "YesNo2_No" 1 "YesNo2_Yes";
VAL_ 805 SwtStsforHillDwnCtrl 0 "EnableDisableCoding_Disabled" 1 "EnableDisableCoding_Enabled";
VAL_ 402 AsyLatCtrlModReqGroupCfmdLatCtrlMod 0 "LatCtrlMod1_NoReq" 1 "LatCtrlMod1_HighWayAssist" 2 "LatCtrlMod1_EmgyLaneKeepAidForObjRe" 3 "LatCtrlMod1_EmgyLaneKeepAidForStat" 4 "LatCtrlMod1_SftyLaneKeepAid" 5 "LatCtrlMod1_SteerAssc" 6 "LatCtrlMod1_DsrOversteer" 7 "LatCtrlMod1_DsrMueSplit" 8 "LatCtrlMod1_DsrTrlrStaby" 9 "LatCtrlMod1_EmgyManvAssi" 10 "LatCtrlMod1_Reserved1" 11 "LatCtrlMod1_Reserved2" 12 "LatCtrlMod1_SHWA" 13 "LatCtrlMod1_APA" 14 "LatCtrlMod1_RPA" 15 "LatCtrlMod1_HPA";
VAL_ 402 BrkLiOnReqSts 0 "ReqSts1_NotReqd" 1 "ReqSts1_Reqd";
VAL_ 402 PrkLatLgtFailrPrkLatLgtFailr 0 "PrkLatLgtFail_NoFailure" 1 "PrkLatLgtFail_SteeringFailure" 2 "PrkLatLgtFail_BrakeFailure" 3 "PrkLatLgtFail_PropulsionFailure" 4 "PrkLatLgtFail_RBUFailure" 5 "PrkLatLgtFail_CommunicationFailure" 6 "PrkLatLgtFail_VDSWInternalFailure" 7 "PrkLatLgtFail_RWSFailure";
VAL_ 402 StandStillMgrStsForHld1 0 "StandStillMgrStsForHld1_StandStillMgrStsForHldVal0" 1 "StandStillMgrStsForHld1_StandStillMgrStsForHldVal1" 2 "StandStillMgrStsForHld1_StandStillMgrStsForHldVal2" 3 "StandStillMgrStsForHld1_StandStillMgrStsForHldVal3" 4 "StandStillMgrStsForHld1_StandStillMgrStsForHldVal4" 5 "StandStillMgrStsForHld1_StandStillMgrStsForHldVal5" 6 "StandStillMgrStsForHld1_StandStillMgrStsForHldVal6" 7 "StandStillMgrStsForHld1_StandStillMgrStsForHldVal7";
VAL_ 402 VehMNomTrlrM 0 "TrlrM_Lvl0" 1 "TrlrM_Lvl1" 2 "TrlrM_Lvl2" 3 "TrlrM_Lvl3";
VAL_ 402 VehMNomVehMQly 0 "Qly2_Flt" 1 "Qly2_NoInfo" 2 "Qly2_Vld";
VAL_ 402 VehVLatQf 0 "GenQf1_UndefindDataAccur" 1 "GenQf1_TmpUndefdData" 2 "GenQf1_DataAccurNotWithinSpcn" 3 "GenQf1_AccurData";
VAL_ 402 VehVLgtQf 0 "GenQf1_UndefindDataAccur" 1 "GenQf1_TmpUndefdData" 2 "GenQf1_DataAccurNotWithinSpcn" 3 "GenQf1_AccurData";
VAL_ 402 WhlDirRotlFrntLe 0 "WhlRotlDirStd1_Undefd" 1 "WhlRotlDirStd1_StandStill" 2 "WhlRotlDirStd1_Fwd" 3 "WhlRotlDirStd1_Backw";
VAL_ 402 WhlDirRotlFrntRi 0 "WhlRotlDirStd1_Undefd" 1 "WhlRotlDirStd1_StandStill" 2 "WhlRotlDirStd1_Fwd" 3 "WhlRotlDirStd1_Backw";
VAL_ 402 WhlDirRotlReLe 0 "WhlRotlDirStd1_Undefd" 1 "WhlRotlDirStd1_StandStill" 2 "WhlRotlDirStd1_Fwd" 3 "WhlRotlDirStd1_Backw";
VAL_ 402 WhlDirRotlReRi 0 "WhlRotlDirStd1_Undefd" 1 "WhlRotlDirStd1_StandStill" 2 "WhlRotlDirStd1_Fwd" 3 "WhlRotlDirStd1_Backw";
VAL_ 402 WhlFastSpdSafeQF 0 "GenQf1_UndefindDataAccur" 1 "GenQf1_TmpUndefdData" 2 "GenQf1_DataAccurNotWithinSpcn" 3 "GenQf1_AccurData";
VAL_ 402 WhlSpdCircumlFrntLeQf 0 "GenQf1_UndefindDataAccur" 1 "GenQf1_TmpUndefdData" 2 "GenQf1_DataAccurNotWithinSpcn" 3 "GenQf1_AccurData";
VAL_ 402 WhlSpdCircumlFrntRiQf 0 "GenQf1_UndefindDataAccur" 1 "GenQf1_TmpUndefdData" 2 "GenQf1_DataAccurNotWithinSpcn" 3 "GenQf1_AccurData";
VAL_ 402 WhlSpdCircumlReLeQf 0 "GenQf1_UndefindDataAccur" 1 "GenQf1_TmpUndefdData" 2 "GenQf1_DataAccurNotWithinSpcn" 3 "GenQf1_AccurData";
VAL_ 402 WhlSpdCircumlReRiQf 0 "GenQf1_UndefindDataAccur" 1 "GenQf1_TmpUndefdData" 2 "GenQf1_DataAccurNotWithinSpcn" 3 "GenQf1_AccurData";
VAL_ 98 VehDynCtrlStsForALgtCmftVehDynCtrlStsDend 0 "Flg1_Rst" 1 "Flg1_Set";
VAL_ 98 VehDynCtrlStsForALgtCmftVehDynCtrlStsForBrkActv 0 "Flg1_Rst" 1 "Flg1_Set";
VAL_ 98 VehDynCtrlStsForALgtCmftVehDynCtrlStsForBrkPrecActv 0 "Flg1_Rst" 1 "Flg1_Set";
VAL_ 98 VehDynCtrlStsForALgtCmftVehDynCtrlStsForStandStillMgrForPark 0 "StandStillMgrStsForPark2_ParkNotReqd" 1 "StandStillMgrStsForPark2_ParkReqdByDrvr" 2 "StandStillMgrStsForPark2_ParkReqdAutByHldTiExcd" 3 "StandStillMgrStsForPark2_ParkReqdAut" 4 "StandStillMgrStsForPark2_ParkNotAvl";
VAL_ 98 VehDynCtrlStsForALgtCmftVehDynCtrlStsForWhlBrkWrm 0 "Flg1_Rst" 1 "Flg1_Set";
VAL_ 98 VehDynCtrlStsForALgtCmftVehDynCtrlStsNotEna 0 "Flg1_Rst" 1 "Flg1_Set";
VAL_ 98 VehMtnStVehMtnSt 0 "VehMtnSt2_Ukwn" 1 "VehMtnSt2_StandStillVal1" 2 "VehMtnSt2_StandStillVal2" 3 "VehMtnSt2_StandStillVal3" 4 "VehMtnSt2_RollgFwdVal1" 5 "VehMtnSt2_RollgFwdVal2" 6 "VehMtnSt2_RollgBackwVal1" 7 "VehMtnSt2_RollgBackwVal2";
VAL_ 98 VehSpdLgtQf 0 "GenQf1_UndefindDataAccur" 1 "GenQf1_TmpUndefdData" 2 "GenQf1_DataAccurNotWithinSpcn" 3 "GenQf1_AccurData";
VAL_ 98 WhlVAgrFrntLeQf 0 "GenQf1_UndefindDataAccur" 1 "GenQf1_TmpUndefdData" 2 "GenQf1_DataAccurNotWithinSpcn" 3 "GenQf1_AccurData";
VAL_ 98 WhlVAgrFrntRiQf 0 "GenQf1_UndefindDataAccur" 1 "GenQf1_TmpUndefdData" 2 "GenQf1_DataAccurNotWithinSpcn" 3 "GenQf1_AccurData";
VAL_ 98 WhlVAgrReLeQf 0 "GenQf1_UndefindDataAccur" 1 "GenQf1_TmpUndefdData" 2 "GenQf1_DataAccurNotWithinSpcn" 3 "GenQf1_AccurData";
VAL_ 98 WhlVAgrReRiQf 0 "GenQf1_UndefindDataAccur" 1 "GenQf1_TmpUndefdData" 2 "GenQf1_DataAccurNotWithinSpcn" 3 "GenQf1_AccurData";
SIG_GROUP_ 257 AbsCtrlActv 1 : AbsCtrlActvChks AbsCtrlActvCntr AbsCtrlActvCtrlSts1;
SIG_GROUP_ 1025 AbsCtrlActvForWhl 1 : AbsCtrlActvForWhlFrntLe AbsCtrlActvForWhlFrntRi AbsCtrlActvForWhlReLe AbsCtrlActvForWhlReRi;
SIG_GROUP_ 1025 ALgtStdFromWhlSpd 1 : ALgtStdFromWhlSpdALgtStdFromWhlSpd ALgtStdFromWhlSpdChks ALgtStdFromWhlSpdCntr ALgtStdFromWhlSpdQf;
SIG_GROUP_ 257 AsyALgtCtrlModCfmd 1 : AsyALgtCtrlModCfmdAsyALgtCtrlMod1 AsyALgtCtrlModCfmdChks AsyALgtCtrlModCfmdCntr;
SIG_GROUP_ 402 AsyLatCtrlModReqGroupCfmd 1 : AsyLatCtrlModReqGroupCfmdChks AsyLatCtrlModReqGroupCfmdCntr AsyLatCtrlModReqGroupCfmdLatCtrlMod;
SIG_GROUP_ 949 BrkAndAbsWarnIndcnReq 1 : BrkAndAbsWarnIndcnReqAbsWarnIndcnReq BrkAndAbsWarnIndcnReqBrkWarnIndcnReq BrkAndAbsWarnIndcnReqChks BrkAndAbsWarnIndcnReqCntr;
SIG_GROUP_ 257 BrkFricTqAtWhlAct 1 : BrkFricTqAtWhlActBrkFricTqAtWhlFrntLeAct BrkFricTqAtWhlActBrkFricTqAtWhlFrntRiAct BrkFricTqAtWhlActBrkFricTqAtWhlReLeAct BrkFricTqAtWhlActBrkFricTqAtWhlReRiAct;
SIG_GROUP_ 384 BrkFricTqTotAtWhlsAct 1 : BrkFricTqTotAtWhlsActBrkFricTqTotAtWhlsAct BrkFricTqTotAtWhlsActChks BrkFricTqTotAtWhlsActCntr;
SIG_GROUP_ 402 BrkLiOnReq 1 : BrkLiOnReqChks BrkLiOnReqCntr BrkLiOnReqSts;
SIG_GROUP_ 1025 BrkPAtWhl 1 : BrkPAtWhlFL BrkPAtWhlFR BrkPAtWhlRL BrkPAtWhlRR;
SIG_GROUP_ 384 BrkPedlPsd 1 : BrkPedlPsdBrkPedlNotPsdSafe BrkPedlPsdBrkPedlPsd BrkPedlPsdChks BrkPedlPsdCntr BrkPedlPsdQf;
SIG_GROUP_ 483 BrkPedlrRat 1 : BrkPedlrRatPerc BrkPedlrRatQf;
SIG_GROUP_ 384 BrkPedlTrvl 1 : BrkPedlTrvlAct BrkPedlTrvlChks BrkPedlTrvlCntr BrkPedlTrvlQf BrkPedlTrvlSt BrkPedlTrvlStQf BrkPedlTrvlTar;
SIG_GROUP_ 384 BrkSysCylPMst 1 : BrkSysCylPMstAct BrkSysCylPMstActQf BrkSysCylPMstChks BrkSysCylPMstCntr BrkSysCylPMstTar BrkSysCylPMstVirt BrkSysCylPMstVirtQf;
SIG_GROUP_ 576 BrkSysSts 1 : BrkSysStsADL3BrkFallBck BrkSysStsBrkDegradation BrkSysStsBrkSysCapability BrkSysStsBrkSysModCfmd BrkSysStsChks BrkSysStsCntr;
SIG_GROUP_ 257 BrkTq 1 : BrkTqChks BrkTqCntr BrkTqQf BrkTqRgnAtAxleReReq BrkTqSts BrkTqTotReqForPt;
SIG_GROUP_ 816 BrkTracCtrlActvForWhl 1 : BrkTracCtrlActvForWhlFrntLe BrkTracCtrlActvForWhlFrntRi BrkTracCtrlActvForWhlReLe BrkTracCtrlActvForWhlReRi;
SIG_GROUP_ 949 CstCtrlActv 1 : CstCtrlActvCstCtrlEab CstCtrlActvCtrlSts1;
SIG_GROUP_ 949 DrvModEscOff 1 : DrvModEscOffChks DrvModEscOffCntr DrvModEscOffDrvModEscOff;
SIG_GROUP_ 257 DrvrBrkTqAtWhlsReqd 1 : DrvrBrkTqAtWhlsReqdChks DrvrBrkTqAtWhlsReqdCntr DrvrBrkTqAtWhlsReqdDrvrBrkTqAtWhlsReqd DrvrBrkTqAtWhlsReqdQf;
SIG_GROUP_ 384 DrvrDecelReq 1 : DrvrDecelReqChks DrvrDecelReqCntr DrvrDecelReqFloat8;
SIG_GROUP_ 997 EmgyBrkLiReq 1 : EmgyBrkLiReqChks EmgyBrkLiReqCntr EmgyBrkLiReqEmgyBrk;
SIG_GROUP_ 816 EpbLampReq 1 : EpbLampReqChks EpbLampReqCntr EpbLampReqEpbLampReq;
SIG_GROUP_ 997 EPBLockChk 1 : EPBLockChkChk EPBLockChkData0 EPBLockChkData1 EPBLockChkData2 EPBLockChkData3 EPBLockChkData4 EPBLockChkData5 EPBLockChkData6;
SIG_GROUP_ 384 EpbSts 1 : EpbStsChks EpbStsCntr EpbStsEpbSts;
SIG_GROUP_ 384 EscSt 1 : EscStChks EscStCntr EscStEscSt;
SIG_GROUP_ 257 EscVariantToDmc 1 : EscVariantToDmcChks EscVariantToDmcCntr EscVariantToDmcEscVariantToDmc;
SIG_GROUP_ 576 EscWarnIndcnReq 1 : EscWarnIndcnReqChks EscWarnIndcnReqCntr EscWarnIndcnReqEscWarnIndcnReq;
SIG_GROUP_ 257 FricEstimnFromVehDyn 1 : FricEstimnFromVehDynFricEstimnFromVehDyn FricEstimnFromVehDynQly;
SIG_GROUP_ 1129 FrntRdrSts 1 : FrntRdrStsRdrNrDetn FrntRdrStsRdrNrObj FrntRdrStsRdrStsBlkd0bin FrntRdrStsRdrStsBlkdConf FrntRdrStsRdrStsChks FrntRdrStsRdrStsCntr FrntRdrStsRdrStsDstbc FrntRdrStsRdrStsEna FrntRdrStsRdrStsFaulty FrntRdrStsRdrStsIfVersMajor FrntRdrStsRdrStsIfVersMinor FrntRdrStsRdrStsLatency FrntRdrStsRdrStsMisAlign FrntRdrStsRdrStsMissCom FrntRdrStsRdrStsSftyFlt FrntRdrStsRdrStsTiStamp FrntRdrStsRdrStsTiStampStsGlbTiBas FrntRdrStsRdrStsTiStampStsSyncToGatewy FrntRdrStsRdrStsTiStampStsTiLeap FrntRdrStsRdrStsTiStampStsTiOut FrntRdrStsRdrStsWhlSpdCmpFac;
SIG_GROUP_ 608 ImobBrkNrSerl 1 : ImobBrkNrSerl0 ImobBrkNrSerl1 ImobBrkNrSerl2 ImobBrkNrSerl3 ImobBrkNrSerl4 ImobBrkNrSerl5;
SIG_GROUP_ 257 LatCtrlReqSafe 1 : LatCtrlReqSafeChks LatCtrlReqSafeCntr LatCtrlReqSafeLatCtrlModReq LatCtrlReqSafeSteerTqReq LatCtrlReqSafeSteerWhlHptcWarnReq;
SIG_GROUP_ 257 LgtCtrlModReqSafe 1 : LgtCtrlModReqSafeChks LgtCtrlModReqSafeCntr LgtCtrlModReqSafeLgtCtrlModReqSafe LgtCtrlModReqSafeLgtFctFailr;
SIG_GROUP_ 483 LimForDecel 1 : LimForDecelChks LimForDecelCntr LimForDecelNotExcd;
SIG_GROUP_ 384 LimForJerkPosNotExcd 1 : LimForJerkPosNotExcdChks LimForJerkPosNotExcdCntr LimForJerkPosNotExcdLimForJerkPosNotExcd;
SIG_GROUP_ 1025 PitchAgGlb 1 : PitchAgGlbQf PitchAgGlbVal;
SIG_GROUP_ 402 PrkLatLgtFailr 1 : PrkLatLgtFailrChks PrkLatLgtFailrCntr PrkLatLgtFailrPrkLatLgtFailr;
SIG_GROUP_ 384 PtTq 1 : PtTqChks PtTqCntr PtTqMinReq PtTqSoftMaxReq;
SIG_GROUP_ 384 PtTqAtAxleAddReq 1 : PtTqAtAxleAddReqChks PtTqAtAxleAddReqCntr PtTqAtAxleAddReqPtTqAtAxleAddFrntReq PtTqAtAxleAddReqPtTqAtAxleAddReReq;
SIG_GROUP_ 257 PtTqAtAxleMinReq 1 : PtTqAtAxleMinReqChks PtTqAtAxleMinReqCntr PtTqAtAxleMinReqPtTqAtAxleFrntReq PtTqAtAxleMinReqPtTqAtAxleReReq;
SIG_GROUP_ 384 PtTqHardMax 1 : PtTqHardMaxChks PtTqHardMaxCntr PtTqHardMaxGrdtNeg PtTqHardMaxGrdtPos PtTqHardMaxReq;
SIG_GROUP_ 384 PtTqSetSafe 1 : PtTqSetSafeChks PtTqSetSafeCntr PtTqSetSafeGrdtNeg PtTqSetSafeGrdtPos PtTqSetSafeReq;
SIG_GROUP_ 257 PtTqSoftMaxGenn2 1 : PtTqSoftMaxGenn2Allwd PtTqSoftMaxGenn2AllwdChks PtTqSoftMaxGenn2AllwdCntr;
SIG_GROUP_ 1129 ReSideRdrLeSts 1 : ReSideRdrLeStsRdrNrDetn ReSideRdrLeStsRdrNrObj ReSideRdrLeStsRdrStsBlkd0bin ReSideRdrLeStsRdrStsBlkdConf ReSideRdrLeStsRdrStsChks ReSideRdrLeStsRdrStsCntr ReSideRdrLeStsRdrStsDstbc ReSideRdrLeStsRdrStsEna ReSideRdrLeStsRdrStsFaulty ReSideRdrLeStsRdrStsIfVersMajor ReSideRdrLeStsRdrStsIfVersMinor ReSideRdrLeStsRdrStsLatency ReSideRdrLeStsRdrStsMisAlign ReSideRdrLeStsRdrStsMissCom ReSideRdrLeStsRdrStsSftyFlt ReSideRdrLeStsRdrStsTiStamp ReSideRdrLeStsRdrStsTiStampStsGlbTiBas ReSideRdrLeStsRdrStsTiStampStsSyncToGatewy ReSideRdrLeStsRdrStsTiStampStsTiLeap ReSideRdrLeStsRdrStsTiStampStsTiOut ReSideRdrLeStsRdrStsWhlSpdCmpFac;
SIG_GROUP_ 1129 ReSideRdrRiSts 1 : ReSideRdrRiStsRdrNrDetn ReSideRdrRiStsRdrNrObj ReSideRdrRiStsRdrStsBlkd0bin ReSideRdrRiStsRdrStsBlkdConf ReSideRdrRiStsRdrStsChks ReSideRdrRiStsRdrStsCntr ReSideRdrRiStsRdrStsDstbc ReSideRdrRiStsRdrStsEna ReSideRdrRiStsRdrStsFaulty ReSideRdrRiStsRdrStsIfVersMajor ReSideRdrRiStsRdrStsIfVersMinor ReSideRdrRiStsRdrStsLatency ReSideRdrRiStsRdrStsMisAlign ReSideRdrRiStsRdrStsMissCom ReSideRdrRiStsRdrStsSftyFlt ReSideRdrRiStsRdrStsTiStamp ReSideRdrRiStsRdrStsTiStampStsGlbTiBas ReSideRdrRiStsRdrStsTiStampStsSyncToGatewy ReSideRdrRiStsRdrStsTiStampStsTiLeap ReSideRdrRiStsRdrStsTiStampStsTiOut ReSideRdrRiStsRdrStsWhlSpdCmpFac;
SIG_GROUP_ 384 RoadIncln 1 : RoadInclnQly RoadInclnRoadIncln;
SIG_GROUP_ 1025 RoadLoadNom 1 : RoadLoadNomCoeff0 RoadLoadNomCoeff1 RoadLoadNomCoeff2 RoadLoadNomCoeffSts;
SIG_GROUP_ 816 RollAgGlb 1 : RollAgGlbQf RollAgGlbVal;
SIG_GROUP_ 384 SpdRotlForWhlsAtAxleFrnt 1 : SpdRotlForWhlsAtAxleFrntChks SpdRotlForWhlsAtAxleFrntCntr SpdRotlForWhlsAtAxleFrntSpdRotlForWhlsAtAxleFrnt;
SIG_GROUP_ 402 StandStillMgrStsForHld 1 : StandStillMgrStsForHld1 StandStillMgrStsForHldChks StandStillMgrStsForHldCntr;
SIG_GROUP_ 1025 StandStillMgrStsForHldByBrk 1 : StandStillMgrStsForHldByBrkChks StandStillMgrStsForHldByBrkCntr StandStillMgrStsForHldByBrkStandStillMgrStsForHld1;
SIG_GROUP_ 257 StcStsToDmc 1 : StcStsToDmcChks StcStsToDmcCntr StcStsToDmcEngRotTarSpdDMCFrnt StcStsToDmcEngRotTarSpdDMCRear StcStsToDmcFrnt StcStsToDmcRear;
SIG_GROUP_ 483 SuspPosnVertAg 1 : SuspPosnVertAgGenQf SuspPosnVertAgSuspPosnVertAg;
SIG_GROUP_ 483 SuspPosnVertLvl 1 : SuspPosnVertLvlFrnt SuspPosnVertLvlFrntQf SuspPosnVertLvlRe SuspPosnVertLvlReQf;
SIG_GROUP_ 98 VehDynCtrlStsForALgtCmft 1 : VehDynCtrlStsForALgtCmftVehDynCtrlStsChks VehDynCtrlStsForALgtCmftVehDynCtrlStsCntr VehDynCtrlStsForALgtCmftVehDynCtrlStsDend VehDynCtrlStsForALgtCmftVehDynCtrlStsForBrkActv VehDynCtrlStsForALgtCmftVehDynCtrlStsForBrkPrecActv VehDynCtrlStsForALgtCmftVehDynCtrlStsForStandStillMgrForPark VehDynCtrlStsForALgtCmftVehDynCtrlStsForWhlBrkWrm VehDynCtrlStsForALgtCmftVehDynCtrlStsNotEna;
SIG_GROUP_ 402 VehMNom 1 : VehMNomTrlrM VehMNomVehM VehMNomVehMQly;
SIG_GROUP_ 98 VehMtnSt 1 : VehMtnStChks VehMtnStCntr VehMtnStVehMtnSt;
SIG_GROUP_ 544 VehObjforADB1 1 : VehObjforADB1AdbAbsDist VehObjforADB1AdbClassn VehObjforADB1AdbHozlAgLe VehObjforADB1AdbHozlAgRi VehObjforADB1AdbObjDir VehObjforADB1AdbObjHozlAgSpdLe VehObjforADB1AdbObjHozlAgSpdRi VehObjforADB1AdbTrkInfo VehObjforADB1AdbVertAg;
SIG_GROUP_ 544 VehObjforADB2 1 : VehObjforADB2AdbAbsDist VehObjforADB2AdbClassn VehObjforADB2AdbHozlAgLe VehObjforADB2AdbHozlAgRi VehObjforADB2AdbObjDir VehObjforADB2AdbObjHozlAgSpdLe VehObjforADB2AdbObjHozlAgSpdRi VehObjforADB2AdbTrkInfo VehObjforADB2AdbVertAg;
SIG_GROUP_ 544 VehObjforADB3 1 : VehObjforADB3AdbAbsDist VehObjforADB3AdbClassn VehObjforADB3AdbHozlAgLe VehObjforADB3AdbHozlAgRi VehObjforADB3AdbObjDir VehObjforADB3AdbObjHozlAgSpdLe VehObjforADB3AdbObjHozlAgSpdRi VehObjforADB3AdbTrkInfo VehObjforADB3AdbVertAg;
SIG_GROUP_ 544 VehObjforADB4 1 : VehObjforADB4AdbAbsDist VehObjforADB4AdbClassn VehObjforADB4AdbHozlAgLe VehObjforADB4AdbHozlAgRi VehObjforADB4AdbObjDir VehObjforADB4AdbObjHozlAgSpdLe VehObjforADB4AdbObjHozlAgSpdRi VehObjforADB4AdbTrkInfo VehObjforADB4AdbVertAg;
SIG_GROUP_ 544 VehObjforADB5 1 : VehObjforADB5AdbAbsDist VehObjforADB5AdbClassn VehObjforADB5AdbHozlAgLe VehObjforADB5AdbHozlAgRi VehObjforADB5AdbObjDir VehObjforADB5AdbObjHozlAgSpdLe VehObjforADB5AdbObjHozlAgSpdRi VehObjforADB5AdbTrkInfo VehObjforADB5AdbVertAg;
SIG_GROUP_ 544 VehObjforADB6 1 : VehObjforADB6AdbAbsDist VehObjforADB6AdbClassn VehObjforADB6AdbHozlAgLe VehObjforADB6AdbHozlAgRi VehObjforADB6AdbObjDir VehObjforADB6AdbObjHozlAgSpdLe VehObjforADB6AdbObjHozlAgSpdRi VehObjforADB6AdbTrkInfo VehObjforADB6AdbVertAg;
SIG_GROUP_ 544 VehObjforADB7 1 : VehObjforADB7AdbAbsDist VehObjforADB7AdbClassn VehObjforADB7AdbHozlAgLe VehObjforADB7AdbHozlAgRi VehObjforADB7AdbObjDir VehObjforADB7AdbObjHozlAgSpdLe VehObjforADB7AdbObjHozlAgSpdRi VehObjforADB7AdbTrkInfo VehObjforADB7AdbVertAg;
SIG_GROUP_ 544 VehObjforADB8 1 : VehObjforADB8AdbAbsDist VehObjforADB8AdbClassn VehObjforADB8AdbHozlAgLe VehObjforADB8AdbHozlAgRi VehObjforADB8AdbObjDir VehObjforADB8AdbObjHozlAgSpdLe VehObjforADB8AdbObjHozlAgSpdRi VehObjforADB8AdbTrkInfo VehObjforADB8AdbVertAg;
SIG_GROUP_ 98 VehSpdLgt 1 : VehSpdLgtA VehSpdLgtChks VehSpdLgtCntr VehSpdLgtQf;
SIG_GROUP_ 402 VehV 1 : VehVLat VehVLatQf VehVLgt VehVLgtQf;
SIG_GROUP_ 1345 VFCVectorASDM 1 : VFCVectorASDMBlockID VFCVectorASDMVFCid0 VFCVectorASDMVFCid1 VFCVectorASDMVFCid10 VFCVectorASDMVFCid11 VFCVectorASDMVFCid12 VFCVectorASDMVFCid13 VFCVectorASDMVFCid14 VFCVectorASDMVFCid15 VFCVectorASDMVFCid16 VFCVectorASDMVFCid17 VFCVectorASDMVFCid18 VFCVectorASDMVFCid19 VFCVectorASDMVFCid2 VFCVectorASDMVFCid20 VFCVectorASDMVFCid21 VFCVectorASDMVFCid22 VFCVectorASDMVFCid23 VFCVectorASDMVFCid24 VFCVectorASDMVFCid25 VFCVectorASDMVFCid26 VFCVectorASDMVFCid27 VFCVectorASDMVFCid28 VFCVectorASDMVFCid29 VFCVectorASDMVFCid3 VFCVectorASDMVFCid30 VFCVectorASDMVFCid31 VFCVectorASDMVFCid32 VFCVectorASDMVFCid33 VFCVectorASDMVFCid34 VFCVectorASDMVFCid35 VFCVectorASDMVFCid36 VFCVectorASDMVFCid37 VFCVectorASDMVFCid38 VFCVectorASDMVFCid39 VFCVectorASDMVFCid4 VFCVectorASDMVFCid40 VFCVectorASDMVFCid41 VFCVectorASDMVFCid42 VFCVectorASDMVFCid43 VFCVectorASDMVFCid44 VFCVectorASDMVFCid45 VFCVectorASDMVFCid46 VFCVectorASDMVFCid47 VFCVectorASDMVFCid48 VFCVectorASDMVFCid49 VFCVectorASDMVFCid5 VFCVectorASDMVFCid50 VFCVectorASDMVFCid51 VFCVectorASDMVFCid52 VFCVectorASDMVFCid53 VFCVectorASDMVFCid54 VFCVectorASDMVFCid55 VFCVectorASDMVFCid56 VFCVectorASDMVFCid57 VFCVectorASDMVFCid58 VFCVectorASDMVFCid59 VFCVectorASDMVFCid6 VFCVectorASDMVFCid60 VFCVectorASDMVFCid61 VFCVectorASDMVFCid7 VFCVectorASDMVFCid8 VFCVectorASDMVFCid9;
SIG_GROUP_ 402 WhlDirRotlFrnt 1 : WhlDirRotlFrntChks WhlDirRotlFrntCntr WhlDirRotlFrntLe WhlDirRotlFrntRi;
SIG_GROUP_ 402 WhlDirRotlRe 1 : WhlDirRotlReChks WhlDirRotlReCntr WhlDirRotlReLe WhlDirRotlReRi;
SIG_GROUP_ 402 WhlFastSpdSafe 1 : WhlFastSpdSafeA WhlFastSpdSafeChks WhlFastSpdSafeCntr WhlFastSpdSafeQF;
SIG_GROUP_ 402 WhlRotToothCntr 1 : WhlRotToothCntrChks WhlRotToothCntrCntr WhlRotToothCntrFrntLe WhlRotToothCntrFrntRi WhlRotToothCntrReLe WhlRotToothCntrReRi;
SIG_GROUP_ 483 WhlSpdCalcALgt 1 : WhlSpdCalcALgtALgt WhlSpdCalcALgtChks WhlSpdCalcALgtCntr;
SIG_GROUP_ 402 WhlSpdCircumlFrnt 1 : WhlSpdCircumlFrntChks WhlSpdCircumlFrntCntr WhlSpdCircumlFrntLe WhlSpdCircumlFrntLeQf WhlSpdCircumlFrntRiQf WhlSpdCircumlFrntWhlSpdCircumlFrntRi;
SIG_GROUP_ 402 WhlSpdCircumlRe 1 : WhlSpdCircumlReChks WhlSpdCircumlReCntr WhlSpdCircumlReLe WhlSpdCircumlReLeQf WhlSpdCircumlReRi WhlSpdCircumlReRiQf;
SIG_GROUP_ 98 WhlVAgrFrnt 1 : WhlVAgrFrntLe WhlVAgrFrntLeQf WhlVAgrFrntRi WhlVAgrFrntRiQf;
SIG_GROUP_ 98 WhlVAgrRe 1 : WhlVAgrReLe WhlVAgrReLeQf WhlVAgrReRi WhlVAgrReRiQf;
